[part 1 of 5: packages /MICROSAR/Dem_swc/DataTypes to /MICROSAR/Dem_swc/ComponentTypes]
AUTOSAR XML (schema 4-2-1)
package /MICROSAR/Dem_swc/DataTypes
  23 x impl type:
    Dem_EventIdType: range raw 1..65535, implementation-data-type=uint16
    Dem_RatioIdType: range raw 1..65535, implementation-data-type=uint16
    Dem_DTCStatusMaskType: range raw 0..255, implementation-data-type=uint8
    Dem_OperationCycleIdType: range raw 0..255, implementation-data-type=uint8
    Dem_DTCGroupType: range raw 0..16777215, implementation-data-type=uint32
    Dem_EventStatusType:
      compu {0=DEM_EVENT_STATUS_PASSED, 1=DEM_EVENT_STATUS_FAILED, 2=DEM_EVENT_STATUS_PREPASSED, 3=DEM_EVENT_STATUS_PREFAILED, 4=DEM_EVENT_STATUS_FDC_THRESHOLD_REACHED, 5=DEM_EVENT_STATUS_PASSED_CONDITIONS_NOT_FULFILLED, 6=DEM_EVENT_STATUS_FAILED_CONDITIONS_NOT_FULFILLED, 7=DEM_EVENT_STATUS_PREPASSED_CONDITIONS_NOT_FULFILLED, 8=DEM_EVENT_STATUS_PREFAILED_CONDITIONS_NOT_FULFILLED}
      range raw 0..255
      implementation-data-type=uint8
    Dem_InitMonitorReasonType: compu {1=DEM_INIT_MONITOR_CLEAR, 2=DEM_INIT_MONITOR_RESTART, 3=DEM_INIT_MONITOR_REENABLED, 4=DEM_INIT_MONITOR_STORAGE_REENABLED}, range raw 0..255, implementation-data-type=uint8
    Dem_DTCOriginType:
      compu {1=DEM_DTC_ORIGIN_PRIMARY_MEMORY, 2=DEM_DTC_ORIGIN_MIRROR_MEMORY, 3=DEM_DTC_ORIGIN_PERMANENT_MEMORY, 4=DEM_DTC_ORIGIN_OBD_RELEVANT_MEMORY, 5=DEM_DTC_ORIGIN_SECONDARY_MEMORY, 5=DEM_DTC_ORIGIN_USERDEFINED_MEMORY_10, 5=DEM_DTC_ORIGIN_USERDEFINED_MEMORY_11, 5=DEM_DTC_ORIGIN_USERDEFINED_MEMORY_12, 5=DEM_DTC_ORIGIN_USERDEFINED_MEMORY_13, 5=DEM_DTC_ORIGIN_USERDEFINED_MEMORY_14, 5=DEM_DTC_ORIGIN_USERDEFINED_MEMORY_15, 5=DEM_DTC_ORIGIN_USERDEFINED_MEMORY_16, 5=DEM_DTC_ORIGIN_USERDEFINED_MEMORY_17, 5=DEM_DTC_ORIGIN_USERDEFINED_MEMORY_18, 5=DEM_DTC_ORIGIN_USERDEFINED_MEMORY_19, 5=DEM_DTC_ORIGIN_USERDEFINED_MEMORY_1A, 5=DEM_DTC_ORIGIN_USERDEFINED_MEMORY_1B, 5=DEM_DTC_ORIGIN_USERDEFINED_MEMORY_1C, 5=DEM_DTC_ORIGIN_USERDEFINED_MEMORY_1D, 5=DEM_DTC_ORIGIN_USERDEFINED_MEMORY_1E, 5=DEM_DTC_ORIGIN_USERDEFINED_MEMORY_1F, 5=DEM_DTC_ORIGIN_USERDEFINED_MEMORY_20, 5=DEM_DTC_ORIGIN_USERDEFINED_MEMORY_21, 5=DEM_DTC_ORIGIN_USERDEFINED_MEMORY_22, 5=DEM_DTC_ORIGIN_USERDEFINED_MEMORY_23, 5=DEM_DTC_ORIGIN_USERDEFINED_MEMORY_24, 5=DEM_DTC_ORIGIN_USERDEFINED_MEMORY_25, 5=DEM_DTC_ORIGIN_USERDEFINED_MEMORY_26, 5=DEM_DTC_ORIGIN_USERDEFINED_MEMORY_27, 5=DEM_DTC_ORIGIN_USERDEFINED_MEMORY_28, 5=DEM_DTC_ORIGIN_USERDEFINED_MEMORY_29, 5=DEM_DTC_ORIGIN_USERDEFINED_MEMORY_2A, 5=DEM_DTC_ORIGIN_USERDEFINED_MEMORY_2B, 5=DEM_DTC_ORIGIN_USERDEFINED_MEMORY_2C, 5=DEM_DTC_ORIGIN_USERDEFINED_MEMORY_2D, 5=DEM_DTC_ORIGIN_USERDEFINED_MEMORY_2E, 5=DEM_DTC_ORIGIN_USERDEFINED_MEMORY_2F, 5=DEM_DTC_ORIGIN_USERDEFINED_MEMORY_30, 5=DEM_DTC_ORIGIN_USERDEFINED_MEMORY_31, 5=DEM_DTC_ORIGIN_USERDEFINED_MEMORY_32, 5=DEM_DTC_ORIGIN_USERDEFINED_MEMORY_33, 5=DEM_DTC_ORIGIN_USERDEFINED_MEMORY_34, 5=DEM_DTC_ORIGIN_USERDEFINED_MEMORY_35, 5=DEM_DTC_ORIGIN_USERDEFINED_MEMORY_36, 5=DEM_DTC_ORIGIN_USERDEFINED_MEMORY_37, 5=DEM_DTC_ORIGIN_USERDEFINED_MEMORY_38, 5=DEM_DTC_ORIGIN_USERDEFINED_MEMORY_39, 5=DEM_DTC_ORIGIN_USERDEFINED_MEMORY_3A, 5=DEM_DTC_ORIGIN_USERDEFINED_MEMORY_3B, 5=DEM_DTC_ORIGIN_USERDEFINED_MEMORY_3C, 5=DEM_DTC_ORIGIN_USERDEFINED_MEMORY_3D, 5=DEM_DTC_ORIGIN_USERDEFINED_MEMORY_3E, 5=DEM_DTC_ORIGIN_USERDEFINED_MEMORY_3F, 5=DEM_DTC_ORIGIN_USERDEFINED_MEMORY_40, 5=DEM_DTC_ORIGIN_USERDEFINED_MEMORY_41, 5=DEM_DTC_ORIGIN_USERDEFINED_MEMORY_42, 5=DEM_DTC_ORIGIN_USERDEFINED_MEMORY_43, 5=DEM_DTC_ORIGIN_USERDEFINED_MEMORY_44, 5=DEM_DTC_ORIGIN_USERDEFINED_MEMORY_45, 5=DEM_DTC_ORIGIN_USERDEFINED_MEMORY_46, 5=DEM_DTC_ORIGIN_USERDEFINED_MEMORY_47, 5=DEM_DTC_ORIGIN_USERDEFINED_MEMORY_48, 5=DEM_DTC_ORIGIN_USERDEFINED_MEMORY_49, 5=DEM_DTC_ORIGIN_USERDEFINED_MEMORY_4A, 5=DEM_DTC_ORIGIN_USERDEFINED_MEMORY_4B, 5=DEM_DTC_ORIGIN_USERDEFINED_MEMORY_4C, 5=DEM_DTC_ORIGIN_USERDEFINED_MEMORY_4D, 5=DEM_DTC_ORIGIN_USERDEFINED_MEMORY_4E, 5=DEM_DTC_ORIGIN_USERDEFINED_MEMORY_4F, 5=DEM_DTC_ORIGIN_USERDEFINED_MEMORY_50, 5=DEM_DTC_ORIGIN_USERDEFINED_MEMORY_51, 5=DEM_DTC_ORIGIN_USERDEFINED_MEMORY_52, 5=DEM_DTC_ORIGIN_USERDEFINED_MEMORY_53, 5=DEM_DTC_ORIGIN_USERDEFINED_MEMORY_54, 5=DEM_DTC_ORIGIN_USERDEFINED_MEMORY_55, 5=DEM_DTC_ORIGIN_USERDEFINED_MEMORY_56, 5=DEM_DTC_ORIGIN_USERDEFINED_MEMORY_57, 5=DEM_DTC_ORIGIN_USERDEFINED_MEMORY_58, 5=DEM_DTC_ORIGIN_USERDEFINED_MEMORY_59, 5=DEM_DTC_ORIGIN_USERDEFINED_MEMORY_5A, 5=DEM_DTC_ORIGIN_USERDEFINED_MEMORY_5B, 5=DEM_DTC_ORIGIN_USERDEFINED_MEMORY_5C, 5=DEM_DTC_ORIGIN_USERDEFINED_MEMORY_5D, 5=DEM_DTC_ORIGIN_USERDEFINED_MEMORY_5E, 5=DEM_DTC_ORIGIN_USERDEFINED_MEMORY_5F, 5=DEM_DTC_ORIGIN_USERDEFINED_MEMORY_60, 5=DEM_DTC_ORIGIN_USERDEFINED_MEMORY_61, 5=DEM_DTC_ORIGIN_USERDEFINED_MEMORY_62, 5=DEM_DTC_ORIGIN_USERDEFINED_MEMORY_63, 5=DEM_DTC_ORIGIN_USERDEFINED_MEMORY_64, 5=DEM_DTC_ORIGIN_USERDEFINED_MEMORY_65, 5=DEM_DTC_ORIGIN_USERDEFINED_MEMORY_66, 5=DEM_DTC_ORIGIN_USERDEFINED_MEMORY_67, 5=DEM_DTC_ORIGIN_USERDEFINED_MEMORY_68, 5=DEM_DTC_ORIGIN_USERDEFINED_MEMORY_69, 5=DEM_DTC_ORIGIN_USERDEFINED_MEMORY_6A, 5=DEM_DTC_ORIGIN_USERDEFINED_MEMORY_6B, 5=DEM_DTC_ORIGIN_USERDEFINED_MEMORY_6C, 5=DEM_DTC_ORIGIN_USERDEFINED_MEMORY_6D, 5=DEM_DTC_ORIGIN_USERDEFINED_MEMORY_6E, 5=DEM_DTC_ORIGIN_USERDEFINED_MEMORY_6F, 5=DEM_DTC_ORIGIN_USERDEFINED_MEMORY_70, 5=DEM_DTC_ORIGIN_USERDEFINED_MEMORY_71, 5=DEM_DTC_ORIGIN_USERDEFINED_MEMORY_72, 5=DEM_DTC_ORIGIN_USERDEFINED_MEMORY_73, 5=DEM_DTC_ORIGIN_USERDEFINED_MEMORY_74, 5=DEM_DTC_ORIGIN_USERDEFINED_MEMORY_75, 5=DEM_DTC_ORIGIN_USERDEFINED_MEMORY_76, 5=DEM_DTC_ORIGIN_USERDEFINED_MEMORY_77, 5=DEM_DTC_ORIGIN_USERDEFINED_MEMORY_78, 5=DEM_DTC_ORIGIN_USERDEFINED_MEMORY_79, 5=DEM_DTC_ORIGIN_USERDEFINED_MEMORY_7A, 5=DEM_DTC_ORIGIN_USERDEFINED_MEMORY_7B, 5=DEM_DTC_ORIGIN_USERDEFINED_MEMORY_7C, 5=DEM_DTC_ORIGIN_USERDEFINED_MEMORY_7D, 5=DEM_DTC_ORIGIN_USERDEFINED_MEMORY_7E, 5=DEM_DTC_ORIGIN_USERDEFINED_MEMORY_7F, 5=DEM_DTC_ORIGIN_USERDEFINED_MEMORY_80, 5=DEM_DTC_ORIGIN_USERDEFINED_MEMORY_81, 5=DEM_DTC_ORIGIN_USERDEFINED_MEMORY_82, 5=DEM_DTC_ORIGIN_USERDEFINED_MEMORY_83, 5=DEM_DTC_ORIGIN_USERDEFINED_MEMORY_84, 5=DEM_DTC_ORIGIN_USERDEFINED_MEMORY_85, 5=DEM_DTC_ORIGIN_USERDEFINED_MEMORY_86, 5=DEM_DTC_ORIGIN_USERDEFINED_MEMORY_87, 5=DEM_DTC_ORIGIN_USERDEFINED_MEMORY_88, 5=DEM_DTC_ORIGIN_USERDEFINED_MEMORY_89, 5=DEM_DTC_ORIGIN_USERDEFINED_MEMORY_8A, 5=DEM_DTC_ORIGIN_USERDEFINED_MEMORY_8B, 5=DEM_DTC_ORIGIN_USERDEFINED_MEMORY_8C, 5=DEM_DTC_ORIGIN_USERDEFINED_MEMORY_8D, 5=DEM_DTC_ORIGIN_USERDEFINED_MEMORY_8E, 5=DEM_DTC_ORIGIN_USERDEFINED_MEMORY_8F, 5=DEM_DTC_ORIGIN_USERDEFINED_MEMORY_90, 5=DEM_DTC_ORIGIN_USERDEFINED_MEMORY_91, 5=DEM_DTC_ORIGIN_USERDEFINED_MEMORY_92, 5=DEM_DTC_ORIGIN_USERDEFINED_MEMORY_93, 5=DEM_DTC_ORIGIN_USERDEFINED_MEMORY_94, 5=DEM_DTC_ORIGIN_USERDEFINED_MEMORY_95, 5=DEM_DTC_ORIGIN_USERDEFINED_MEMORY_96, 5=DEM_DTC_ORIGIN_USERDEFINED_MEMORY_97, 5=DEM_DTC_ORIGIN_USERDEFINED_MEMORY_98, 5=DEM_DTC_ORIGIN_USERDEFINED_MEMORY_99, 5=DEM_DTC_ORIGIN_USERDEFINED_MEMORY_9A, 5=DEM_DTC_ORIGIN_USERDEFINED_MEMORY_9B, 5=DEM_DTC_ORIGIN_USERDEFINED_MEMORY_9C, 5=DEM_DTC_ORIGIN_USERDEFINED_MEMORY_9D, 5=DEM_DTC_ORIGIN_USERDEFINED_MEMORY_9E, 5=DEM_DTC_ORIGIN_USERDEFINED_MEMORY_9F, 5=DEM_DTC_ORIGIN_USERDEFINED_MEMORY_A0, 5=DEM_DTC_ORIGIN_USERDEFINED_MEMORY_A1, 5=DEM_DTC_ORIGIN_USERDEFINED_MEMORY_A2, 5=DEM_DTC_ORIGIN_USERDEFINED_MEMORY_A3, 5=DEM_DTC_ORIGIN_USERDEFINED_MEMORY_A4, 5=DEM_DTC_ORIGIN_USERDEFINED_MEMORY_A5, 5=DEM_DTC_ORIGIN_USERDEFINED_MEMORY_A6, 5=DEM_DTC_ORIGIN_USERDEFINED_MEMORY_A7, 5=DEM_DTC_ORIGIN_USERDEFINED_MEMORY_A8, 5=DEM_DTC_ORIGIN_USERDEFINED_MEMORY_A9, 5=DEM_DTC_ORIGIN_USERDEFINED_MEMORY_AA, 5=DEM_DTC_ORIGIN_USERDEFINED_MEMORY_AB, 5=DEM_DTC_ORIGIN_USERDEFINED_MEMORY_AC, 5=DEM_DTC_ORIGIN_USERDEFINED_MEMORY_AD, 5=DEM_DTC_ORIGIN_USERDEFINED_MEMORY_AE, 5=DEM_DTC_ORIGIN_USERDEFINED_MEMORY_AF, 5=DEM_DTC_ORIGIN_USERDEFINED_MEMORY_B0, 5=DEM_DTC_ORIGIN_USERDEFINED_MEMORY_B1, 5=DEM_DTC_ORIGIN_USERDEFINED_MEMORY_B2, 5=DEM_DTC_ORIGIN_USERDEFINED_MEMORY_B3, 5=DEM_DTC_ORIGIN_USERDEFINED_MEMORY_B4, 5=DEM_DTC_ORIGIN_USERDEFINED_MEMORY_B5, 5=DEM_DTC_ORIGIN_USERDEFINED_MEMORY_B6, 5=DEM_DTC_ORIGIN_USERDEFINED_MEMORY_B7, 5=DEM_DTC_ORIGIN_USERDEFINED_MEMORY_B8, 5=DEM_DTC_ORIGIN_USERDEFINED_MEMORY_B9, 5=DEM_DTC_ORIGIN_USERDEFINED_MEMORY_BA, 5=DEM_DTC_ORIGIN_USERDEFINED_MEMORY_BB, 5=DEM_DTC_ORIGIN_USERDEFINED_MEMORY_BC, 5=DEM_DTC_ORIGIN_USERDEFINED_MEMORY_BD, 5=DEM_DTC_ORIGIN_USERDEFINED_MEMORY_BE, 5=DEM_DTC_ORIGIN_USERDEFINED_MEMORY_BF, 5=DEM_DTC_ORIGIN_USERDEFINED_MEMORY_C0, 5=DEM_DTC_ORIGIN_USERDEFINED_MEMORY_C1, 5=DEM_DTC_ORIGIN_USERDEFINED_MEMORY_C2, 5=DEM_DTC_ORIGIN_USERDEFINED_MEMORY_C3, 5=DEM_DTC_ORIGIN_USERDEFINED_MEMORY_C4, 5=DEM_DTC_ORIGIN_USERDEFINED_MEMORY_C5, 5=DEM_DTC_ORIGIN_USERDEFINED_MEMORY_C6, 5=DEM_DTC_ORIGIN_USERDEFINED_MEMORY_C7, 5=DEM_DTC_ORIGIN_USERDEFINED_MEMORY_C8, 5=DEM_DTC_ORIGIN_USERDEFINED_MEMORY_C9, 5=DEM_DTC_ORIGIN_USERDEFINED_MEMORY_CA, 5=DEM_DTC_ORIGIN_USERDEFINED_MEMORY_CB, 5=DEM_DTC_ORIGIN_USERDEFINED_MEMORY_CC, 5=DEM_DTC_ORIGIN_USERDEFINED_MEMORY_CD, 5=DEM_DTC_ORIGIN_USERDEFINED_MEMORY_CE, 5=DEM_DTC_ORIGIN_USERDEFINED_MEMORY_CF, 5=DEM_DTC_ORIGIN_USERDEFINED_MEMORY_D0, 5=DEM_DTC_ORIGIN_USERDEFINED_MEMORY_D1, 5=DEM_DTC_ORIGIN_USERDEFINED_MEMORY_D2, 5=DEM_DTC_ORIGIN_USERDEFINED_MEMORY_D3, 5=DEM_DTC_ORIGIN_USERDEFINED_MEMORY_D4, 5=DEM_DTC_ORIGIN_USERDEFINED_MEMORY_D5, 5=DEM_DTC_ORIGIN_USERDEFINED_MEMORY_D6, 5=DEM_DTC_ORIGIN_USERDEFINED_MEMORY_D7, 5=DEM_DTC_ORIGIN_USERDEFINED_MEMORY_D8, 5=DEM_DTC_ORIGIN_USERDEFINED_MEMORY_D9, 5=DEM_DTC_ORIGIN_USERDEFINED_MEMORY_DA, 5=DEM_DTC_ORIGIN_USERDEFINED_MEMORY_DB, 5=DEM_DTC_ORIGIN_USERDEFINED_MEMORY_DC, 5=DEM_DTC_ORIGIN_USERDEFINED_MEMORY_DD, 5=DEM_DTC_ORIGIN_USERDEFINED_MEMORY_DE, 5=DEM_DTC_ORIGIN_USERDEFINED_MEMORY_DF, 5=DEM_DTC_ORIGIN_USERDEFINED_MEMORY_E0, 5=DEM_DTC_ORIGIN_USERDEFINED_MEMORY_E1, 5=DEM_DTC_ORIGIN_USERDEFINED_MEMORY_E2, 5=DEM_DTC_ORIGIN_USERDEFINED_MEMORY_E3, 5=DEM_DTC_ORIGIN_USERDEFINED_MEMORY_E4, 5=DEM_DTC_ORIGIN_USERDEFINED_MEMORY_E5, 5=DEM_DTC_ORIGIN_USERDEFINED_MEMORY_E6, 5=DEM_DTC_ORIGIN_USERDEFINED_MEMORY_E7, 5=DEM_DTC_ORIGIN_USERDEFINED_MEMORY_E8, 5=DEM_DTC_ORIGIN_USERDEFINED_MEMORY_E9, 5=DEM_DTC_ORIGIN_USERDEFINED_MEMORY_EA, 5=DEM_DTC_ORIGIN_USERDEFINED_MEMORY_EB, 5=DEM_DTC_ORIGIN_USERDEFINED_MEMORY_EC, 5=DEM_DTC_ORIGIN_USERDEFINED_MEMORY_ED, 5=DEM_DTC_ORIGIN_USERDEFINED_MEMORY_EE, 5=DEM_DTC_ORIGIN_USERDEFINED_MEMORY_EF, 5=DEM_DTC_ORIGIN_USERDEFINED_MEMORY_F0, 5=DEM_DTC_ORIGIN_USERDEFINED_MEMORY_F1, 5=DEM_DTC_ORIGIN_USERDEFINED_MEMORY_F2, 5=DEM_DTC_ORIGIN_USERDEFINED_MEMORY_F3, 5=DEM_DTC_ORIGIN_USERDEFINED_MEMORY_F4, 5=DEM_DTC_ORIGIN_USERDEFINED_MEMORY_F5, 5=DEM_DTC_ORIGIN_USERDEFINED_MEMORY_F6, 5=DEM_DTC_ORIGIN_USERDEFINED_MEMORY_F7, 5=DEM_DTC_ORIGIN_USERDEFINED_MEMORY_F8, 5=DEM_DTC_ORIGIN_USERDEFINED_MEMORY_F9, 5=DEM_DTC_ORIGIN_USERDEFINED_MEMORY_FA, 5=DEM_DTC_ORIGIN_USERDEFINED_MEMORY_FB, 5=DEM_DTC_ORIGIN_USERDEFINED_MEMORY_FC, 5=DEM_DTC_ORIGIN_USERDEFINED_MEMORY_FD, 5=DEM_DTC_ORIGIN_USERDEFINED_MEMORY_FE, 5=DEM_DTC_ORIGIN_USERDEFINED_MEMORY_FF}
      range raw 0..65535
      implementation-data-type=uint16
    Dem_DTCFormatType: compu {0=DEM_DTC_FORMAT_OBD, 1=DEM_DTC_FORMAT_UDS, 2=DEM_DTC_FORMAT_J1939}, range raw 0..255, implementation-data-type=uint8
    Dem_OperationCycleStateType: compu {0=DEM_CYCLE_STATE_START, 1=DEM_CYCLE_STATE_END}, range raw 0..255, implementation-data-type=uint8
    Dem_IndicatorStatusType: compu {0=DEM_INDICATOR_OFF, 1=DEM_INDICATOR_CONTINUOUS, 2=DEM_INDICATOR_BLINKING, 3=DEM_INDICATOR_BLINK_CONT, 4=DEM_INDICATOR_SLOW_FLASH, 5=DEM_INDICATOR_FAST_FLASH, 6=DEM_INDICATOR_ON_DEMAND, 7=DEM_INDICATOR_SHORT}, range raw 0..255, implementation-data-type=uint8
    Dem_DTCKindType: compu {1=DEM_DTC_KIND_ALL_DTCS, 2=DEM_DTC_KIND_EMISSION_REL_DTCS}, range raw 0..255, implementation-data-type=uint8
    Dem_IumprDenomCondIdType: compu {1=DEM_IUMPR_GENERAL_DENOMINATOR, 2=DEM_IUMPR_DEN_COND_COLDSTART, 3=DEM_IUMPR_DEN_COND_EVAP, 4=DEM_IUMPR_DEN_COND_500MI}, range raw 0..255, implementation-data-type=uint8
    Dem_IumprDenomCondStatusType: compu {0=DEM_IUMPR_DEN_STATUS_NOT_REACHED, 1=DEM_IUMPR_DEN_STATUS_REACHED, 2=DEM_IUMPR_DEN_STATUS_INHIBITED}, range raw 0..255, implementation-data-type=uint8
    Dem_DebounceResetStatusType: compu {0=DEM_DEBOUNCE_STATUS_FREEZE, 1=DEM_DEBOUNCE_STATUS_RESET}, range raw 0..255, implementation-data-type=uint8
    Dem_IumprReadinessGroupType:
      compu {0=DEM_IUMPR_BOOSTPRS, 1=DEM_IUMPR_CAT1, 2=DEM_IUMPR_CAT2, 3=DEM_IUMPR_EGR, 4=DEM_IUMPR_EGSENSOR, 5=DEM_IUMPR_EVAP, 6=DEM_IUMPR_NMHCCAT, 7=DEM_IUMPR_NOXADSORB, 8=DEM_IUMPR_NOXCAT, 9=DEM_IUMPR_OXS1, 10=DEM_IUMPR_OXS2, 11=DEM_IUMPR_PMFILTER, 12=DEM_IUMPR_PRIVATE, 13=DEM_IUMPR_SAIR, 14=DEM_IUMPR_SECOXS1, 15=DEM_IUMPR_SECOXS2, 16=DEM_IUMPR_FLSYS, 255=DEM_IUMPR_ALLGROUPS}
      range raw 0..255
      implementation-data-type=uint8
    Dem_DTRControlType: compu {0=DEM_DTR_CTL_NORMAL, 1=DEM_DTR_CTL_NO_MAX, 2=DEM_DTR_CTL_NO_MIN, 3=DEM_DTR_CTL_RESET, 4=DEM_DTR_CTL_INVISIBLE}, range raw 0..255, implementation-data-type=uint8
    Dem_DebouncingStateType: compu {mask 1: 1=DEM_TEMPORARILY_DEFECTIVE, mask 2: 2=DEM_FINALLY_DEFECTIVE, mask 4: 4=DEM_TEMPORARILY_HEALED, mask 8: 8=DEM_TEST_COMPLETE, mask 16: 16=DEM_DTR_UPDATE}, range raw 0..255, implementation-data-type=uint8
    Dem_DTCSeverityType:
      compu {mask 255: 0=DEM_SEVERITY_NO_SEVERITY, mask 31: 2=DEM_SEVERITY_WWHOBD_CLASS_A, mask 31: 4=DEM_SEVERITY_WWHOBD_CLASS_B1, mask 31: 8=DEM_SEVERITY_WWHOBD_CLASS_B2, mask 31: 16=DEM_SEVERITY_WWHOBD_CLASS_C, mask 31: 1=DEM_SEVERITY_WWHOBD_CLASS_NO_CLASS, mask 224: 64=DEM_SEVERITY_CHECK_AT_NEXT_HALT, mask 224: 128=DEM_SEVERITY_CHECK_IMMEDIATELY, mask 224: 32=DEM_SEVERITY_MAINTENANCE_ONLY}
      range raw 0..255
      implementation-data-type=uint8
    Dem_UdsStatusByteType: compu {mask 1: 1=DEM_UDS_STATUS_TF, mask 2: 2=DEM_UDS_STATUS_TFTOC, mask 4: 4=DEM_UDS_STATUS_PDTC, mask 8: 8=DEM_UDS_STATUS_CDTC, mask 16: 16=DEM_UDS_STATUS_TNCSLC, mask 32: 32=DEM_UDS_STATUS_TFSLC, mask 64: 64=DEM_UDS_STATUS_TNCTOC, mask 128: 128=DEM_UDS_STATUS_WIR}, range raw 0..255, implementation-data-type=uint8
    Dem_MonitorStatusType: compu {mask 1: 1=DEM_MONITOR_STATUS_TF, mask 2: 2=DEM_MONITOR_STATUS_TNCTOC}, range raw 0..255, implementation-data-type=uint8
    Dem_MaxDataValueType: category=ARRAY, sw-calibration-access=READ-ONLY
      element Dem_MaxDataValueTypeElement: array-size=2, array-size-semantics=FIXED-SIZE, implementation-data-type=uint8
    DataArrayType_uint8_2: category=ARRAY, sw-calibration-access=READ-ONLY
      element DataArrayType_uint8_2Element: array-size=2, array-size-semantics=FIXED-SIZE, implementation-data-type=uint8
package /MICROSAR/Dem_swc/Interfaces
  8 x client server interface, all with is-service=true, service-kind=DIAGNOSTIC-EVENT-MANAGER:
    DemServices
      operation GetPostRunRequested: possible-error=DemServices/E_NOT_OK
        arg IsRequested: type=boolean, direction=OUT
      operation GetDTCStatusAvailabilityMask: possible-error=DemServices/E_NOT_OK
        arg ClientId: type=uint8, direction=IN
        arg DTCStatusMask: type=uint8, direction=OUT
      error E_NOT_OK: error-code=1
    ClearDTC
      operation ClearDTC: possible-error=[ClearDTC/E_NOT_OK, DEM_CLEAR_FAILED, DEM_PENDING, DEM_CLEAR_BUSY, DEM_CLEAR_MEMORY_ERROR, DEM_WRONG_DTC, DEM_WRONG_DTCORIGIN]
      operation SelectDTC: possible-error=[ClearDTC/E_OK, ClearDTC/E_NOT_OK]
        arg DTC: type=uint32, direction=IN
        arg DTCFormat: type=Dem_DTCFormatType, direction=IN
        arg DTCOrigin: type=Dem_DTCOriginType, direction=IN
      8 x error:
        E_OK: error-code=0
        E_NOT_OK: error-code=1
        DEM_CLEAR_FAILED: error-code=7
        DEM_PENDING: error-code=4
        DEM_CLEAR_BUSY: error-code=5
        DEM_CLEAR_MEMORY_ERROR: error-code=6
        DEM_WRONG_DTC: error-code=8
        DEM_WRONG_DTCORIGIN: error-code=9
    EvMemOverflowIndication
      operation GetEventMemoryOverflow: possible-error=EvMemOverflowIndication/E_NOT_OK
        arg OverflowIndication: type=boolean, direction=OUT
      operation GetNumberOfEventMemoryEntries: possible-error=EvMemOverflowIndication/E_NOT_OK
        arg NumberOfEventMemoryEntries: type=uint8, direction=OUT
      error E_NOT_OK: error-code=1
    GeneralDiagnosticInfo
      11 x operation:
        GetEventUdsStatus: possible-error=GeneralDiagnosticInfo/E_NOT_OK
          arg EventId: type=Dem_EventIdType, direction=IN
          arg UDSStatusByte: type=Dem_UdsStatusByteType, direction=OUT
        GetEventStatus: possible-error=GeneralDiagnosticInfo/E_NOT_OK
          arg EventId: type=Dem_EventIdType, direction=IN
          arg UDSStatusByte: type=Dem_UdsStatusByteType, direction=OUT
        GetEventFailed: possible-error=GeneralDiagnosticInfo/E_NOT_OK
          arg EventId: type=Dem_EventIdType, direction=IN
          arg EventFailed: type=boolean, direction=OUT
        GetEventTested: possible-error=GeneralDiagnosticInfo/E_NOT_OK
          arg EventId: type=Dem_EventIdType, direction=IN
          arg EventTested: type=boolean, direction=OUT
        GetDTCOfEvent: possible-error=[GeneralDiagnosticInfo/E_NOT_OK, GeneralDiagnosticInfo/DEM_E_NO_DTC_AVAILABLE]
          arg EventId: type=Dem_EventIdType, direction=IN
          arg DTCFormat: type=Dem_DTCFormatType, direction=IN
          arg DTCOfEvent: type=uint32, direction=OUT
        GetFaultDetectionCounter: possible-error=[GeneralDiagnosticInfo/E_NOT_OK, GeneralDiagnosticInfo/DEM_E_NO_FDC_AVAILABLE]
          arg EventId: type=Dem_EventIdType, direction=IN
          arg FaultDetectionCounter: type=sint8, direction=OUT
        GetEventFreezeFrameDataEx: possible-error=[GeneralDiagnosticInfo/E_NOT_OK, GeneralDiagnosticInfo/DEM_BUFFER_TOO_SMALL, GeneralDiagnosticInfo/DEM_NO_SUCH_ELEMENT]
          5 x arg:
            EventId: type=Dem_EventIdType, direction=IN
            RecordNumber: type=uint8, direction=IN
            DataId: type=uint16, direction=IN
            DestBuffer: type=Dem_MaxDataValueType, direction=OUT
            BufSize: type=uint16, direction=INOUT
        GetEventExtendedDataRecordEx: possible-error=[GeneralDiagnosticInfo/E_NOT_OK, GeneralDiagnosticInfo/DEM_BUFFER_TOO_SMALL, GeneralDiagnosticInfo/DEM_NO_SUCH_ELEMENT]
          4 x arg:
            EventId: type=Dem_EventIdType, direction=IN
            RecordNumber: type=uint8, direction=IN
            DestBuffer: type=Dem_MaxDataValueType, direction=OUT
            BufSize: type=uint16, direction=INOUT
        GetEventEnableCondition: possible-error=GeneralDiagnosticInfo/E_NOT_OK
          arg EventId: type=Dem_EventIdType, direction=IN
          arg ConditionFullfilled: type=boolean, direction=OUT
        GetDebouncingOfEvent: possible-error=GeneralDiagnosticInfo/E_NOT_OK
          arg EventId: type=Dem_EventIdType, direction=IN
          arg DebouncingState: type=Dem_DebouncingStateType, direction=OUT
        GetMonitorStatus: possible-error=GeneralDiagnosticInfo/E_NOT_OK
          arg EventId: type=Dem_EventIdType, direction=IN
          arg MonitorStatus: type=Dem_MonitorStatusType, direction=OUT
      5 x error:
        E_NOT_OK: error-code=1
        DEM_E_NO_DTC_AVAILABLE: error-code=10
        DEM_E_NO_FDC_AVAILABLE: error-code=14
        DEM_BUFFER_TOO_SMALL: error-code=21
        DEM_NO_SUCH_ELEMENT: error-code=48
    OperationCycle
      operation GetOperationCycleState: possible-error=[OperationCycle/E_OK, OperationCycle/E_NOT_OK]
        arg CycleState: type=Dem_OperationCycleStateType, direction=OUT
      operation SetOperationCycleState: possible-error=[OperationCycle/E_OK, OperationCycle/E_NOT_OK]
        arg CycleState: type=Dem_OperationCycleStateType, direction=IN
      error E_OK: error-code=0
      error E_NOT_OK: error-code=1
    DiagnosticInfo
      11 x operation:
        GetEventUdsStatus: possible-error=DiagnosticInfo/E_NOT_OK
          arg UDSStatusByte: type=Dem_UdsStatusByteType, direction=OUT
        GetEventStatus: possible-error=DiagnosticInfo/E_NOT_OK
          arg UDSStatusByte: type=Dem_UdsStatusByteType, direction=OUT
        GetEventFailed: possible-error=DiagnosticInfo/E_NOT_OK
          arg EventFailed: type=boolean, direction=OUT
        GetEventTested: possible-error=DiagnosticInfo/E_NOT_OK
          arg EventTested: type=boolean, direction=OUT
        GetDTCOfEvent: possible-error=[DiagnosticInfo/E_NOT_OK, DiagnosticInfo/DEM_E_NO_DTC_AVAILABLE]
          arg DTCFormat: type=Dem_DTCFormatType, direction=IN
          arg DTCOfEvent: type=uint32, direction=OUT
        GetFaultDetectionCounter: possible-error=[DiagnosticInfo/E_NOT_OK, DiagnosticInfo/DEM_E_NO_FDC_AVAILABLE]
          arg FaultDetectionCounter: type=sint8, direction=OUT
        GetEventFreezeFrameDataEx: possible-error=[DiagnosticInfo/E_NOT_OK, DiagnosticInfo/DEM_BUFFER_TOO_SMALL, DiagnosticInfo/DEM_NO_SUCH_ELEMENT]
          4 x arg:
            RecordNumber: type=uint8, direction=IN
            DataId: type=uint16, direction=IN
            DestBuffer: type=Dem_MaxDataValueType, direction=OUT
            BufSize: type=uint16, direction=INOUT
        GetEventExtendedDataRecordEx: possible-error=[DiagnosticInfo/E_NOT_OK, DiagnosticInfo/DEM_BUFFER_TOO_SMALL, DiagnosticInfo/DEM_NO_SUCH_ELEMENT]
          arg RecordNumber: type=uint8, direction=IN
          arg DestBuffer: type=Dem_MaxDataValueType, direction=OUT
          arg BufSize: type=uint16, direction=INOUT
        GetEventEnableCondition: possible-error=DiagnosticInfo/E_NOT_OK
          arg ConditionFullfilled: type=boolean, direction=OUT
        GetDebouncingOfEvent: possible-error=DiagnosticInfo/E_NOT_OK
          arg DebouncingState: type=Dem_DebouncingStateType, direction=OUT
        GetMonitorStatus: possible-error=DiagnosticInfo/E_NOT_OK
          arg MonitorStatus: type=Dem_MonitorStatusType, direction=OUT
      5 x error:
        E_NOT_OK: error-code=1
        DEM_E_NO_DTC_AVAILABLE: error-code=10
        DEM_E_NO_FDC_AVAILABLE: error-code=14
        DEM_BUFFER_TOO_SMALL: error-code=21
        DEM_NO_SUCH_ELEMENT: error-code=48
    DiagnosticMonitor
      11 x operation:
        SetEventStatus: possible-error=DiagnosticMonitor/E_NOT_OK
          arg EventStatus: type=Dem_EventStatusType, direction=IN
        ResetEventStatus: possible-error=DiagnosticMonitor/E_NOT_OK
        ResetEventDebounceStatus: possible-error=DiagnosticMonitor/E_NOT_OK
          arg DebounceResetStatus: type=Dem_DebounceResetStatusType, direction=IN
        GetEventUdsStatus: possible-error=DiagnosticMonitor/E_NOT_OK
          arg UDSStatusByte: type=Dem_UdsStatusByteType, direction=OUT
        GetEventStatus: possible-error=DiagnosticMonitor/E_NOT_OK
          arg UDSStatusByte: type=Dem_UdsStatusByteType, direction=OUT
        GetEventFailed: possible-error=DiagnosticMonitor/E_NOT_OK
          arg EventFailed: type=boolean, direction=OUT
        GetEventTested: possible-error=DiagnosticMonitor/E_NOT_OK
          arg EventTested: type=boolean, direction=OUT
        GetDTCOfEvent: possible-error=[DiagnosticMonitor/E_NOT_OK, DiagnosticMonitor/DEM_E_NO_DTC_AVAILABLE]
          arg DTCFormat: type=Dem_DTCFormatType, direction=IN
          arg DTCOfEvent: type=uint32, direction=OUT
        GetFaultDetectionCounter: possible-error=[DiagnosticMonitor/E_NOT_OK, DiagnosticMonitor/DEM_E_NO_FDC_AVAILABLE]
          arg FaultDetectionCounter: type=sint8, direction=OUT
        GetEventFreezeFrameDataEx: possible-error=[DiagnosticMonitor/E_NOT_OK, DiagnosticMonitor/DEM_BUFFER_TOO_SMALL, DiagnosticMonitor/DEM_NO_SUCH_ELEMENT]
          4 x arg:
            RecordNumber: type=uint8, direction=IN
            DataId: type=uint16, direction=IN
            DestBuffer: type=Dem_MaxDataValueType, direction=OUT
            BufSize: type=uint16, direction=INOUT
        GetEventExtendedDataRecordEx: possible-error=[DiagnosticMonitor/E_NOT_OK, DiagnosticMonitor/DEM_BUFFER_TOO_SMALL, DiagnosticMonitor/DEM_NO_SUCH_ELEMENT]
          arg RecordNumber: type=uint8, direction=IN
          arg DestBuffer: type=Dem_MaxDataValueType, direction=OUT
          arg BufSize: type=uint16, direction=INOUT
      5 x error:
        E_NOT_OK: error-code=1
        DEM_E_NO_DTC_AVAILABLE: error-code=10
        DEM_E_NO_FDC_AVAILABLE: error-code=14
        DEM_BUFFER_TOO_SMALL: error-code=21
        DEM_NO_SUCH_ELEMENT: error-code=48
    CSDataServices_DemDataElementClass_StartApplication
      operation ReadData: possible-error=CSDataServices_DemDataElementClass_StartApplication/E_NOT_OK
        arg Data: type=DataArrayType_uint8_2, direction=OUT
      error E_NOT_OK: error-code=1
package /MICROSAR/Dem_swc/ComponentTypes
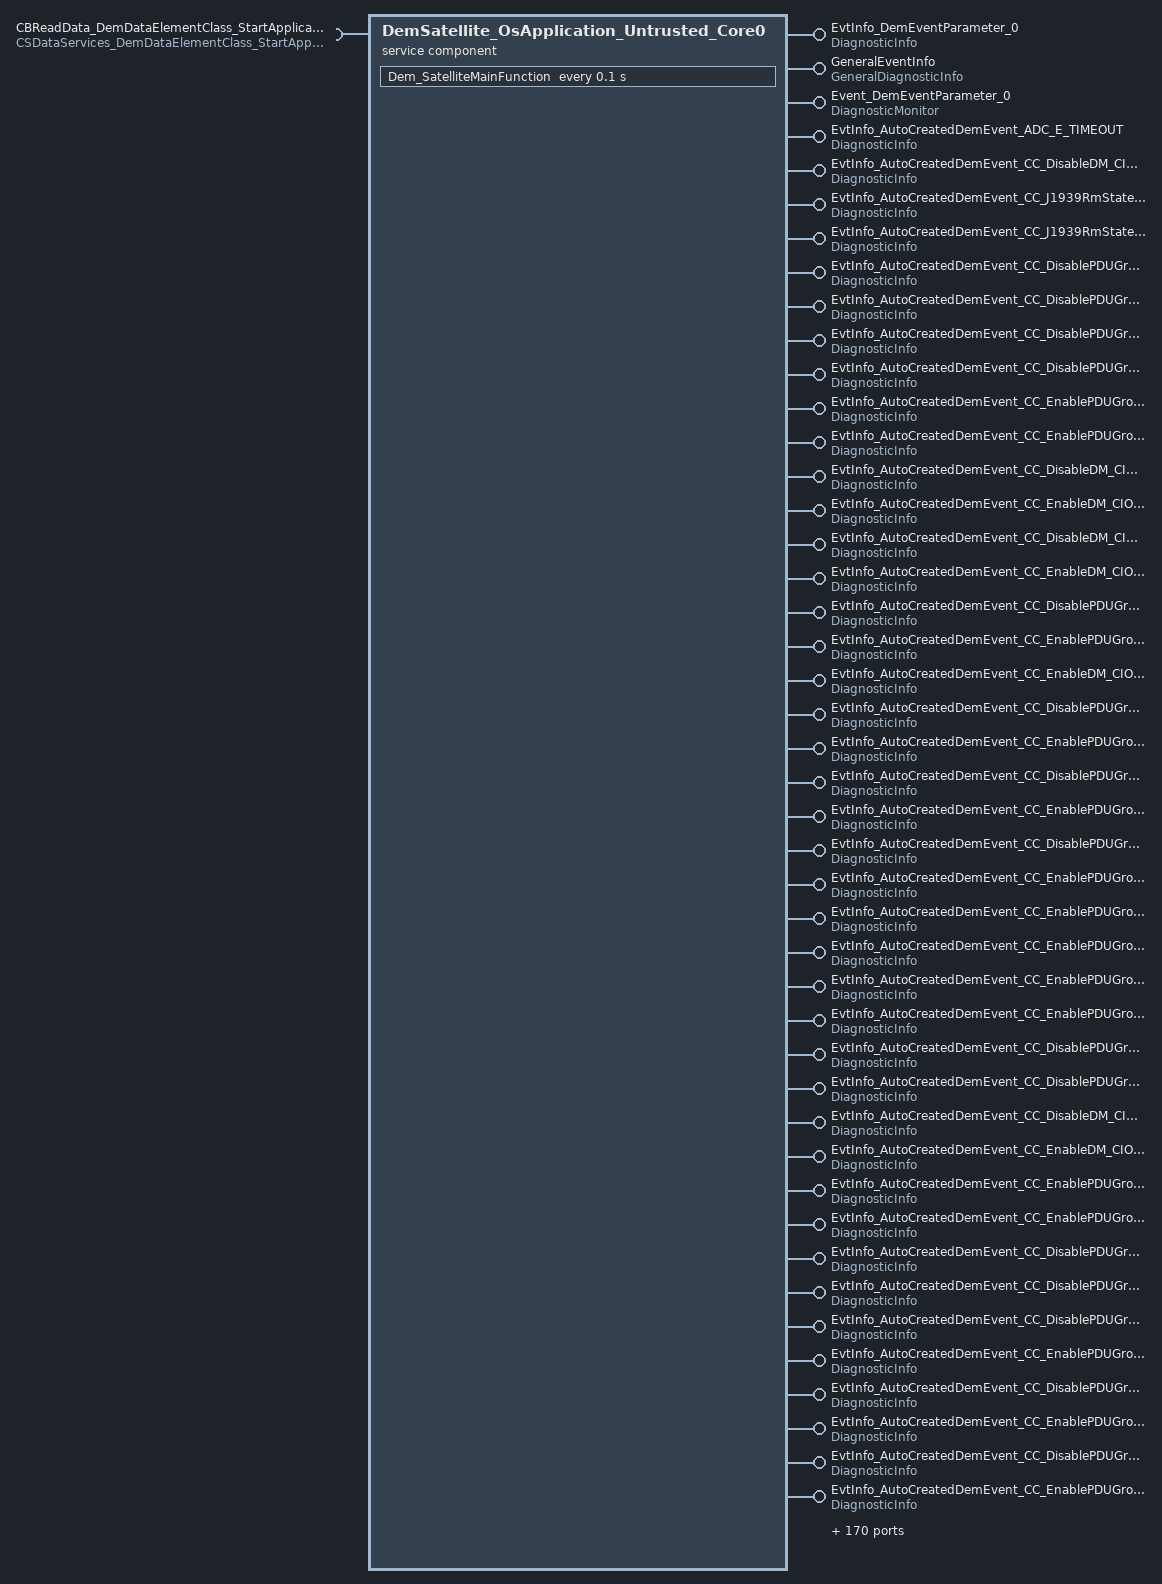
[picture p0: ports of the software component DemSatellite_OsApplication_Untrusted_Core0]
  service sw component type DemSatellite_OsApplication_Untrusted_Core0: category=SERVICE_COMPONENT
    214 x provide port:
      EvtInfo_DemEventParameter_0: provided-interface=DiagnosticInfo
      GeneralEventInfo: provided-interface=GeneralDiagnosticInfo
      Event_DemEventParameter_0: provided-interface=DiagnosticMonitor
      EvtInfo_AutoCreatedDemEvent_ADC_E_TIMEOUT: provided-interface=DiagnosticInfo
      EvtInfo_AutoCreatedDemEvent_CC_DisableDM_CIOM_oCabSubnet_Rx_063a5fbc_BswMReportFailToDemRef: provided-interface=DiagnosticInfo
      EvtInfo_AutoCreatedDemEvent_CC_J1939RmStateSwitch_CN_Backbone1J1939_0b1f4bae_CIOM_4d5cd289_J1939RM_STATE_OFFLINE_BswMRe_5a5b15b8: provided-interface=DiagnosticInfo
      EvtInfo_AutoCreatedDemEvent_CC_J1939RmStateSwitch_CN_Backbone1J1939_0b1f4bae_CIOM_4d5cd289_J1939RM_STATE_ONLINE_BswMRep_ec959aed: provided-interface=DiagnosticInfo
      EvtInfo_AutoCreatedDemEvent_CC_DisablePDUGroup_CIOM_oLIN04_Tx_04202f7b_BswMReportFailToDemRef: provided-interface=DiagnosticInfo
      EvtInfo_AutoCreatedDemEvent_CC_DisablePDUGroup_CIOM_oLIN04_Rx_527a88fd_BswMReportFailToDemRef: provided-interface=DiagnosticInfo
      EvtInfo_AutoCreatedDemEvent_CC_DisablePDUGroup_CIOM_oLIN01_Tx_33fedf49_BswMReportFailToDemRef: provided-interface=DiagnosticInfo
      EvtInfo_AutoCreatedDemEvent_CC_DisablePDUGroup_CIOM_oLIN01_Rx_65a478cf_BswMReportFailToDemRef: provided-interface=DiagnosticInfo
      EvtInfo_AutoCreatedDemEvent_CC_EnablePDUGroup_CIOM_oLIN04_Tx_04202f7b_BswMReportFailToDemRef: provided-interface=DiagnosticInfo
      EvtInfo_AutoCreatedDemEvent_CC_EnablePDUGroup_CIOM_oLIN04_Rx_527a88fd_BswMReportFailToDemRef: provided-interface=DiagnosticInfo
      EvtInfo_AutoCreatedDemEvent_CC_DisableDM_CIOM_oBackbone2_Rx_4e624434_BswMReportFailToDemRef: provided-interface=DiagnosticInfo
      EvtInfo_AutoCreatedDemEvent_CC_EnableDM_CIOM_oBackbone2_Rx_4e624434_BswMReportFailToDemRef: provided-interface=DiagnosticInfo
      EvtInfo_AutoCreatedDemEvent_CC_DisableDM_CIOM_oSecuritySubnet_Rx_3a3c1dbc_BswMReportFailToDemRef: provided-interface=DiagnosticInfo
      EvtInfo_AutoCreatedDemEvent_CC_EnableDM_CIOM_oSecuritySubnet_Rx_3a3c1dbc_BswMReportFailToDemRef: provided-interface=DiagnosticInfo
      EvtInfo_AutoCreatedDemEvent_CC_DisablePDUGroup_CIOM_oCabSubnet_Tx_5060f83a_BswMReportFailToDemRef: provided-interface=DiagnosticInfo
      EvtInfo_AutoCreatedDemEvent_CC_EnablePDUGroup_CIOM_oCabSubnet_Tx_5060f83a_BswMReportFailToDemRef: provided-interface=DiagnosticInfo
      EvtInfo_AutoCreatedDemEvent_CC_EnableDM_CIOM_oCabSubnet_Rx_063a5fbc_BswMReportFailToDemRef: provided-interface=DiagnosticInfo
      EvtInfo_AutoCreatedDemEvent_CC_DisablePDUGroup_CIOM_oBackbone2_Tx_1838e3b2_BswMReportFailToDemRef: provided-interface=DiagnosticInfo
      EvtInfo_AutoCreatedDemEvent_CC_EnablePDUGroup_CIOM_oBackbone2_Tx_1838e3b2_BswMReportFailToDemRef: provided-interface=DiagnosticInfo
      EvtInfo_AutoCreatedDemEvent_CC_DisablePDUGroup_CIOM_oBackbone2_Rx_4e624434_BswMReportFailToDemRef: provided-interface=DiagnosticInfo
      EvtInfo_AutoCreatedDemEvent_CC_EnablePDUGroup_CIOM_oBackbone2_Rx_4e624434_BswMReportFailToDemRef: provided-interface=DiagnosticInfo
      EvtInfo_AutoCreatedDemEvent_CC_DisablePDUGroup_CIOM_oBackbone1J1939_Rx_BC_405bc776_BswMReportFailToDemRef: provided-interface=DiagnosticInfo
      EvtInfo_AutoCreatedDemEvent_CC_EnablePDUGroup_CIOM_oBackbone1J1939_Rx_BC_405bc776_BswMReportFailToDemRef: provided-interface=DiagnosticInfo
      EvtInfo_AutoCreatedDemEvent_CC_EnablePDUGroup_CIOM_oLIN02_Tx_214b70a7_BswMReportFailToDemRef: provided-interface=DiagnosticInfo
      EvtInfo_AutoCreatedDemEvent_CC_EnablePDUGroup_CIOM_oLIN02_Rx_7711d721_BswMReportFailToDemRef: provided-interface=DiagnosticInfo
      EvtInfo_AutoCreatedDemEvent_CC_EnablePDUGroup_CIOM_oLIN01_Tx_33fedf49_BswMReportFailToDemRef: provided-interface=DiagnosticInfo
      EvtInfo_AutoCreatedDemEvent_CC_EnablePDUGroup_CIOM_oLIN01_Rx_65a478cf_BswMReportFailToDemRef: provided-interface=DiagnosticInfo
      EvtInfo_AutoCreatedDemEvent_CC_DisablePDUGroup_CIOM_oLIN03_Tx_99f717c2_BswMReportFailToDemRef: provided-interface=DiagnosticInfo
      EvtInfo_AutoCreatedDemEvent_CC_DisablePDUGroup_CIOM_oLIN03_Rx_cfadb044_BswMReportFailToDemRef: provided-interface=DiagnosticInfo
      EvtInfo_AutoCreatedDemEvent_CC_DisableDM_CIOM_oFMSNet_Rx_BC_dd2c1510_BswMReportFailToDemRef: provided-interface=DiagnosticInfo
      EvtInfo_AutoCreatedDemEvent_CC_EnableDM_CIOM_oFMSNet_Rx_BC_dd2c1510_BswMReportFailToDemRef: provided-interface=DiagnosticInfo
      EvtInfo_AutoCreatedDemEvent_CC_EnablePDUGroup_CIOM_oLIN03_Tx_99f717c2_BswMReportFailToDemRef: provided-interface=DiagnosticInfo
      EvtInfo_AutoCreatedDemEvent_CC_EnablePDUGroup_CIOM_oLIN03_Rx_cfadb044_BswMReportFailToDemRef: provided-interface=DiagnosticInfo
      EvtInfo_AutoCreatedDemEvent_CC_DisablePDUGroup_CIOM_oLIN02_Tx_214b70a7_BswMReportFailToDemRef: provided-interface=DiagnosticInfo
      EvtInfo_AutoCreatedDemEvent_CC_DisablePDUGroup_CIOM_oLIN02_Rx_7711d721_BswMReportFailToDemRef: provided-interface=DiagnosticInfo
      EvtInfo_AutoCreatedDemEvent_CC_DisablePDUGroup_CIOM_oCabSubnet_Rx_063a5fbc_BswMReportFailToDemRef: provided-interface=DiagnosticInfo
      EvtInfo_AutoCreatedDemEvent_CC_EnablePDUGroup_CIOM_oCabSubnet_Rx_063a5fbc_BswMReportFailToDemRef: provided-interface=DiagnosticInfo
      EvtInfo_AutoCreatedDemEvent_CC_DisablePDUGroup_CIOM_oFMSNet_Rx_BC_dd2c1510_BswMReportFailToDemRef: provided-interface=DiagnosticInfo
      EvtInfo_AutoCreatedDemEvent_CC_EnablePDUGroup_CIOM_oFMSNet_Rx_BC_dd2c1510_BswMReportFailToDemRef: provided-interface=DiagnosticInfo
      EvtInfo_AutoCreatedDemEvent_CC_DisablePDUGroup_CIOM_oSecuritySubnet_Rx_3a3c1dbc_BswMReportFailToDemRef: provided-interface=DiagnosticInfo
      EvtInfo_AutoCreatedDemEvent_CC_EnablePDUGroup_CIOM_oSecuritySubnet_Rx_3a3c1dbc_BswMReportFailToDemRef: provided-interface=DiagnosticInfo
      EvtInfo_AutoCreatedDemEvent_CC_DisablePDUGroup_CIOM_oFMSNet_Tx_0x31_BC_38fc8c7d_BswMReportFailToDemRef: provided-interface=DiagnosticInfo
      EvtInfo_AutoCreatedDemEvent_CC_EnablePDUGroup_CIOM_oFMSNet_Tx_0x31_BC_38fc8c7d_BswMReportFailToDemRef: provided-interface=DiagnosticInfo
      EvtInfo_AutoCreatedDemEvent_CC_DisablePDUGroup_CIOM_oSecuritySubnet_Tx_6c66ba3a_BswMReportFailToDemRef: provided-interface=DiagnosticInfo
      EvtInfo_AutoCreatedDemEvent_CC_EnablePDUGroup_CIOM_oSecuritySubnet_Tx_6c66ba3a_BswMReportFailToDemRef: provided-interface=DiagnosticInfo
      EvtInfo_AutoCreatedDemEvent_CC_DisablePDUGroup_CIOM_oLIN00_Tx_8b42b82c_BswMReportFailToDemRef: provided-interface=DiagnosticInfo
      EvtInfo_AutoCreatedDemEvent_CC_EnablePDUGroup_CIOM_oLIN00_Rx_dd181faa_BswMReportFailToDemRef: provided-interface=DiagnosticInfo
      EvtInfo_AutoCreatedDemEvent_ESH_Action_ComMCheckPendingRequests_BswMReportFailToDemRef: provided-interface=DiagnosticInfo
      EvtInfo_AutoCreatedDemEvent_CC_DisableDM_CIOM_oBackbone1J1939_Rx_BC_405bc776_BswMReportFailToDemRef: provided-interface=DiagnosticInfo
      EvtInfo_AutoCreatedDemEvent_CC_DisablePDUGroup_CIOM_oLIN00_Rx_dd181faa_BswMReportFailToDemRef: provided-interface=DiagnosticInfo
      EvtInfo_AutoCreatedDemEvent_CC_EnablePDUGroup_CIOM_oLIN00_Tx_8b42b82c_BswMReportFailToDemRef: provided-interface=DiagnosticInfo
      EvtInfo_AutoCreatedDemEvent_ESH_Action_EnterExclusiveArea_BswMReportFailToDemRef: provided-interface=DiagnosticInfo
      EvtInfo_AutoCreatedDemEvent_ESH_RunToPostRunNested_BswMReportFailToDemRef: provided-interface=DiagnosticInfo
      EvtInfo_AutoCreatedDemEvent_CC_EnableDM_CIOM_oBackbone1J1939_Rx_BC_405bc776_BswMReportFailToDemRef: provided-interface=DiagnosticInfo
      EvtInfo_AutoCreatedDemEvent_CC_DisablePDUGroup_CIOM_oBackbone1J1939_Tx_0x31_BC_3782f500_BswMReportFailToDemRef: provided-interface=DiagnosticInfo
      EvtInfo_AutoCreatedDemEvent_CC_J1939RmStateSwitch_CN_FMSNet_fce1aae5_CIOM_3a3d59b1_J1939RM_STATE_OFFLINE_BswMReportFailToDemRef: provided-interface=DiagnosticInfo
      EvtInfo_AutoCreatedDemEvent_CC_EnablePDUGroup_CIOM_oBackbone1J1939_Tx_0x31_BC_3782f500_BswMReportFailToDemRef: provided-interface=DiagnosticInfo
      EvtInfo_AutoCreatedDemEvent_CC_J1939RmStateSwitch_CN_FMSNet_fce1aae5_CIOM_3a3d59b1_J1939RM_STATE_ONLINE_BswMReportFailToDemRef: provided-interface=DiagnosticInfo
      EvtInfo_AutoCreatedDemEvent_ESH_Action_CancelNvMWriteAll_BswMReportFailToDemRef: provided-interface=DiagnosticInfo
      EvtInfo_AutoCreatedDemEvent_ESH_Action_CancelWriteAllTimer_Start_BswMReportFailToDemRef: provided-interface=DiagnosticInfo
      EvtInfo_AutoCreatedDemEvent_ESH_Action_CancelWriteAllTimer_Stop_BswMReportFailToDemRef: provided-interface=DiagnosticInfo
      EvtInfo_AutoCreatedDemEvent_ESH_Action_ComMAllow_CN_Backbone1J1939_0b1f4bae_BswMReportFailToDemRef: provided-interface=DiagnosticInfo
      EvtInfo_AutoCreatedDemEvent_ESH_Action_ComMAllow_CN_Backbone1J1939_0b1f4bae_BswMReportFailToDemRef_1: provided-interface=DiagnosticInfo
      EvtInfo_AutoCreatedDemEvent_ESH_Action_ComMAllow_CN_Backbone2_78967e2c_BswMReportFailToDemRef: provided-interface=DiagnosticInfo
      EvtInfo_AutoCreatedDemEvent_ESH_Action_ComMAllow_CN_Backbone2_78967e2c_BswMReportFailToDemRef_1: provided-interface=DiagnosticInfo
      EvtInfo_AutoCreatedDemEvent_ESH_Action_ComMAllow_CN_CabSubnet_9ea693f1_BswMReportFailToDemRef: provided-interface=DiagnosticInfo
      EvtInfo_AutoCreatedDemEvent_ESH_Action_ComMAllow_CN_CabSubnet_9ea693f1_BswMReportFailToDemRef_1: provided-interface=DiagnosticInfo
      EvtInfo_AutoCreatedDemEvent_ESH_Action_ComMAllow_CN_FMSNet_fce1aae5_BswMReportFailToDemRef: provided-interface=DiagnosticInfo
      EvtInfo_AutoCreatedDemEvent_ESH_Action_ComMAllow_CN_FMSNet_fce1aae5_BswMReportFailToDemRef_1: provided-interface=DiagnosticInfo
      EvtInfo_AutoCreatedDemEvent_ESH_Action_ComMAllow_CN_LIN00_2cd9a7df_BswMReportFailToDemRef: provided-interface=DiagnosticInfo
      EvtInfo_AutoCreatedDemEvent_ESH_Action_ComMAllow_CN_LIN00_2cd9a7df_BswMReportFailToDemRef_1: provided-interface=DiagnosticInfo
      EvtInfo_AutoCreatedDemEvent_ESH_Action_ComMAllow_CN_LIN01_5bde9749_BswMReportFailToDemRef: provided-interface=DiagnosticInfo
      EvtInfo_AutoCreatedDemEvent_ESH_Action_ComMAllow_CN_LIN01_5bde9749_BswMReportFailToDemRef_1: provided-interface=DiagnosticInfo
      EvtInfo_AutoCreatedDemEvent_ESH_Action_ComMAllow_CN_LIN02_c2d7c6f3_BswMReportFailToDemRef: provided-interface=DiagnosticInfo
      EvtInfo_AutoCreatedDemEvent_ESH_Action_ComMAllow_CN_LIN02_c2d7c6f3_BswMReportFailToDemRef_1: provided-interface=DiagnosticInfo
      EvtInfo_AutoCreatedDemEvent_ESH_Action_ComMAllow_CN_LIN03_b5d0f665_BswMReportFailToDemRef: provided-interface=DiagnosticInfo
      EvtInfo_AutoCreatedDemEvent_ESH_Action_ComMAllow_CN_LIN03_b5d0f665_BswMReportFailToDemRef_1: provided-interface=DiagnosticInfo
      EvtInfo_AutoCreatedDemEvent_ESH_Action_ComMAllow_CN_LIN04_2bb463c6_BswMReportFailToDemRef: provided-interface=DiagnosticInfo
      EvtInfo_AutoCreatedDemEvent_ESH_Action_ComMAllow_CN_LIN04_2bb463c6_BswMReportFailToDemRef_1: provided-interface=DiagnosticInfo
      EvtInfo_AutoCreatedDemEvent_ESH_Action_ComMAllow_CN_SecuritySubnet_e7a0ee54_BswMReportFailToDemRef: provided-interface=DiagnosticInfo
      EvtInfo_AutoCreatedDemEvent_ESH_Action_ComMAllow_CN_SecuritySubnet_e7a0ee54_BswMReportFailToDemRef_1: provided-interface=DiagnosticInfo
      EvtInfo_AutoCreatedDemEvent_ESH_Action_ComMCheckPendingRequests_BswMReportFailToDemRef_1: provided-interface=DiagnosticInfo
      EvtInfo_AutoCreatedDemEvent_ESH_Action_ComMCheckPendingRequests_BswMReportFailToDemRef_2: provided-interface=DiagnosticInfo
      EvtInfo_AutoCreatedDemEvent_ESH_Action_ComMDisallow_CN_Backbone1J1939_0b1f4bae_BswMReportFailToDemRef: provided-interface=DiagnosticInfo
      EvtInfo_AutoCreatedDemEvent_ESH_Action_ComMDisallow_CN_Backbone2_78967e2c_BswMReportFailToDemRef: provided-interface=DiagnosticInfo
      EvtInfo_AutoCreatedDemEvent_ESH_Action_ComMDisallow_CN_CabSubnet_9ea693f1_BswMReportFailToDemRef: provided-interface=DiagnosticInfo
      EvtInfo_AutoCreatedDemEvent_ESH_Action_ComMDisallow_CN_FMSNet_fce1aae5_BswMReportFailToDemRef: provided-interface=DiagnosticInfo
      EvtInfo_AutoCreatedDemEvent_ESH_Action_ComMDisallow_CN_LIN00_2cd9a7df_BswMReportFailToDemRef: provided-interface=DiagnosticInfo
      EvtInfo_AutoCreatedDemEvent_ESH_Action_ComMDisallow_CN_LIN01_5bde9749_BswMReportFailToDemRef: provided-interface=DiagnosticInfo
      EvtInfo_AutoCreatedDemEvent_ESH_Action_ComMDisallow_CN_LIN02_c2d7c6f3_BswMReportFailToDemRef: provided-interface=DiagnosticInfo
      EvtInfo_AutoCreatedDemEvent_ESH_Action_ComMDisallow_CN_LIN03_b5d0f665_BswMReportFailToDemRef: provided-interface=DiagnosticInfo
      EvtInfo_AutoCreatedDemEvent_ESH_Action_ComMDisallow_CN_LIN04_2bb463c6_BswMReportFailToDemRef: provided-interface=DiagnosticInfo
      EvtInfo_AutoCreatedDemEvent_ESH_Action_ComMDisallow_CN_SecuritySubnet_e7a0ee54_BswMReportFailToDemRef: provided-interface=DiagnosticInfo
      EvtInfo_AutoCreatedDemEvent_ESH_Action_DemInit_BswMReportFailToDemRef: provided-interface=DiagnosticInfo
      EvtInfo_AutoCreatedDemEvent_ESH_Action_DemInitialized_BswMReportFailToDemRef: provided-interface=DiagnosticInfo
      EvtInfo_AutoCreatedDemEvent_ESH_Action_DemNotInitialized_BswMReportFailToDemRef: provided-interface=DiagnosticInfo
      EvtInfo_AutoCreatedDemEvent_ESH_Action_DemShutdown_BswMReportFailToDemRef: provided-interface=DiagnosticInfo
      EvtInfo_AutoCreatedDemEvent_ESH_Action_ESH_PostRun_BswMReportFailToDemRef: provided-interface=DiagnosticInfo
      EvtInfo_AutoCreatedDemEvent_ESH_Action_ESH_PrepShutdown_BswMReportFailToDemRef: provided-interface=DiagnosticInfo
      EvtInfo_AutoCreatedDemEvent_ESH_Action_ESH_PrepShutdown_BswMReportFailToDemRef_1: provided-interface=DiagnosticInfo
      EvtInfo_AutoCreatedDemEvent_ESH_Action_ESH_Run_BswMReportFailToDemRef: provided-interface=DiagnosticInfo
      EvtInfo_AutoCreatedDemEvent_ESH_Action_ESH_Run_BswMReportFailToDemRef_1: provided-interface=DiagnosticInfo
      EvtInfo_AutoCreatedDemEvent_ESH_Action_ESH_WaitForNvm_BswMReportFailToDemRef: provided-interface=DiagnosticInfo
      EvtInfo_AutoCreatedDemEvent_ESH_Action_ESH_Wakeup_BswMReportFailToDemRef: provided-interface=DiagnosticInfo
      EvtInfo_AutoCreatedDemEvent_ESH_Action_ESH_Wakeup_BswMReportFailToDemRef_1: provided-interface=DiagnosticInfo
      EvtInfo_AutoCreatedDemEvent_ESH_Action_EcuMClearValidatedWakeupEvents_BswMReportFailToDemRef: provided-interface=DiagnosticInfo
      EvtInfo_AutoCreatedDemEvent_ESH_Action_EcuMGoToSelectedShutdownTarget_BswMReportFailToDemRef: provided-interface=DiagnosticInfo
      EvtInfo_AutoCreatedDemEvent_ESH_Action_EnterExclusiveArea_BswMReportFailToDemRef_1: provided-interface=DiagnosticInfo
      EvtInfo_AutoCreatedDemEvent_ESH_Action_ExitExclusiveArea_BswMReportFailToDemRef: provided-interface=DiagnosticInfo
      EvtInfo_AutoCreatedDemEvent_ESH_Action_NvMWriteAll_BswMReportFailToDemRef: provided-interface=DiagnosticInfo
      EvtInfo_AutoCreatedDemEvent_ESH_Action_OnEnterPostRun_BswMReportFailToDemRef: provided-interface=DiagnosticInfo
      EvtInfo_AutoCreatedDemEvent_ESH_Action_OnEnterPrepShutdown_BswMReportFailToDemRef: provided-interface=DiagnosticInfo
      EvtInfo_AutoCreatedDemEvent_ESH_Action_OnEnterPrepShutdown_BswMReportFailToDemRef_1: provided-interface=DiagnosticInfo
      EvtInfo_AutoCreatedDemEvent_ESH_Action_OnEnterRun_BswMReportFailToDemRef: provided-interface=DiagnosticInfo
      EvtInfo_AutoCreatedDemEvent_ESH_Action_OnEnterRun_BswMReportFailToDemRef_1: provided-interface=DiagnosticInfo
      EvtInfo_AutoCreatedDemEvent_ESH_Action_OnEnterShutdown_BswMReportFailToDemRef: provided-interface=DiagnosticInfo
      EvtInfo_AutoCreatedDemEvent_ESH_Action_OnEnterWaitForNvm_BswMReportFailToDemRef: provided-interface=DiagnosticInfo
      EvtInfo_AutoCreatedDemEvent_ESH_Action_OnEnterWakeup_BswMReportFailToDemRef: provided-interface=DiagnosticInfo
      EvtInfo_AutoCreatedDemEvent_ESH_Action_OnEnterWakeup_BswMReportFailToDemRef_1: provided-interface=DiagnosticInfo
      EvtInfo_AutoCreatedDemEvent_ESH_Action_SelfRunRequestTimer_Start_BswMReportFailToDemRef: provided-interface=DiagnosticInfo
      EvtInfo_AutoCreatedDemEvent_ESH_Action_SelfRunRequestTimer_Start_BswMReportFailToDemRef_1: provided-interface=DiagnosticInfo
      EvtInfo_AutoCreatedDemEvent_ESH_Action_SwitchPostRun_BswMReportFailToDemRef: provided-interface=DiagnosticInfo
      EvtInfo_AutoCreatedDemEvent_ESH_Action_SwitchRun_BswMReportFailToDemRef: provided-interface=DiagnosticInfo
      EvtInfo_AutoCreatedDemEvent_ESH_Action_SwitchRun_BswMReportFailToDemRef_1: provided-interface=DiagnosticInfo
      EvtInfo_AutoCreatedDemEvent_ESH_Action_SwitchShutdown_BswMReportFailToDemRef: provided-interface=DiagnosticInfo
      EvtInfo_AutoCreatedDemEvent_ESH_Action_SwitchShutdown_BswMReportFailToDemRef_1: provided-interface=DiagnosticInfo
      EvtInfo_AutoCreatedDemEvent_ESH_Action_SwitchWakeup_BswMReportFailToDemRef: provided-interface=DiagnosticInfo
      EvtInfo_AutoCreatedDemEvent_ESH_Action_SwitchWakeup_BswMReportFailToDemRef_1: provided-interface=DiagnosticInfo
      EvtInfo_AutoCreatedDemEvent_ESH_Action_WriteAllTimer_Start_BswMReportFailToDemRef: provided-interface=DiagnosticInfo
      EvtInfo_AutoCreatedDemEvent_ESH_Action_WriteAllTimer_Stop_BswMReportFailToDemRef: provided-interface=DiagnosticInfo
      EvtInfo_AutoCreatedDemEvent_ESH_Action_WriteAllTimer_Stop_BswMReportFailToDemRef_1: provided-interface=DiagnosticInfo
      EvtInfo_AutoCreatedDemEvent_ESH_DemInit_BswMReportFailToDemRef: provided-interface=DiagnosticInfo
      EvtInfo_AutoCreatedDemEvent_ESH_PostRunNested_BswMReportFailToDemRef: provided-interface=DiagnosticInfo
      EvtInfo_AutoCreatedDemEvent_ESH_PostRunToPrepNested_BswMReportFailToDemRef: provided-interface=DiagnosticInfo
      EvtInfo_AutoCreatedDemEvent_ESH_Action_ExitExclusiveArea_BswMReportFailToDemRef_1: provided-interface=DiagnosticInfo
      EvtInfo_AutoCreatedDemEvent_INIT_Action_BrsHw_EnableHwAccess_BswMReportFailToDemRef: provided-interface=DiagnosticInfo
      EvtInfo_AutoCreatedDemEvent_INIT_Action_CanIf_Init_BswMReportFailToDemRef: provided-interface=DiagnosticInfo
      EvtInfo_AutoCreatedDemEvent_INIT_Action_CanNm_Init_BswMReportFailToDemRef: provided-interface=DiagnosticInfo
      EvtInfo_AutoCreatedDemEvent_INIT_Action_CanSM_Init_BswMReportFailToDemRef: provided-interface=DiagnosticInfo
      EvtInfo_AutoCreatedDemEvent_INIT_Action_CanTp_Init_BswMReportFailToDemRef: provided-interface=DiagnosticInfo
      EvtInfo_AutoCreatedDemEvent_INIT_Action_Can_Init_BswMReportFailToDemRef: provided-interface=DiagnosticInfo
      EvtInfo_AutoCreatedDemEvent_INIT_Action_ComM_Init_BswMReportFailToDemRef: provided-interface=DiagnosticInfo
      EvtInfo_AutoCreatedDemEvent_INIT_Action_Com_Init_BswMReportFailToDemRef: provided-interface=DiagnosticInfo
      EvtInfo_AutoCreatedDemEvent_INIT_Action_Dcm_Init_BswMReportFailToDemRef: provided-interface=DiagnosticInfo
      EvtInfo_AutoCreatedDemEvent_INIT_Action_Dem_Init_BswMReportFailToDemRef: provided-interface=DiagnosticInfo
      EvtInfo_AutoCreatedDemEvent_INIT_Action_EnableInterrupts_BswMReportFailToDemRef: provided-interface=DiagnosticInfo
      EvtInfo_AutoCreatedDemEvent_INIT_Action_Fee_Init_BswMReportFailToDemRef: provided-interface=DiagnosticInfo
      EvtInfo_AutoCreatedDemEvent_INIT_Action_Issm_Init_BswMReportFailToDemRef: provided-interface=DiagnosticInfo
      EvtInfo_AutoCreatedDemEvent_INIT_Action_J1939Nm_Init_BswMReportFailToDemRef: provided-interface=DiagnosticInfo
      EvtInfo_AutoCreatedDemEvent_INIT_Action_J1939Rm_Init_BswMReportFailToDemRef: provided-interface=DiagnosticInfo
      EvtInfo_AutoCreatedDemEvent_INIT_Action_J1939Tp_Init_BswMReportFailToDemRef: provided-interface=DiagnosticInfo
      EvtInfo_AutoCreatedDemEvent_INIT_Action_LinIf_Init_BswMReportFailToDemRef: provided-interface=DiagnosticInfo
      EvtInfo_AutoCreatedDemEvent_INIT_Action_LinSM_Init_BswMReportFailToDemRef: provided-interface=DiagnosticInfo
      EvtInfo_AutoCreatedDemEvent_INIT_Action_LinTp_Init_BswMReportFailToDemRef: provided-interface=DiagnosticInfo
      EvtInfo_AutoCreatedDemEvent_INIT_Action_Lin_Init_BswMReportFailToDemRef: provided-interface=DiagnosticInfo
      EvtInfo_AutoCreatedDemEvent_INIT_Action_Nm_Init_BswMReportFailToDemRef: provided-interface=DiagnosticInfo
      EvtInfo_AutoCreatedDemEvent_INIT_Action_NvMReadAll_BswMReportFailToDemRef: provided-interface=DiagnosticInfo
      EvtInfo_AutoCreatedDemEvent_INIT_Action_NvM_Init_BswMReportFailToDemRef: provided-interface=DiagnosticInfo
      EvtInfo_AutoCreatedDemEvent_INIT_Action_PduR_Init_BswMReportFailToDemRef: provided-interface=DiagnosticInfo
      EvtInfo_AutoCreatedDemEvent_INIT_Action_RteStart_BswMReportFailToDemRef: provided-interface=DiagnosticInfo
      EvtInfo_AutoCreatedDemEvent_CHNL_17344684_CANSM_E_MODE_REQUEST_TIMEOUT: provided-interface=DiagnosticInfo
      EvtInfo_AutoCreatedDemEvent_CHNL_17344684_CANSM_E_BUS_OFF: provided-interface=DiagnosticInfo
      EvtInfo_AutoCreatedDemEvent_CHNL_53cce282_CANSM_E_MODE_REQUEST_TIMEOUT: provided-interface=DiagnosticInfo
      EvtInfo_AutoCreatedDemEvent_CHNL_53cce282_CANSM_E_BUS_OFF: provided-interface=DiagnosticInfo
      EvtInfo_AutoCreatedDemEvent_CHNL_a6b6a922_CANSM_E_MODE_REQUEST_TIMEOUT: provided-interface=DiagnosticInfo
      EvtInfo_AutoCreatedDemEvent_CHNL_a6b6a922_CANSM_E_BUS_OFF: provided-interface=DiagnosticInfo
      EvtInfo_AutoCreatedDemEvent_CHNL_df893ad5_CANSM_E_MODE_REQUEST_TIMEOUT: provided-interface=DiagnosticInfo
      EvtInfo_AutoCreatedDemEvent_CHNL_df893ad5_CANSM_E_BUS_OFF: provided-interface=DiagnosticInfo
      EvtInfo_AutoCreatedDemEvent_CHNL_e058b4ae_CANSM_E_MODE_REQUEST_TIMEOUT: provided-interface=DiagnosticInfo
      EvtInfo_AutoCreatedDemEvent_CHNL_e058b4ae_CANSM_E_BUS_OFF: provided-interface=DiagnosticInfo
      EvtInfo_AutoCreatedDemEvent_ECUM_E_RAM_CHECK_FAILED: provided-interface=DiagnosticInfo
      EvtInfo_AutoCreatedDemEvent_ECUM_E_IMPROPER_CALLER: provided-interface=DiagnosticInfo
      EvtInfo_AutoCreatedDemEvent_ECUM_E_CONFIGURATION_DATA_INCONSISTENT: provided-interface=DiagnosticInfo
      EvtInfo_AutoCreatedDemEvent_ECUM_E_ALL_RUN_REQUESTS_KILLED: provided-interface=DiagnosticInfo
      EvtInfo_AutoCreatedDemEvent_FLS_E_WRITE_FAILED: provided-interface=DiagnosticInfo
      EvtInfo_AutoCreatedDemEvent_FLS_E_UNEXPECTED_FLASH_ID: provided-interface=DiagnosticInfo
      EvtInfo_AutoCreatedDemEvent_FLS_E_READ_FAILED: provided-interface=DiagnosticInfo
      EvtInfo_AutoCreatedDemEvent_FLS_E_ERASE_FAILED: provided-interface=DiagnosticInfo
      EvtInfo_AutoCreatedDemEvent_FLS_E_COMPARE_FAILED: provided-interface=DiagnosticInfo
      EvtInfo_AutoCreatedDemEvent_GPT_E_TIMEOUT: provided-interface=DiagnosticInfo
      EvtInfo_AutoCreatedDemEvent_J1939NM_E_ADDRESS_LOST: provided-interface=DiagnosticInfo
      EvtInfo_AutoCreatedDemEvent_J1939TpConfiguration_J1939TP_E_COMMUNICATION: provided-interface=DiagnosticInfo
      EvtInfo_AutoCreatedDemEvent_LIN_E_TIMEOUT: provided-interface=DiagnosticInfo
      EvtInfo_AutoCreatedDemEvent_MCL_E_DMA_UNRECOGNIZED: provided-interface=DiagnosticInfo
      EvtInfo_AutoCreatedDemEvent_MCL_E_DMA_PRIORITY: provided-interface=DiagnosticInfo
      EvtInfo_AutoCreatedDemEvent_MCL_E_DMA_INCONSISTENCY: provided-interface=DiagnosticInfo
      EvtInfo_AutoCreatedDemEvent_MCL_E_DMA_ECC: provided-interface=DiagnosticInfo
      EvtInfo_AutoCreatedDemEvent_MCL_E_DMA_DESCRIPTOR: provided-interface=DiagnosticInfo
      EvtInfo_AutoCreatedDemEvent_MCL_E_DMA_BUS: provided-interface=DiagnosticInfo
      EvtInfo_AutoCreatedDemEvent_MCU_E_TIMEOUT_FAILURE: provided-interface=DiagnosticInfo
      EvtInfo_AutoCreatedDemEvent_MCU_E_SSCM_CER_FAILURE: provided-interface=DiagnosticInfo
      EvtInfo_AutoCreatedDemEvent_MCU_E_INVALIDMODE_CONFIG: provided-interface=DiagnosticInfo
      EvtInfo_AutoCreatedDemEvent_MCU_E_CLOCK_FAILURE: provided-interface=DiagnosticInfo
      EvtInfo_AutoCreatedDemEvent_NVM_E_WRONG_BLOCK_ID: provided-interface=DiagnosticInfo
      EvtInfo_AutoCreatedDemEvent_NVM_E_WRITE_PROTECTED: provided-interface=DiagnosticInfo
      EvtInfo_AutoCreatedDemEvent_NVM_E_VERIFY_FAILED: provided-interface=DiagnosticInfo
      EvtInfo_AutoCreatedDemEvent_NVM_E_REQ_FAILED: provided-interface=DiagnosticInfo
      EvtInfo_AutoCreatedDemEvent_NVM_E_QUEUE_OVERFLOW: provided-interface=DiagnosticInfo
      EvtInfo_AutoCreatedDemEvent_NVM_E_LOSS_OF_REDUNDANCY: provided-interface=DiagnosticInfo
      EvtInfo_AutoCreatedDemEvent_NVM_E_INTEGRITY_FAILED: provided-interface=DiagnosticInfo
      EvtInfo_AutoCreatedDemEvent_SPI_E_HARDWARE_ERROR: provided-interface=DiagnosticInfo
      EvtInfo_AutoCreatedDemEvent_SpiDriver_SPI_E_HARDWARE_ERROR: provided-interface=DiagnosticInfo
      EvtInfo_AutoCreatedDemEvent_WDG_E_UNLOCKED: provided-interface=DiagnosticInfo
      EvtInfo_AutoCreatedDemEvent_WDG_E_MODE_FAILED: provided-interface=DiagnosticInfo
      EvtInfo_AutoCreatedDemEvent_WDG_E_INVALID_PARAMETER: provided-interface=DiagnosticInfo
      EvtInfo_AutoCreatedDemEvent_WDG_E_INVALID_CALL: provided-interface=DiagnosticInfo
      EvtInfo_AutoCreatedDemEvent_WDG_E_FORBIDDEN_INVOCATION: provided-interface=DiagnosticInfo
      EvtInfo_AutoCreatedDemEvent_WDG_E_DISABLE_REJECTED: provided-interface=DiagnosticInfo
      EvtInfo_AutoCreatedDemEvent_WDG_E_CORRUPT_CONFIG: provided-interface=DiagnosticInfo
      EvtInfo_DEM_EVENT_StartApplication: provided-interface=DiagnosticInfo
      Event_DEM_EVENT_StartApplication: provided-interface=DiagnosticMonitor
    require port CBReadData_DemDataElementClass_StartApplication: required-interface=CSDataServices_DemDataElementClass_StartApplication
    behavior DemSatellite_OsApplication_Untrusted_Core0InternalBehavior: handle-termination-and-restart=NO-SUPPORT, included-data-type-set=data-type=[Dem_EventIdType, Dem_RatioIdType, Dem_EventStatusType, Dem_UdsStatusByteType, Dem_DTCFormatType, Dem_InitMonitorReasonType, Dem_OperationCycleStateType, Dem_DTCStatusMaskType, Dem_IndicatorStatusType, Dem_MaxDataValueType, Dem_DTCKindType, Dem_DTCGroupType, Dem_IumprDenomCondIdType, Dem_IumprDenomCondStatusType, Dem_DebounceResetStatusType, Dem_DebouncingStateType, Dem_IumprReadinessGroupType, Dem_DTRControlType, Dem_DTCSeverityType, Dem_MonitorStatusType]
      timing event Timer_Dem_SatelliteMainFunction: start-on-event=Dem_SatelliteMainFunction, period=0.1
      2354 x operation invoked event:
        OpEventGetEventUdsStatus_GetEventUdsStatus_EvtInfo_DemEventParameter_0: start-on-event=DemSatellite_OsApplication_Untrusted_Core0InternalBehavior/GetEventUdsStatus, operation=EvtInfo_DemEventParameter_0.GetEventUdsStatus
        OpEventGetEventUdsStatus_GetEventUdsStatus_GeneralEventInfo: start-on-event=DemSatellite_OsApplication_Untrusted_Core0InternalBehavior/GetEventUdsStatus, operation=GeneralEventInfo.GetEventUdsStatus
        OpEventGetEventStatus_GetEventStatus_EvtInfo_DemEventParameter_0: start-on-event=DemSatellite_OsApplication_Untrusted_Core0InternalBehavior/GetEventStatus, operation=EvtInfo_DemEventParameter_0.GetEventStatus
        OpEventGetEventStatus_GetEventStatus_GeneralEventInfo: start-on-event=DemSatellite_OsApplication_Untrusted_Core0InternalBehavior/GetEventStatus, operation=GeneralEventInfo.GetEventStatus
        OpEventGetEventFailed_GetEventFailed_EvtInfo_DemEventParameter_0: start-on-event=DemSatellite_OsApplication_Untrusted_Core0InternalBehavior/GetEventFailed, operation=EvtInfo_DemEventParameter_0.GetEventFailed
        OpEventGetEventFailed_GetEventFailed_GeneralEventInfo: start-on-event=DemSatellite_OsApplication_Untrusted_Core0InternalBehavior/GetEventFailed, operation=GeneralEventInfo.GetEventFailed
        OpEventGetEventTested_GetEventTested_EvtInfo_DemEventParameter_0: start-on-event=DemSatellite_OsApplication_Untrusted_Core0InternalBehavior/GetEventTested, operation=EvtInfo_DemEventParameter_0.GetEventTested
        OpEventGetEventTested_GetEventTested_GeneralEventInfo: start-on-event=DemSatellite_OsApplication_Untrusted_Core0InternalBehavior/GetEventTested, operation=GeneralEventInfo.GetEventTested
        OpEventGetDTCOfEvent_GetDTCOfEvent_EvtInfo_DemEventParameter_0: start-on-event=DemSatellite_OsApplication_Untrusted_Core0InternalBehavior/GetDTCOfEvent, operation=EvtInfo_DemEventParameter_0.GetDTCOfEvent
        OpEventGetDTCOfEvent_GetDTCOfEvent_GeneralEventInfo: start-on-event=DemSatellite_OsApplication_Untrusted_Core0InternalBehavior/GetDTCOfEvent, operation=GeneralEventInfo.GetDTCOfEvent
        OpEventGetFaultDetectionCounter_GetFaultDetectionCounter_EvtInfo_DemEventParameter_0: start-on-event=DemSatellite_OsApplication_Untrusted_Core0InternalBehavior/GetFaultDetectionCounter, operation=EvtInfo_DemEventParameter_0.GetFaultDetectionCounter
        OpEventGetFaultDetectionCounter_GetFaultDetectionCounter_GeneralEventInfo: start-on-event=DemSatellite_OsApplication_Untrusted_Core0InternalBehavior/GetFaultDetectionCounter, operation=GeneralEventInfo.GetFaultDetectionCounter
        OpEventGetEventFreezeFrameDataEx_GetEventFreezeFrameDataEx_EvtInfo_DemEventParameter_0: start-on-event=DemSatellite_OsApplication_Untrusted_Core0InternalBehavior/GetEventFreezeFrameDataEx, operation=EvtInfo_DemEventParameter_0.GetEventFreezeFrameDataEx
        OpEventGetEventFreezeFrameDataEx_GetEventFreezeFrameDataEx_GeneralEventInfo: start-on-event=DemSatellite_OsApplication_Untrusted_Core0InternalBehavior/GetEventFreezeFrameDataEx, operation=GeneralEventInfo.GetEventFreezeFrameDataEx
        OpEventGetEventExtendedDataRecordEx_GetEventExtendedDataRecordEx_EvtInfo_DemEventParameter_0: start-on-event=DemSatellite_OsApplication_Untrusted_Core0InternalBehavior/GetEventExtendedDataRecordEx, operation=EvtInfo_DemEventParameter_0.GetEventExtendedDataRecordEx
        OpEventGetEventExtendedDataRecordEx_GetEventExtendedDataRecordEx_GeneralEventInfo: start-on-event=DemSatellite_OsApplication_Untrusted_Core0InternalBehavior/GetEventExtendedDataRecordEx, operation=GeneralEventInfo.GetEventExtendedDataRecordEx
        OpEventGetEventEnableCondition_GetEventEnableCondition_EvtInfo_DemEventParameter_0: start-on-event=DemSatellite_OsApplication_Untrusted_Core0InternalBehavior/GetEventEnableCondition, operation=EvtInfo_DemEventParameter_0.GetEventEnableCondition
        OpEventGetEventEnableCondition_GetEventEnableCondition_GeneralEventInfo: start-on-event=DemSatellite_OsApplication_Untrusted_Core0InternalBehavior/GetEventEnableCondition, operation=GeneralEventInfo.GetEventEnableCondition
        OpEventGetDebouncingOfEvent_GetDebouncingOfEvent_EvtInfo_DemEventParameter_0: start-on-event=DemSatellite_OsApplication_Untrusted_Core0InternalBehavior/GetDebouncingOfEvent, operation=EvtInfo_DemEventParameter_0.GetDebouncingOfEvent
        OpEventGetDebouncingOfEvent_GetDebouncingOfEvent_GeneralEventInfo: start-on-event=DemSatellite_OsApplication_Untrusted_Core0InternalBehavior/GetDebouncingOfEvent, operation=GeneralEventInfo.GetDebouncingOfEvent
        OpEventGetMonitorStatus_GetMonitorStatus_EvtInfo_DemEventParameter_0: start-on-event=DemSatellite_OsApplication_Untrusted_Core0InternalBehavior/GetMonitorStatus, operation=EvtInfo_DemEventParameter_0.GetMonitorStatus
        OpEventGetMonitorStatus_GetMonitorStatus_GeneralEventInfo: start-on-event=DemSatellite_OsApplication_Untrusted_Core0InternalBehavior/GetMonitorStatus, operation=GeneralEventInfo.GetMonitorStatus
        OpEventGetEventUdsStatus_GetEventUdsStatus_Event_DemEventParameter_0: start-on-event=DemSatellite_OsApplication_Untrusted_Core0InternalBehavior/GetEventUdsStatus, operation=Event_DemEventParameter_0.GetEventUdsStatus
        OpEventGetEventStatus_GetEventStatus_Event_DemEventParameter_0: start-on-event=DemSatellite_OsApplication_Untrusted_Core0InternalBehavior/GetEventStatus, operation=Event_DemEventParameter_0.GetEventStatus
        OpEventGetEventFailed_GetEventFailed_Event_DemEventParameter_0: start-on-event=DemSatellite_OsApplication_Untrusted_Core0InternalBehavior/GetEventFailed, operation=Event_DemEventParameter_0.GetEventFailed
        OpEventGetEventTested_GetEventTested_Event_DemEventParameter_0: start-on-event=DemSatellite_OsApplication_Untrusted_Core0InternalBehavior/GetEventTested, operation=Event_DemEventParameter_0.GetEventTested
        OpEventGetDTCOfEvent_GetDTCOfEvent_Event_DemEventParameter_0: start-on-event=DemSatellite_OsApplication_Untrusted_Core0InternalBehavior/GetDTCOfEvent, operation=Event_DemEventParameter_0.GetDTCOfEvent
        OpEventGetFaultDetectionCounter_GetFaultDetectionCounter_Event_DemEventParameter_0: start-on-event=DemSatellite_OsApplication_Untrusted_Core0InternalBehavior/GetFaultDetectionCounter, operation=Event_DemEventParameter_0.GetFaultDetectionCounter
        OpEventGetEventFreezeFrameDataEx_GetEventFreezeFrameDataEx_Event_DemEventParameter_0: start-on-event=DemSatellite_OsApplication_Untrusted_Core0InternalBehavior/GetEventFreezeFrameDataEx, operation=Event_DemEventParameter_0.GetEventFreezeFrameDataEx
        OpEventGetEventExtendedDataRecordEx_GetEventExtendedDataRecordEx_Event_DemEventParameter_0: start-on-event=DemSatellite_OsApplication_Untrusted_Core0InternalBehavior/GetEventExtendedDataRecordEx, operation=Event_DemEventParameter_0.GetEventExtendedDataRecordEx
        OpEventSetEventStatus_SetEventStatus_Event_DemEventParameter_0: start-on-event=SetEventStatus, operation=Event_DemEventParameter_0.SetEventStatus
        OpEventResetEventStatus_ResetEventStatus_Event_DemEventParameter_0: start-on-event=ResetEventStatus, operation=Event_DemEventParameter_0.ResetEventStatus
        OpEventResetEventDebounceStatus_ResetEventDebounceStatus_Event_DemEventParameter_0: start-on-event=ResetEventDebounceStatus, operation=Event_DemEventParameter_0.ResetEventDebounceStatus
        OpEventGetEventUdsStatus_GetEventUdsStatus_EvtInfo_AutoCreatedDemEvent_ADC_E_TIMEOUT: start-on-event=DemSatellite_OsApplication_Untrusted_Core0InternalBehavior/GetEventUdsStatus, operation=EvtInfo_AutoCreatedDemEvent_ADC_E_TIMEOUT.GetEventUdsStatus
        OpEventGetEventUdsStatus_GetEventUdsStatus_EvtInfo_AutoCreatedDemEvent_CC_DisableDM_CIOM_oCabSubnet_Rx_063a5fbc_BswMRep_679735e4: start-on-event=DemSatellite_OsApplication_Untrusted_Core0InternalBehavior/GetEventUdsStatus, operation=EvtInfo_AutoCreatedDemEvent_CC_DisableDM_CIOM_oCabSubnet_Rx_063a5fbc_BswMReportFailToDemRef.GetEventUdsStatus
        OpEventGetEventUdsStatus_GetEventUdsStatus_EvtInfo_AutoCreatedDemEvent_CC_J1939RmStateSwitch_CN_Backbone1J1939_0b1f4bae_d590d2aa: start-on-event=DemSatellite_OsApplication_Untrusted_Core0InternalBehavior/GetEventUdsStatus, operation=EvtInfo_AutoCreatedDemEvent_CC_J1939RmStateSwitch_CN_Backbone1J1939_0b1f4bae_CIOM_4d5cd289_J1939RM_STATE_OFFLINE_BswMRe_5a5b15b8.GetEventUdsStatus
        OpEventGetEventUdsStatus_GetEventUdsStatus_EvtInfo_AutoCreatedDemEvent_CC_J1939RmStateSwitch_CN_Backbone1J1939_0b1f4bae_a8cfe239: start-on-event=DemSatellite_OsApplication_Untrusted_Core0InternalBehavior/GetEventUdsStatus, operation=EvtInfo_AutoCreatedDemEvent_CC_J1939RmStateSwitch_CN_Backbone1J1939_0b1f4bae_CIOM_4d5cd289_J1939RM_STATE_ONLINE_BswMRep_ec959aed.GetEventUdsStatus
        OpEventGetEventUdsStatus_GetEventUdsStatus_EvtInfo_AutoCreatedDemEvent_CC_DisablePDUGroup_CIOM_oLIN04_Tx_04202f7b_BswMR_6fb347ae: start-on-event=DemSatellite_OsApplication_Untrusted_Core0InternalBehavior/GetEventUdsStatus, operation=EvtInfo_AutoCreatedDemEvent_CC_DisablePDUGroup_CIOM_oLIN04_Tx_04202f7b_BswMReportFailToDemRef.GetEventUdsStatus
        OpEventGetEventUdsStatus_GetEventUdsStatus_EvtInfo_AutoCreatedDemEvent_CC_DisablePDUGroup_CIOM_oLIN04_Rx_527a88fd_BswMR_a6112250: start-on-event=DemSatellite_OsApplication_Untrusted_Core0InternalBehavior/GetEventUdsStatus, operation=EvtInfo_AutoCreatedDemEvent_CC_DisablePDUGroup_CIOM_oLIN04_Rx_527a88fd_BswMReportFailToDemRef.GetEventUdsStatus
        OpEventGetEventUdsStatus_GetEventUdsStatus_EvtInfo_AutoCreatedDemEvent_CC_DisablePDUGroup_CIOM_oLIN01_Tx_33fedf49_BswMR_140beed7: start-on-event=DemSatellite_OsApplication_Untrusted_Core0InternalBehavior/GetEventUdsStatus, operation=EvtInfo_AutoCreatedDemEvent_CC_DisablePDUGroup_CIOM_oLIN01_Tx_33fedf49_BswMReportFailToDemRef.GetEventUdsStatus
        OpEventGetEventUdsStatus_GetEventUdsStatus_EvtInfo_AutoCreatedDemEvent_CC_DisablePDUGroup_CIOM_oLIN01_Rx_65a478cf_BswMR_2a3b445d: start-on-event=DemSatellite_OsApplication_Untrusted_Core0InternalBehavior/GetEventUdsStatus, operation=EvtInfo_AutoCreatedDemEvent_CC_DisablePDUGroup_CIOM_oLIN01_Rx_65a478cf_BswMReportFailToDemRef.GetEventUdsStatus
        OpEventGetEventUdsStatus_GetEventUdsStatus_EvtInfo_AutoCreatedDemEvent_CC_EnablePDUGroup_CIOM_oLIN04_Tx_04202f7b_BswMRe_b65e9ac2: start-on-event=DemSatellite_OsApplication_Untrusted_Core0InternalBehavior/GetEventUdsStatus, operation=EvtInfo_AutoCreatedDemEvent_CC_EnablePDUGroup_CIOM_oLIN04_Tx_04202f7b_BswMReportFailToDemRef.GetEventUdsStatus
        OpEventGetEventUdsStatus_GetEventUdsStatus_EvtInfo_AutoCreatedDemEvent_CC_EnablePDUGroup_CIOM_oLIN04_Rx_527a88fd_BswMRe_7ffcff3c: start-on-event=DemSatellite_OsApplication_Untrusted_Core0InternalBehavior/GetEventUdsStatus, operation=EvtInfo_AutoCreatedDemEvent_CC_EnablePDUGroup_CIOM_oLIN04_Rx_527a88fd_BswMReportFailToDemRef.GetEventUdsStatus
        OpEventGetEventUdsStatus_GetEventUdsStatus_EvtInfo_AutoCreatedDemEvent_CC_DisableDM_CIOM_oBackbone2_Rx_4e624434_BswMRep_00c33f6a: start-on-event=DemSatellite_OsApplication_Untrusted_Core0InternalBehavior/GetEventUdsStatus, operation=EvtInfo_AutoCreatedDemEvent_CC_DisableDM_CIOM_oBackbone2_Rx_4e624434_BswMReportFailToDemRef.GetEventUdsStatus
        OpEventGetEventUdsStatus_GetEventUdsStatus_EvtInfo_AutoCreatedDemEvent_CC_EnableDM_CIOM_oBackbone2_Rx_4e624434_BswMRepo_e9531e4a: start-on-event=DemSatellite_OsApplication_Untrusted_Core0InternalBehavior/GetEventUdsStatus, operation=EvtInfo_AutoCreatedDemEvent_CC_EnableDM_CIOM_oBackbone2_Rx_4e624434_BswMReportFailToDemRef.GetEventUdsStatus
        OpEventGetEventUdsStatus_GetEventUdsStatus_EvtInfo_AutoCreatedDemEvent_CC_DisableDM_CIOM_oSecuritySubnet_Rx_3a3c1dbc_Bs_50904447: start-on-event=DemSatellite_OsApplication_Untrusted_Core0InternalBehavior/GetEventUdsStatus, operation=EvtInfo_AutoCreatedDemEvent_CC_DisableDM_CIOM_oSecuritySubnet_Rx_3a3c1dbc_BswMReportFailToDemRef.GetEventUdsStatus
        OpEventGetEventUdsStatus_GetEventUdsStatus_EvtInfo_AutoCreatedDemEvent_CC_EnableDM_CIOM_oSecuritySubnet_Rx_3a3c1dbc_Bsw_fb70534d: start-on-event=DemSatellite_OsApplication_Untrusted_Core0InternalBehavior/GetEventUdsStatus, operation=EvtInfo_AutoCreatedDemEvent_CC_EnableDM_CIOM_oSecuritySubnet_Rx_3a3c1dbc_BswMReportFailToDemRef.GetEventUdsStatus
        OpEventGetEventUdsStatus_GetEventUdsStatus_EvtInfo_AutoCreatedDemEvent_CC_DisablePDUGroup_CIOM_oCabSubnet_Tx_5060f83a_B_cd5973ea: start-on-event=DemSatellite_OsApplication_Untrusted_Core0InternalBehavior/GetEventUdsStatus, operation=EvtInfo_AutoCreatedDemEvent_CC_DisablePDUGroup_CIOM_oCabSubnet_Tx_5060f83a_BswMReportFailToDemRef.GetEventUdsStatus
        OpEventGetEventUdsStatus_GetEventUdsStatus_EvtInfo_AutoCreatedDemEvent_CC_EnablePDUGroup_CIOM_oCabSubnet_Tx_5060f83a_Bs_2d277ae3: start-on-event=DemSatellite_OsApplication_Untrusted_Core0InternalBehavior/GetEventUdsStatus, operation=EvtInfo_AutoCreatedDemEvent_CC_EnablePDUGroup_CIOM_oCabSubnet_Tx_5060f83a_BswMReportFailToDemRef.GetEventUdsStatus
        OpEventGetEventUdsStatus_GetEventUdsStatus_EvtInfo_AutoCreatedDemEvent_CC_EnableDM_CIOM_oCabSubnet_Rx_063a5fbc_BswMRepo_8e0714c4: start-on-event=DemSatellite_OsApplication_Untrusted_Core0InternalBehavior/GetEventUdsStatus, operation=EvtInfo_AutoCreatedDemEvent_CC_EnableDM_CIOM_oCabSubnet_Rx_063a5fbc_BswMReportFailToDemRef.GetEventUdsStatus
        OpEventGetEventUdsStatus_GetEventUdsStatus_EvtInfo_AutoCreatedDemEvent_CC_DisablePDUGroup_CIOM_oBackbone2_Tx_1838e3b2_B_af04eec4: start-on-event=DemSatellite_OsApplication_Untrusted_Core0InternalBehavior/GetEventUdsStatus, operation=EvtInfo_AutoCreatedDemEvent_CC_DisablePDUGroup_CIOM_oBackbone2_Tx_1838e3b2_BswMReportFailToDemRef.GetEventUdsStatus
        OpEventGetEventUdsStatus_GetEventUdsStatus_EvtInfo_AutoCreatedDemEvent_CC_EnablePDUGroup_CIOM_oBackbone2_Tx_1838e3b2_Bs_4f7ae7cd: start-on-event=DemSatellite_OsApplication_Untrusted_Core0InternalBehavior/GetEventUdsStatus, operation=EvtInfo_AutoCreatedDemEvent_CC_EnablePDUGroup_CIOM_oBackbone2_Tx_1838e3b2_BswMReportFailToDemRef.GetEventUdsStatus
        OpEventGetEventUdsStatus_GetEventUdsStatus_EvtInfo_AutoCreatedDemEvent_CC_DisablePDUGroup_CIOM_oBackbone2_Rx_4e624434_B_5a704f4e: start-on-event=DemSatellite_OsApplication_Untrusted_Core0InternalBehavior/GetEventUdsStatus, operation=EvtInfo_AutoCreatedDemEvent_CC_DisablePDUGroup_CIOM_oBackbone2_Rx_4e624434_BswMReportFailToDemRef.GetEventUdsStatus
        OpEventGetEventUdsStatus_GetEventUdsStatus_EvtInfo_AutoCreatedDemEvent_CC_EnablePDUGroup_CIOM_oBackbone2_Rx_4e624434_Bs_ba0e4647: start-on-event=DemSatellite_OsApplication_Untrusted_Core0InternalBehavior/GetEventUdsStatus, operation=EvtInfo_AutoCreatedDemEvent_CC_EnablePDUGroup_CIOM_oBackbone2_Rx_4e624434_BswMReportFailToDemRef.GetEventUdsStatus
        OpEventGetEventUdsStatus_GetEventUdsStatus_EvtInfo_AutoCreatedDemEvent_CC_DisablePDUGroup_CIOM_oBackbone1J1939_Rx_BC_40_4578e36d: start-on-event=DemSatellite_OsApplication_Untrusted_Core0InternalBehavior/GetEventUdsStatus, operation=EvtInfo_AutoCreatedDemEvent_CC_DisablePDUGroup_CIOM_oBackbone1J1939_Rx_BC_405bc776_BswMReportFailToDemRef.GetEventUdsStatus
        OpEventGetEventUdsStatus_GetEventUdsStatus_EvtInfo_AutoCreatedDemEvent_CC_EnablePDUGroup_CIOM_oBackbone1J1939_Rx_BC_405_d65316fb: start-on-event=DemSatellite_OsApplication_Untrusted_Core0InternalBehavior/GetEventUdsStatus, operation=EvtInfo_AutoCreatedDemEvent_CC_EnablePDUGroup_CIOM_oBackbone1J1939_Rx_BC_405bc776_BswMReportFailToDemRef.GetEventUdsStatus
        OpEventGetEventUdsStatus_GetEventUdsStatus_EvtInfo_AutoCreatedDemEvent_CC_EnablePDUGroup_CIOM_oLIN02_Tx_214b70a7_BswMRe_2c7650a8: start-on-event=DemSatellite_OsApplication_Untrusted_Core0InternalBehavior/GetEventUdsStatus, operation=EvtInfo_AutoCreatedDemEvent_CC_EnablePDUGroup_CIOM_oLIN02_Tx_214b70a7_BswMReportFailToDemRef.GetEventUdsStatus
        OpEventGetEventUdsStatus_GetEventUdsStatus_EvtInfo_AutoCreatedDemEvent_CC_EnablePDUGroup_CIOM_oLIN02_Rx_7711d721_BswMRe_fabc93ca: start-on-event=DemSatellite_OsApplication_Untrusted_Core0InternalBehavior/GetEventUdsStatus, operation=EvtInfo_AutoCreatedDemEvent_CC_EnablePDUGroup_CIOM_oLIN02_Rx_7711d721_BswMReportFailToDemRef.GetEventUdsStatus
        OpEventGetEventUdsStatus_GetEventUdsStatus_EvtInfo_AutoCreatedDemEvent_CC_EnablePDUGroup_CIOM_oLIN01_Tx_33fedf49_BswMRe_cde633bb: start-on-event=DemSatellite_OsApplication_Untrusted_Core0InternalBehavior/GetEventUdsStatus, operation=EvtInfo_AutoCreatedDemEvent_CC_EnablePDUGroup_CIOM_oLIN01_Tx_33fedf49_BswMReportFailToDemRef.GetEventUdsStatus
        OpEventGetEventUdsStatus_GetEventUdsStatus_EvtInfo_AutoCreatedDemEvent_CC_EnablePDUGroup_CIOM_oLIN01_Rx_65a478cf_BswMRe_f3d69931: start-on-event=DemSatellite_OsApplication_Untrusted_Core0InternalBehavior/GetEventUdsStatus, operation=EvtInfo_AutoCreatedDemEvent_CC_EnablePDUGroup_CIOM_oLIN01_Rx_65a478cf_BswMReportFailToDemRef.GetEventUdsStatus
        OpEventGetEventUdsStatus_GetEventUdsStatus_EvtInfo_AutoCreatedDemEvent_CC_DisablePDUGroup_CIOM_oLIN03_Tx_99f717c2_BswMR_67615d0c: start-on-event=DemSatellite_OsApplication_Untrusted_Core0InternalBehavior/GetEventUdsStatus, operation=EvtInfo_AutoCreatedDemEvent_CC_DisablePDUGroup_CIOM_oLIN03_Tx_99f717c2_BswMReportFailToDemRef.GetEventUdsStatus
        OpEventGetEventUdsStatus_GetEventUdsStatus_EvtInfo_AutoCreatedDemEvent_CC_DisablePDUGroup_CIOM_oLIN03_Rx_cfadb044_BswMR_5ecc38f2: start-on-event=DemSatellite_OsApplication_Untrusted_Core0InternalBehavior/GetEventUdsStatus, operation=EvtInfo_AutoCreatedDemEvent_CC_DisablePDUGroup_CIOM_oLIN03_Rx_cfadb044_BswMReportFailToDemRef.GetEventUdsStatus
        OpEventGetEventUdsStatus_GetEventUdsStatus_EvtInfo_AutoCreatedDemEvent_CC_DisableDM_CIOM_oFMSNet_Rx_BC_dd2c1510_BswMRep_2f60ad39: start-on-event=DemSatellite_OsApplication_Untrusted_Core0InternalBehavior/GetEventUdsStatus, operation=EvtInfo_AutoCreatedDemEvent_CC_DisableDM_CIOM_oFMSNet_Rx_BC_dd2c1510_BswMReportFailToDemRef.GetEventUdsStatus
        OpEventGetEventUdsStatus_GetEventUdsStatus_EvtInfo_AutoCreatedDemEvent_CC_EnableDM_CIOM_oFMSNet_Rx_BC_dd2c1510_BswMRepo_c6f08c19: start-on-event=DemSatellite_OsApplication_Untrusted_Core0InternalBehavior/GetEventUdsStatus, operation=EvtInfo_AutoCreatedDemEvent_CC_EnableDM_CIOM_oFMSNet_Rx_BC_dd2c1510_BswMReportFailToDemRef.GetEventUdsStatus
        OpEventGetEventUdsStatus_GetEventUdsStatus_EvtInfo_AutoCreatedDemEvent_CC_EnablePDUGroup_CIOM_oLIN03_Tx_99f717c2_BswMRe_be8c8060: start-on-event=DemSatellite_OsApplication_Untrusted_Core0InternalBehavior/GetEventUdsStatus, operation=EvtInfo_AutoCreatedDemEvent_CC_EnablePDUGroup_CIOM_oLIN03_Tx_99f717c2_BswMReportFailToDemRef.GetEventUdsStatus
        OpEventGetEventUdsStatus_GetEventUdsStatus_EvtInfo_AutoCreatedDemEvent_CC_EnablePDUGroup_CIOM_oLIN03_Rx_cfadb044_BswMRe_8721e59e: start-on-event=DemSatellite_OsApplication_Untrusted_Core0InternalBehavior/GetEventUdsStatus, operation=EvtInfo_AutoCreatedDemEvent_CC_EnablePDUGroup_CIOM_oLIN03_Rx_cfadb044_BswMReportFailToDemRef.GetEventUdsStatus
        OpEventGetEventUdsStatus_GetEventUdsStatus_EvtInfo_AutoCreatedDemEvent_CC_DisablePDUGroup_CIOM_oLIN02_Tx_214b70a7_BswMR_f59b8dc4: start-on-event=DemSatellite_OsApplication_Untrusted_Core0InternalBehavior/GetEventUdsStatus, operation=EvtInfo_AutoCreatedDemEvent_CC_DisablePDUGroup_CIOM_oLIN02_Tx_214b70a7_BswMReportFailToDemRef.GetEventUdsStatus
        OpEventGetEventUdsStatus_GetEventUdsStatus_EvtInfo_AutoCreatedDemEvent_CC_DisablePDUGroup_CIOM_oLIN02_Rx_7711d721_BswMR_23514ea6: start-on-event=DemSatellite_OsApplication_Untrusted_Core0InternalBehavior/GetEventUdsStatus, operation=EvtInfo_AutoCreatedDemEvent_CC_DisablePDUGroup_CIOM_oLIN02_Rx_7711d721_BswMReportFailToDemRef.GetEventUdsStatus
        OpEventGetEventUdsStatus_GetEventUdsStatus_EvtInfo_AutoCreatedDemEvent_CC_DisablePDUGroup_CIOM_oCabSubnet_Rx_063a5fbc_B_3d2445c0: start-on-event=DemSatellite_OsApplication_Untrusted_Core0InternalBehavior/GetEventUdsStatus, operation=EvtInfo_AutoCreatedDemEvent_CC_DisablePDUGroup_CIOM_oCabSubnet_Rx_063a5fbc_BswMReportFailToDemRef.GetEventUdsStatus
        OpEventGetEventUdsStatus_GetEventUdsStatus_EvtInfo_AutoCreatedDemEvent_CC_EnablePDUGroup_CIOM_oCabSubnet_Rx_063a5fbc_Bs_dd5a4cc9: start-on-event=DemSatellite_OsApplication_Untrusted_Core0InternalBehavior/GetEventUdsStatus, operation=EvtInfo_AutoCreatedDemEvent_CC_EnablePDUGroup_CIOM_oCabSubnet_Rx_063a5fbc_BswMReportFailToDemRef.GetEventUdsStatus
        OpEventGetEventUdsStatus_GetEventUdsStatus_EvtInfo_AutoCreatedDemEvent_CC_DisablePDUGroup_CIOM_oFMSNet_Rx_BC_dd2c1510_B_75d3dd1d: start-on-event=DemSatellite_OsApplication_Untrusted_Core0InternalBehavior/GetEventUdsStatus, operation=EvtInfo_AutoCreatedDemEvent_CC_DisablePDUGroup_CIOM_oFMSNet_Rx_BC_dd2c1510_BswMReportFailToDemRef.GetEventUdsStatus
        OpEventGetEventUdsStatus_GetEventUdsStatus_EvtInfo_AutoCreatedDemEvent_CC_EnablePDUGroup_CIOM_oFMSNet_Rx_BC_dd2c1510_Bs_95add414: start-on-event=DemSatellite_OsApplication_Untrusted_Core0InternalBehavior/GetEventUdsStatus, operation=EvtInfo_AutoCreatedDemEvent_CC_EnablePDUGroup_CIOM_oFMSNet_Rx_BC_dd2c1510_BswMReportFailToDemRef.GetEventUdsStatus
        OpEventGetEventUdsStatus_GetEventUdsStatus_EvtInfo_AutoCreatedDemEvent_CC_DisablePDUGroup_CIOM_oSecuritySubnet_Rx_3a3c1_88a29888: start-on-event=DemSatellite_OsApplication_Untrusted_Core0InternalBehavior/GetEventUdsStatus, operation=EvtInfo_AutoCreatedDemEvent_CC_DisablePDUGroup_CIOM_oSecuritySubnet_Rx_3a3c1dbc_BswMReportFailToDemRef.GetEventUdsStatus
        OpEventGetEventUdsStatus_GetEventUdsStatus_EvtInfo_AutoCreatedDemEvent_CC_EnablePDUGroup_CIOM_oSecuritySubnet_Rx_3a3c1d_f8ab03c5: start-on-event=DemSatellite_OsApplication_Untrusted_Core0InternalBehavior/GetEventUdsStatus, operation=EvtInfo_AutoCreatedDemEvent_CC_EnablePDUGroup_CIOM_oSecuritySubnet_Rx_3a3c1dbc_BswMReportFailToDemRef.GetEventUdsStatus
        OpEventGetEventUdsStatus_GetEventUdsStatus_EvtInfo_AutoCreatedDemEvent_CC_DisablePDUGroup_CIOM_oFMSNet_Tx_0x31_BC_38fc8_a7c03585: start-on-event=DemSatellite_OsApplication_Untrusted_Core0InternalBehavior/GetEventUdsStatus, operation=EvtInfo_AutoCreatedDemEvent_CC_DisablePDUGroup_CIOM_oFMSNet_Tx_0x31_BC_38fc8c7d_BswMReportFailToDemRef.GetEventUdsStatus
        OpEventGetEventUdsStatus_GetEventUdsStatus_EvtInfo_AutoCreatedDemEvent_CC_EnablePDUGroup_CIOM_oFMSNet_Tx_0x31_BC_38fc8c_d7c9aec8: start-on-event=DemSatellite_OsApplication_Untrusted_Core0InternalBehavior/GetEventUdsStatus, operation=EvtInfo_AutoCreatedDemEvent_CC_EnablePDUGroup_CIOM_oFMSNet_Tx_0x31_BC_38fc8c7d_BswMReportFailToDemRef.GetEventUdsStatus
        OpEventGetEventUdsStatus_GetEventUdsStatus_EvtInfo_AutoCreatedDemEvent_CC_DisablePDUGroup_CIOM_oSecuritySubnet_Tx_6c66b_467d2ae9: start-on-event=DemSatellite_OsApplication_Untrusted_Core0InternalBehavior/GetEventUdsStatus, operation=EvtInfo_AutoCreatedDemEvent_CC_DisablePDUGroup_CIOM_oSecuritySubnet_Tx_6c66ba3a_BswMReportFailToDemRef.GetEventUdsStatus
        OpEventGetEventUdsStatus_GetEventUdsStatus_EvtInfo_AutoCreatedDemEvent_CC_EnablePDUGroup_CIOM_oSecuritySubnet_Tx_6c66ba_3674b1a4: start-on-event=DemSatellite_OsApplication_Untrusted_Core0InternalBehavior/GetEventUdsStatus, operation=EvtInfo_AutoCreatedDemEvent_CC_EnablePDUGroup_CIOM_oSecuritySubnet_Tx_6c66ba3a_BswMReportFailToDemRef.GetEventUdsStatus
        OpEventGetEventUdsStatus_GetEventUdsStatus_EvtInfo_AutoCreatedDemEvent_CC_DisablePDUGroup_CIOM_oLIN00_Tx_8b42b82c_BswMR_740280ad: start-on-event=DemSatellite_OsApplication_Untrusted_Core0InternalBehavior/GetEventUdsStatus, operation=EvtInfo_AutoCreatedDemEvent_CC_DisablePDUGroup_CIOM_oLIN00_Tx_8b42b82c_BswMReportFailToDemRef.GetEventUdsStatus
        OpEventGetEventUdsStatus_GetEventUdsStatus_EvtInfo_AutoCreatedDemEvent_CC_EnablePDUGroup_CIOM_oLIN00_Rx_dd181faa_BswMRe_2c1b2f62: start-on-event=DemSatellite_OsApplication_Untrusted_Core0InternalBehavior/GetEventUdsStatus, operation=EvtInfo_AutoCreatedDemEvent_CC_EnablePDUGroup_CIOM_oLIN00_Rx_dd181faa_BswMReportFailToDemRef.GetEventUdsStatus
        OpEventGetEventUdsStatus_GetEventUdsStatus_EvtInfo_AutoCreatedDemEvent_ESH_Action_ComMCheckPendingRequests_BswMReportFa_9888ae1f: start-on-event=DemSatellite_OsApplication_Untrusted_Core0InternalBehavior/GetEventUdsStatus, operation=EvtInfo_AutoCreatedDemEvent_ESH_Action_ComMCheckPendingRequests_BswMReportFailToDemRef.GetEventUdsStatus
        OpEventGetEventUdsStatus_GetEventUdsStatus_EvtInfo_AutoCreatedDemEvent_CC_DisableDM_CIOM_oBackbone1J1939_Rx_BC_405bc776_3ad1e95b: start-on-event=DemSatellite_OsApplication_Untrusted_Core0InternalBehavior/GetEventUdsStatus, operation=EvtInfo_AutoCreatedDemEvent_CC_DisableDM_CIOM_oBackbone1J1939_Rx_BC_405bc776_BswMReportFailToDemRef.GetEventUdsStatus
        OpEventGetEventUdsStatus_GetEventUdsStatus_EvtInfo_AutoCreatedDemEvent_CC_DisablePDUGroup_CIOM_oLIN00_Rx_dd181faa_BswMR_f5f6f20e: start-on-event=DemSatellite_OsApplication_Untrusted_Core0InternalBehavior/GetEventUdsStatus, operation=EvtInfo_AutoCreatedDemEvent_CC_DisablePDUGroup_CIOM_oLIN00_Rx_dd181faa_BswMReportFailToDemRef.GetEventUdsStatus
        OpEventGetEventUdsStatus_GetEventUdsStatus_EvtInfo_AutoCreatedDemEvent_CC_EnablePDUGroup_CIOM_oLIN00_Tx_8b42b82c_BswMRe_adef5dc1: start-on-event=DemSatellite_OsApplication_Untrusted_Core0InternalBehavior/GetEventUdsStatus, operation=EvtInfo_AutoCreatedDemEvent_CC_EnablePDUGroup_CIOM_oLIN00_Tx_8b42b82c_BswMReportFailToDemRef.GetEventUdsStatus
        OpEventGetEventUdsStatus_GetEventUdsStatus_EvtInfo_AutoCreatedDemEvent_ESH_Action_EnterExclusiveArea_BswMReportFailToDemRef: start-on-event=DemSatellite_OsApplication_Untrusted_Core0InternalBehavior/GetEventUdsStatus, operation=EvtInfo_AutoCreatedDemEvent_ESH_Action_EnterExclusiveArea_BswMReportFailToDemRef.GetEventUdsStatus
        OpEventGetEventUdsStatus_GetEventUdsStatus_EvtInfo_AutoCreatedDemEvent_ESH_RunToPostRunNested_BswMReportFailToDemRef: start-on-event=DemSatellite_OsApplication_Untrusted_Core0InternalBehavior/GetEventUdsStatus, operation=EvtInfo_AutoCreatedDemEvent_ESH_RunToPostRunNested_BswMReportFailToDemRef.GetEventUdsStatus
        OpEventGetEventUdsStatus_GetEventUdsStatus_EvtInfo_AutoCreatedDemEvent_CC_EnableDM_CIOM_oBackbone1J1939_Rx_BC_405bc776_92cf0ac8: start-on-event=DemSatellite_OsApplication_Untrusted_Core0InternalBehavior/GetEventUdsStatus, operation=EvtInfo_AutoCreatedDemEvent_CC_EnableDM_CIOM_oBackbone1J1939_Rx_BC_405bc776_BswMReportFailToDemRef.GetEventUdsStatus
        OpEventGetEventUdsStatus_GetEventUdsStatus_EvtInfo_AutoCreatedDemEvent_CC_DisablePDUGroup_CIOM_oBackbone1J1939_Tx_0x31_31057a67: start-on-event=DemSatellite_OsApplication_Untrusted_Core0InternalBehavior/GetEventUdsStatus, operation=EvtInfo_AutoCreatedDemEvent_CC_DisablePDUGroup_CIOM_oBackbone1J1939_Tx_0x31_BC_3782f500_BswMReportFailToDemRef.GetEventUdsStatus
        OpEventGetEventUdsStatus_GetEventUdsStatus_EvtInfo_AutoCreatedDemEvent_CC_J1939RmStateSwitch_CN_FMSNet_fce1aae5_CIOM_3a_542bd9da: start-on-event=DemSatellite_OsApplication_Untrusted_Core0InternalBehavior/GetEventUdsStatus, operation=EvtInfo_AutoCreatedDemEvent_CC_J1939RmStateSwitch_CN_FMSNet_fce1aae5_CIOM_3a3d59b1_J1939RM_STATE_OFFLINE_BswMReportFailToDemRef.GetEventUdsStatus
        OpEventGetEventUdsStatus_GetEventUdsStatus_EvtInfo_AutoCreatedDemEvent_CC_EnablePDUGroup_CIOM_oBackbone1J1939_Tx_0x31_B_b08f3e9a: start-on-event=DemSatellite_OsApplication_Untrusted_Core0InternalBehavior/GetEventUdsStatus, operation=EvtInfo_AutoCreatedDemEvent_CC_EnablePDUGroup_CIOM_oBackbone1J1939_Tx_0x31_BC_3782f500_BswMReportFailToDemRef.GetEventUdsStatus
        OpEventGetEventUdsStatus_GetEventUdsStatus_EvtInfo_AutoCreatedDemEvent_CC_J1939RmStateSwitch_CN_FMSNet_fce1aae5_CIOM_3a_2fc8532f: start-on-event=DemSatellite_OsApplication_Untrusted_Core0InternalBehavior/GetEventUdsStatus, operation=EvtInfo_AutoCreatedDemEvent_CC_J1939RmStateSwitch_CN_FMSNet_fce1aae5_CIOM_3a3d59b1_J1939RM_STATE_ONLINE_BswMReportFailToDemRef.GetEventUdsStatus
        OpEventGetEventUdsStatus_GetEventUdsStatus_EvtInfo_AutoCreatedDemEvent_ESH_Action_CancelNvMWriteAll_BswMReportFailToDemRef: start-on-event=DemSatellite_OsApplication_Untrusted_Core0InternalBehavior/GetEventUdsStatus, operation=EvtInfo_AutoCreatedDemEvent_ESH_Action_CancelNvMWriteAll_BswMReportFailToDemRef.GetEventUdsStatus
        OpEventGetEventUdsStatus_GetEventUdsStatus_EvtInfo_AutoCreatedDemEvent_ESH_Action_CancelWriteAllTimer_Start_BswMReportF_192df56a: start-on-event=DemSatellite_OsApplication_Untrusted_Core0InternalBehavior/GetEventUdsStatus, operation=EvtInfo_AutoCreatedDemEvent_ESH_Action_CancelWriteAllTimer_Start_BswMReportFailToDemRef.GetEventUdsStatus
        OpEventGetEventUdsStatus_GetEventUdsStatus_EvtInfo_AutoCreatedDemEvent_ESH_Action_CancelWriteAllTimer_Stop_BswMReportFa_0675b9c6: start-on-event=DemSatellite_OsApplication_Untrusted_Core0InternalBehavior/GetEventUdsStatus, operation=EvtInfo_AutoCreatedDemEvent_ESH_Action_CancelWriteAllTimer_Stop_BswMReportFailToDemRef.GetEventUdsStatus
        OpEventGetEventUdsStatus_GetEventUdsStatus_EvtInfo_AutoCreatedDemEvent_ESH_Action_ComMAllow_CN_Backbone1J1939_0b1f4bae_0ced31df: start-on-event=DemSatellite_OsApplication_Untrusted_Core0InternalBehavior/GetEventUdsStatus, operation=EvtInfo_AutoCreatedDemEvent_ESH_Action_ComMAllow_CN_Backbone1J1939_0b1f4bae_BswMReportFailToDemRef.GetEventUdsStatus
        OpEventGetEventUdsStatus_GetEventUdsStatus_EvtInfo_AutoCreatedDemEvent_ESH_Action_ComMAllow_CN_Backbone1J1939_0b1f4bae_7a5a8659: start-on-event=DemSatellite_OsApplication_Untrusted_Core0InternalBehavior/GetEventUdsStatus, operation=EvtInfo_AutoCreatedDemEvent_ESH_Action_ComMAllow_CN_Backbone1J1939_0b1f4bae_BswMReportFailToDemRef_1.GetEventUdsStatus
        OpEventGetEventUdsStatus_GetEventUdsStatus_EvtInfo_AutoCreatedDemEvent_ESH_Action_ComMAllow_CN_Backbone2_78967e2c_BswMR_bf3a8d3a: start-on-event=DemSatellite_OsApplication_Untrusted_Core0InternalBehavior/GetEventUdsStatus, operation=EvtInfo_AutoCreatedDemEvent_ESH_Action_ComMAllow_CN_Backbone2_78967e2c_BswMReportFailToDemRef.GetEventUdsStatus
        OpEventGetEventUdsStatus_GetEventUdsStatus_EvtInfo_AutoCreatedDemEvent_ESH_Action_ComMAllow_CN_Backbone2_78967e2c_BswMR_9b84cd80: start-on-event=DemSatellite_OsApplication_Untrusted_Core0InternalBehavior/GetEventUdsStatus, operation=EvtInfo_AutoCreatedDemEvent_ESH_Action_ComMAllow_CN_Backbone2_78967e2c_BswMReportFailToDemRef_1.GetEventUdsStatus
        OpEventGetEventUdsStatus_GetEventUdsStatus_EvtInfo_AutoCreatedDemEvent_ESH_Action_ComMAllow_CN_CabSubnet_9ea693f1_BswMR_62f8bb4c: start-on-event=DemSatellite_OsApplication_Untrusted_Core0InternalBehavior/GetEventUdsStatus, operation=EvtInfo_AutoCreatedDemEvent_ESH_Action_ComMAllow_CN_CabSubnet_9ea693f1_BswMReportFailToDemRef.GetEventUdsStatus
        OpEventGetEventUdsStatus_GetEventUdsStatus_EvtInfo_AutoCreatedDemEvent_ESH_Action_ComMAllow_CN_CabSubnet_9ea693f1_BswMR_2d5b5bab: start-on-event=DemSatellite_OsApplication_Untrusted_Core0InternalBehavior/GetEventUdsStatus, operation=EvtInfo_AutoCreatedDemEvent_ESH_Action_ComMAllow_CN_CabSubnet_9ea693f1_BswMReportFailToDemRef_1.GetEventUdsStatus
        OpEventGetEventUdsStatus_GetEventUdsStatus_EvtInfo_AutoCreatedDemEvent_ESH_Action_ComMAllow_CN_FMSNet_fce1aae5_BswMRepo_9bf6c4cc: start-on-event=DemSatellite_OsApplication_Untrusted_Core0InternalBehavior/GetEventUdsStatus, operation=EvtInfo_AutoCreatedDemEvent_ESH_Action_ComMAllow_CN_FMSNet_fce1aae5_BswMReportFailToDemRef.GetEventUdsStatus
        OpEventGetEventUdsStatus_GetEventUdsStatus_EvtInfo_AutoCreatedDemEvent_ESH_Action_ComMAllow_CN_FMSNet_fce1aae5_BswMRepo_d6625643: start-on-event=DemSatellite_OsApplication_Untrusted_Core0InternalBehavior/GetEventUdsStatus, operation=EvtInfo_AutoCreatedDemEvent_ESH_Action_ComMAllow_CN_FMSNet_fce1aae5_BswMReportFailToDemRef_1.GetEventUdsStatus
        OpEventGetEventUdsStatus_GetEventUdsStatus_EvtInfo_AutoCreatedDemEvent_ESH_Action_ComMAllow_CN_LIN00_2cd9a7df_BswMRepor_a371235a: start-on-event=DemSatellite_OsApplication_Untrusted_Core0InternalBehavior/GetEventUdsStatus, operation=EvtInfo_AutoCreatedDemEvent_ESH_Action_ComMAllow_CN_LIN00_2cd9a7df_BswMReportFailToDemRef.GetEventUdsStatus
        OpEventGetEventUdsStatus_GetEventUdsStatus_EvtInfo_AutoCreatedDemEvent_ESH_Action_ComMAllow_CN_LIN00_2cd9a7df_BswMRepor_cf173483: start-on-event=DemSatellite_OsApplication_Untrusted_Core0InternalBehavior/GetEventUdsStatus, operation=EvtInfo_AutoCreatedDemEvent_ESH_Action_ComMAllow_CN_LIN00_2cd9a7df_BswMReportFailToDemRef_1.GetEventUdsStatus
        OpEventGetEventUdsStatus_GetEventUdsStatus_EvtInfo_AutoCreatedDemEvent_ESH_Action_ComMAllow_CN_LIN01_5bde9749_BswMRepor_9bc1a486: start-on-event=DemSatellite_OsApplication_Untrusted_Core0InternalBehavior/GetEventUdsStatus, operation=EvtInfo_AutoCreatedDemEvent_ESH_Action_ComMAllow_CN_LIN01_5bde9749_BswMReportFailToDemRef.GetEventUdsStatus
        OpEventGetEventUdsStatus_GetEventUdsStatus_EvtInfo_AutoCreatedDemEvent_ESH_Action_ComMAllow_CN_LIN01_5bde9749_BswMRepor_914690a3: start-on-event=DemSatellite_OsApplication_Untrusted_Core0InternalBehavior/GetEventUdsStatus, operation=EvtInfo_AutoCreatedDemEvent_ESH_Action_ComMAllow_CN_LIN01_5bde9749_BswMReportFailToDemRef_1.GetEventUdsStatus
        OpEventGetEventUdsStatus_GetEventUdsStatus_EvtInfo_AutoCreatedDemEvent_ESH_Action_ComMAllow_CN_LIN02_c2d7c6f3_BswMRepor_66bc58e2: start-on-event=DemSatellite_OsApplication_Untrusted_Core0InternalBehavior/GetEventUdsStatus, operation=EvtInfo_AutoCreatedDemEvent_ESH_Action_ComMAllow_CN_LIN02_c2d7c6f3_BswMReportFailToDemRef.GetEventUdsStatus
        OpEventGetEventUdsStatus_GetEventUdsStatus_EvtInfo_AutoCreatedDemEvent_ESH_Action_ComMAllow_CN_LIN02_c2d7c6f3_BswMRepor_24dc7d4a: start-on-event=DemSatellite_OsApplication_Untrusted_Core0InternalBehavior/GetEventUdsStatus, operation=EvtInfo_AutoCreatedDemEvent_ESH_Action_ComMAllow_CN_LIN02_c2d7c6f3_BswMReportFailToDemRef_1.GetEventUdsStatus
        OpEventGetEventUdsStatus_GetEventUdsStatus_EvtInfo_AutoCreatedDemEvent_ESH_Action_ComMAllow_CN_LIN03_b5d0f665_BswMRepor_b348e468: start-on-event=DemSatellite_OsApplication_Untrusted_Core0InternalBehavior/GetEventUdsStatus, operation=EvtInfo_AutoCreatedDemEvent_ESH_Action_ComMAllow_CN_LIN03_b5d0f665_BswMReportFailToDemRef.GetEventUdsStatus
        OpEventGetEventUdsStatus_GetEventUdsStatus_EvtInfo_AutoCreatedDemEvent_ESH_Action_ComMAllow_CN_LIN03_b5d0f665_BswMRepor_276727d8: start-on-event=DemSatellite_OsApplication_Untrusted_Core0InternalBehavior/GetEventUdsStatus, operation=EvtInfo_AutoCreatedDemEvent_ESH_Action_ComMAllow_CN_LIN03_b5d0f665_BswMReportFailToDemRef_1.GetEventUdsStatus
        OpEventGetEventUdsStatus_GetEventUdsStatus_EvtInfo_AutoCreatedDemEvent_ESH_Action_ComMAllow_CN_LIN04_2bb463c6_BswMRepor_4c061bbe: start-on-event=DemSatellite_OsApplication_Untrusted_Core0InternalBehavior/GetEventUdsStatus, operation=EvtInfo_AutoCreatedDemEvent_ESH_Action_ComMAllow_CN_LIN04_2bb463c6_BswMReportFailToDemRef.GetEventUdsStatus
        OpEventGetEventUdsStatus_GetEventUdsStatus_EvtInfo_AutoCreatedDemEvent_ESH_Action_ComMAllow_CN_LIN04_2bb463c6_BswMRepor_dd075582: start-on-event=DemSatellite_OsApplication_Untrusted_Core0InternalBehavior/GetEventUdsStatus, operation=EvtInfo_AutoCreatedDemEvent_ESH_Action_ComMAllow_CN_LIN04_2bb463c6_BswMReportFailToDemRef_1.GetEventUdsStatus
        OpEventGetEventUdsStatus_GetEventUdsStatus_EvtInfo_AutoCreatedDemEvent_ESH_Action_ComMAllow_CN_SecuritySubnet_e7a0ee54_a267b019: start-on-event=DemSatellite_OsApplication_Untrusted_Core0InternalBehavior/GetEventUdsStatus, operation=EvtInfo_AutoCreatedDemEvent_ESH_Action_ComMAllow_CN_SecuritySubnet_e7a0ee54_BswMReportFailToDemRef.GetEventUdsStatus
        OpEventGetEventUdsStatus_GetEventUdsStatus_EvtInfo_AutoCreatedDemEvent_ESH_Action_ComMAllow_CN_SecuritySubnet_e7a0ee54_7d45ebad: start-on-event=DemSatellite_OsApplication_Untrusted_Core0InternalBehavior/GetEventUdsStatus, operation=EvtInfo_AutoCreatedDemEvent_ESH_Action_ComMAllow_CN_SecuritySubnet_e7a0ee54_BswMReportFailToDemRef_1.GetEventUdsStatus
        OpEventGetEventUdsStatus_GetEventUdsStatus_EvtInfo_AutoCreatedDemEvent_ESH_Action_ComMCheckPendingRequests_BswMReportFa_d1104ba7: start-on-event=DemSatellite_OsApplication_Untrusted_Core0InternalBehavior/GetEventUdsStatus, operation=EvtInfo_AutoCreatedDemEvent_ESH_Action_ComMCheckPendingRequests_BswMReportFailToDemRef_1.GetEventUdsStatus
        OpEventGetEventUdsStatus_GetEventUdsStatus_EvtInfo_AutoCreatedDemEvent_ESH_Action_ComMCheckPendingRequests_BswMReportFa_48191a1d: start-on-event=DemSatellite_OsApplication_Untrusted_Core0InternalBehavior/GetEventUdsStatus, operation=EvtInfo_AutoCreatedDemEvent_ESH_Action_ComMCheckPendingRequests_BswMReportFailToDemRef_2.GetEventUdsStatus
        OpEventGetEventUdsStatus_GetEventUdsStatus_EvtInfo_AutoCreatedDemEvent_ESH_Action_ComMDisallow_CN_Backbone1J1939_0b1f4b_e40cdcc2: start-on-event=DemSatellite_OsApplication_Untrusted_Core0InternalBehavior/GetEventUdsStatus, operation=EvtInfo_AutoCreatedDemEvent_ESH_Action_ComMDisallow_CN_Backbone1J1939_0b1f4bae_BswMReportFailToDemRef.GetEventUdsStatus
        OpEventGetEventUdsStatus_GetEventUdsStatus_EvtInfo_AutoCreatedDemEvent_ESH_Action_ComMDisallow_CN_Backbone2_78967e2c_Bs_b1edb817: start-on-event=DemSatellite_OsApplication_Untrusted_Core0InternalBehavior/GetEventUdsStatus, operation=EvtInfo_AutoCreatedDemEvent_ESH_Action_ComMDisallow_CN_Backbone2_78967e2c_BswMReportFailToDemRef.GetEventUdsStatus
        OpEventGetEventUdsStatus_GetEventUdsStatus_EvtInfo_AutoCreatedDemEvent_ESH_Action_ComMDisallow_CN_CabSubnet_9ea693f1_Bs_6c2f8e61: start-on-event=DemSatellite_OsApplication_Untrusted_Core0InternalBehavior/GetEventUdsStatus, operation=EvtInfo_AutoCreatedDemEvent_ESH_Action_ComMDisallow_CN_CabSubnet_9ea693f1_BswMReportFailToDemRef.GetEventUdsStatus
        OpEventGetEventUdsStatus_GetEventUdsStatus_EvtInfo_AutoCreatedDemEvent_ESH_Action_ComMDisallow_CN_FMSNet_fce1aae5_BswMR_44192e03: start-on-event=DemSatellite_OsApplication_Untrusted_Core0InternalBehavior/GetEventUdsStatus, operation=EvtInfo_AutoCreatedDemEvent_ESH_Action_ComMDisallow_CN_FMSNet_fce1aae5_BswMReportFailToDemRef.GetEventUdsStatus
        OpEventGetEventUdsStatus_GetEventUdsStatus_EvtInfo_AutoCreatedDemEvent_ESH_Action_ComMDisallow_CN_LIN00_2cd9a7df_BswMRe_2c742ff6: start-on-event=DemSatellite_OsApplication_Untrusted_Core0InternalBehavior/GetEventUdsStatus, operation=EvtInfo_AutoCreatedDemEvent_ESH_Action_ComMDisallow_CN_LIN00_2cd9a7df_BswMReportFailToDemRef.GetEventUdsStatus
        OpEventGetEventUdsStatus_GetEventUdsStatus_EvtInfo_AutoCreatedDemEvent_ESH_Action_ComMDisallow_CN_LIN01_5bde9749_BswMRe_14c4a82a: start-on-event=DemSatellite_OsApplication_Untrusted_Core0InternalBehavior/GetEventUdsStatus, operation=EvtInfo_AutoCreatedDemEvent_ESH_Action_ComMDisallow_CN_LIN01_5bde9749_BswMReportFailToDemRef.GetEventUdsStatus
        OpEventGetEventUdsStatus_GetEventUdsStatus_EvtInfo_AutoCreatedDemEvent_ESH_Action_ComMDisallow_CN_LIN02_c2d7c6f3_BswMRe_e9b9544e: start-on-event=DemSatellite_OsApplication_Untrusted_Core0InternalBehavior/GetEventUdsStatus, operation=EvtInfo_AutoCreatedDemEvent_ESH_Action_ComMDisallow_CN_LIN02_c2d7c6f3_BswMReportFailToDemRef.GetEventUdsStatus
        OpEventGetEventUdsStatus_GetEventUdsStatus_EvtInfo_AutoCreatedDemEvent_ESH_Action_ComMDisallow_CN_LIN03_b5d0f665_BswMRe_3c4de8c4: start-on-event=DemSatellite_OsApplication_Untrusted_Core0InternalBehavior/GetEventUdsStatus, operation=EvtInfo_AutoCreatedDemEvent_ESH_Action_ComMDisallow_CN_LIN03_b5d0f665_BswMReportFailToDemRef.GetEventUdsStatus
        OpEventGetEventUdsStatus_GetEventUdsStatus_EvtInfo_AutoCreatedDemEvent_ESH_Action_ComMDisallow_CN_LIN04_2bb463c6_BswMRe_c3031712: start-on-event=DemSatellite_OsApplication_Untrusted_Core0InternalBehavior/GetEventUdsStatus, operation=EvtInfo_AutoCreatedDemEvent_ESH_Action_ComMDisallow_CN_LIN04_2bb463c6_BswMReportFailToDemRef.GetEventUdsStatus
        OpEventGetEventUdsStatus_GetEventUdsStatus_EvtInfo_AutoCreatedDemEvent_ESH_Action_ComMDisallow_CN_SecuritySubnet_e7a0ee_4a865d04: start-on-event=DemSatellite_OsApplication_Untrusted_Core0InternalBehavior/GetEventUdsStatus, operation=EvtInfo_AutoCreatedDemEvent_ESH_Action_ComMDisallow_CN_SecuritySubnet_e7a0ee54_BswMReportFailToDemRef.GetEventUdsStatus
        OpEventGetEventUdsStatus_GetEventUdsStatus_EvtInfo_AutoCreatedDemEvent_ESH_Action_DemInit_BswMReportFailToDemRef: start-on-event=DemSatellite_OsApplication_Untrusted_Core0InternalBehavior/GetEventUdsStatus, operation=EvtInfo_AutoCreatedDemEvent_ESH_Action_DemInit_BswMReportFailToDemRef.GetEventUdsStatus
        OpEventGetEventUdsStatus_GetEventUdsStatus_EvtInfo_AutoCreatedDemEvent_ESH_Action_DemInitialized_BswMReportFailToDemRef: start-on-event=DemSatellite_OsApplication_Untrusted_Core0InternalBehavior/GetEventUdsStatus, operation=EvtInfo_AutoCreatedDemEvent_ESH_Action_DemInitialized_BswMReportFailToDemRef.GetEventUdsStatus
        OpEventGetEventUdsStatus_GetEventUdsStatus_EvtInfo_AutoCreatedDemEvent_ESH_Action_DemNotInitialized_BswMReportFailToDemRef: start-on-event=DemSatellite_OsApplication_Untrusted_Core0InternalBehavior/GetEventUdsStatus, operation=EvtInfo_AutoCreatedDemEvent_ESH_Action_DemNotInitialized_BswMReportFailToDemRef.GetEventUdsStatus
        OpEventGetEventUdsStatus_GetEventUdsStatus_EvtInfo_AutoCreatedDemEvent_ESH_Action_DemShutdown_BswMReportFailToDemRef: start-on-event=DemSatellite_OsApplication_Untrusted_Core0InternalBehavior/GetEventUdsStatus, operation=EvtInfo_AutoCreatedDemEvent_ESH_Action_DemShutdown_BswMReportFailToDemRef.GetEventUdsStatus
        OpEventGetEventUdsStatus_GetEventUdsStatus_EvtInfo_AutoCreatedDemEvent_ESH_Action_ESH_PostRun_BswMReportFailToDemRef: start-on-event=DemSatellite_OsApplication_Untrusted_Core0InternalBehavior/GetEventUdsStatus, operation=EvtInfo_AutoCreatedDemEvent_ESH_Action_ESH_PostRun_BswMReportFailToDemRef.GetEventUdsStatus
        OpEventGetEventUdsStatus_GetEventUdsStatus_EvtInfo_AutoCreatedDemEvent_ESH_Action_ESH_PrepShutdown_BswMReportFailToDemRef: start-on-event=DemSatellite_OsApplication_Untrusted_Core0InternalBehavior/GetEventUdsStatus, operation=EvtInfo_AutoCreatedDemEvent_ESH_Action_ESH_PrepShutdown_BswMReportFailToDemRef.GetEventUdsStatus
        OpEventGetEventUdsStatus_GetEventUdsStatus_EvtInfo_AutoCreatedDemEvent_ESH_Action_ESH_PrepShutdown_BswMReportFailToDemRef_1: start-on-event=DemSatellite_OsApplication_Untrusted_Core0InternalBehavior/GetEventUdsStatus, operation=EvtInfo_AutoCreatedDemEvent_ESH_Action_ESH_PrepShutdown_BswMReportFailToDemRef_1.GetEventUdsStatus
        OpEventGetEventUdsStatus_GetEventUdsStatus_EvtInfo_AutoCreatedDemEvent_ESH_Action_ESH_Run_BswMReportFailToDemRef: start-on-event=DemSatellite_OsApplication_Untrusted_Core0InternalBehavior/GetEventUdsStatus, operation=EvtInfo_AutoCreatedDemEvent_ESH_Action_ESH_Run_BswMReportFailToDemRef.GetEventUdsStatus
        OpEventGetEventUdsStatus_GetEventUdsStatus_EvtInfo_AutoCreatedDemEvent_ESH_Action_ESH_Run_BswMReportFailToDemRef_1: start-on-event=DemSatellite_OsApplication_Untrusted_Core0InternalBehavior/GetEventUdsStatus, operation=EvtInfo_AutoCreatedDemEvent_ESH_Action_ESH_Run_BswMReportFailToDemRef_1.GetEventUdsStatus
        OpEventGetEventUdsStatus_GetEventUdsStatus_EvtInfo_AutoCreatedDemEvent_ESH_Action_ESH_WaitForNvm_BswMReportFailToDemRef: start-on-event=DemSatellite_OsApplication_Untrusted_Core0InternalBehavior/GetEventUdsStatus, operation=EvtInfo_AutoCreatedDemEvent_ESH_Action_ESH_WaitForNvm_BswMReportFailToDemRef.GetEventUdsStatus
        OpEventGetEventUdsStatus_GetEventUdsStatus_EvtInfo_AutoCreatedDemEvent_ESH_Action_ESH_Wakeup_BswMReportFailToDemRef: start-on-event=DemSatellite_OsApplication_Untrusted_Core0InternalBehavior/GetEventUdsStatus, operation=EvtInfo_AutoCreatedDemEvent_ESH_Action_ESH_Wakeup_BswMReportFailToDemRef.GetEventUdsStatus
        OpEventGetEventUdsStatus_GetEventUdsStatus_EvtInfo_AutoCreatedDemEvent_ESH_Action_ESH_Wakeup_BswMReportFailToDemRef_1: start-on-event=DemSatellite_OsApplication_Untrusted_Core0InternalBehavior/GetEventUdsStatus, operation=EvtInfo_AutoCreatedDemEvent_ESH_Action_ESH_Wakeup_BswMReportFailToDemRef_1.GetEventUdsStatus
        OpEventGetEventUdsStatus_GetEventUdsStatus_EvtInfo_AutoCreatedDemEvent_ESH_Action_EcuMClearValidatedWakeupEvents_BswMRe_25535a63: start-on-event=DemSatellite_OsApplication_Untrusted_Core0InternalBehavior/GetEventUdsStatus, operation=EvtInfo_AutoCreatedDemEvent_ESH_Action_EcuMClearValidatedWakeupEvents_BswMReportFailToDemRef.GetEventUdsStatus
        OpEventGetEventUdsStatus_GetEventUdsStatus_EvtInfo_AutoCreatedDemEvent_ESH_Action_EcuMGoToSelectedShutdownTarget_BswMRe_8419eab5: start-on-event=DemSatellite_OsApplication_Untrusted_Core0InternalBehavior/GetEventUdsStatus, operation=EvtInfo_AutoCreatedDemEvent_ESH_Action_EcuMGoToSelectedShutdownTarget_BswMReportFailToDemRef.GetEventUdsStatus
        OpEventGetEventUdsStatus_GetEventUdsStatus_EvtInfo_AutoCreatedDemEvent_ESH_Action_EnterExclusiveArea_BswMReportFailToDemRef_1: start-on-event=DemSatellite_OsApplication_Untrusted_Core0InternalBehavior/GetEventUdsStatus, operation=EvtInfo_AutoCreatedDemEvent_ESH_Action_EnterExclusiveArea_BswMReportFailToDemRef_1.GetEventUdsStatus
        OpEventGetEventUdsStatus_GetEventUdsStatus_EvtInfo_AutoCreatedDemEvent_ESH_Action_ExitExclusiveArea_BswMReportFailToDemRef: start-on-event=DemSatellite_OsApplication_Untrusted_Core0InternalBehavior/GetEventUdsStatus, operation=EvtInfo_AutoCreatedDemEvent_ESH_Action_ExitExclusiveArea_BswMReportFailToDemRef.GetEventUdsStatus
        OpEventGetEventUdsStatus_GetEventUdsStatus_EvtInfo_AutoCreatedDemEvent_ESH_Action_NvMWriteAll_BswMReportFailToDemRef: start-on-event=DemSatellite_OsApplication_Untrusted_Core0InternalBehavior/GetEventUdsStatus, operation=EvtInfo_AutoCreatedDemEvent_ESH_Action_NvMWriteAll_BswMReportFailToDemRef.GetEventUdsStatus
        OpEventGetEventUdsStatus_GetEventUdsStatus_EvtInfo_AutoCreatedDemEvent_ESH_Action_OnEnterPostRun_BswMReportFailToDemRef: start-on-event=DemSatellite_OsApplication_Untrusted_Core0InternalBehavior/GetEventUdsStatus, operation=EvtInfo_AutoCreatedDemEvent_ESH_Action_OnEnterPostRun_BswMReportFailToDemRef.GetEventUdsStatus
        OpEventGetEventUdsStatus_GetEventUdsStatus_EvtInfo_AutoCreatedDemEvent_ESH_Action_OnEnterPrepShutdown_BswMReportFailToDemRef: start-on-event=DemSatellite_OsApplication_Untrusted_Core0InternalBehavior/GetEventUdsStatus, operation=EvtInfo_AutoCreatedDemEvent_ESH_Action_OnEnterPrepShutdown_BswMReportFailToDemRef.GetEventUdsStatus
        OpEventGetEventUdsStatus_GetEventUdsStatus_EvtInfo_AutoCreatedDemEvent_ESH_Action_OnEnterPrepShutdown_BswMReportFailToDemRef_1: start-on-event=DemSatellite_OsApplication_Untrusted_Core0InternalBehavior/GetEventUdsStatus, operation=EvtInfo_AutoCreatedDemEvent_ESH_Action_OnEnterPrepShutdown_BswMReportFailToDemRef_1.GetEventUdsStatus
        OpEventGetEventUdsStatus_GetEventUdsStatus_EvtInfo_AutoCreatedDemEvent_ESH_Action_OnEnterRun_BswMReportFailToDemRef: start-on-event=DemSatellite_OsApplication_Untrusted_Core0InternalBehavior/GetEventUdsStatus, operation=EvtInfo_AutoCreatedDemEvent_ESH_Action_OnEnterRun_BswMReportFailToDemRef.GetEventUdsStatus
        OpEventGetEventUdsStatus_GetEventUdsStatus_EvtInfo_AutoCreatedDemEvent_ESH_Action_OnEnterRun_BswMReportFailToDemRef_1: start-on-event=DemSatellite_OsApplication_Untrusted_Core0InternalBehavior/GetEventUdsStatus, operation=EvtInfo_AutoCreatedDemEvent_ESH_Action_OnEnterRun_BswMReportFailToDemRef_1.GetEventUdsStatus
        OpEventGetEventUdsStatus_GetEventUdsStatus_EvtInfo_AutoCreatedDemEvent_ESH_Action_OnEnterShutdown_BswMReportFailToDemRef: start-on-event=DemSatellite_OsApplication_Untrusted_Core0InternalBehavior/GetEventUdsStatus, operation=EvtInfo_AutoCreatedDemEvent_ESH_Action_OnEnterShutdown_BswMReportFailToDemRef.GetEventUdsStatus
        OpEventGetEventUdsStatus_GetEventUdsStatus_EvtInfo_AutoCreatedDemEvent_ESH_Action_OnEnterWaitForNvm_BswMReportFailToDemRef: start-on-event=DemSatellite_OsApplication_Untrusted_Core0InternalBehavior/GetEventUdsStatus, operation=EvtInfo_AutoCreatedDemEvent_ESH_Action_OnEnterWaitForNvm_BswMReportFailToDemRef.GetEventUdsStatus
        OpEventGetEventUdsStatus_GetEventUdsStatus_EvtInfo_AutoCreatedDemEvent_ESH_Action_OnEnterWakeup_BswMReportFailToDemRef: start-on-event=DemSatellite_OsApplication_Untrusted_Core0InternalBehavior/GetEventUdsStatus, operation=EvtInfo_AutoCreatedDemEvent_ESH_Action_OnEnterWakeup_BswMReportFailToDemRef.GetEventUdsStatus
        OpEventGetEventUdsStatus_GetEventUdsStatus_EvtInfo_AutoCreatedDemEvent_ESH_Action_OnEnterWakeup_BswMReportFailToDemRef_1: start-on-event=DemSatellite_OsApplication_Untrusted_Core0InternalBehavior/GetEventUdsStatus, operation=EvtInfo_AutoCreatedDemEvent_ESH_Action_OnEnterWakeup_BswMReportFailToDemRef_1.GetEventUdsStatus
        OpEventGetEventUdsStatus_GetEventUdsStatus_EvtInfo_AutoCreatedDemEvent_ESH_Action_SelfRunRequestTimer_Start_BswMReportF_2b5733b2: start-on-event=DemSatellite_OsApplication_Untrusted_Core0InternalBehavior/GetEventUdsStatus, operation=EvtInfo_AutoCreatedDemEvent_ESH_Action_SelfRunRequestTimer_Start_BswMReportFailToDemRef.GetEventUdsStatus
        OpEventGetEventUdsStatus_GetEventUdsStatus_EvtInfo_AutoCreatedDemEvent_ESH_Action_SelfRunRequestTimer_Start_BswMReportF_4407d525: start-on-event=DemSatellite_OsApplication_Untrusted_Core0InternalBehavior/GetEventUdsStatus, operation=EvtInfo_AutoCreatedDemEvent_ESH_Action_SelfRunRequestTimer_Start_BswMReportFailToDemRef_1.GetEventUdsStatus
        OpEventGetEventUdsStatus_GetEventUdsStatus_EvtInfo_AutoCreatedDemEvent_ESH_Action_SwitchPostRun_BswMReportFailToDemRef: start-on-event=DemSatellite_OsApplication_Untrusted_Core0InternalBehavior/GetEventUdsStatus, operation=EvtInfo_AutoCreatedDemEvent_ESH_Action_SwitchPostRun_BswMReportFailToDemRef.GetEventUdsStatus
        OpEventGetEventUdsStatus_GetEventUdsStatus_EvtInfo_AutoCreatedDemEvent_ESH_Action_SwitchRun_BswMReportFailToDemRef: start-on-event=DemSatellite_OsApplication_Untrusted_Core0InternalBehavior/GetEventUdsStatus, operation=EvtInfo_AutoCreatedDemEvent_ESH_Action_SwitchRun_BswMReportFailToDemRef.GetEventUdsStatus
        OpEventGetEventUdsStatus_GetEventUdsStatus_EvtInfo_AutoCreatedDemEvent_ESH_Action_SwitchRun_BswMReportFailToDemRef_1: start-on-event=DemSatellite_OsApplication_Untrusted_Core0InternalBehavior/GetEventUdsStatus, operation=EvtInfo_AutoCreatedDemEvent_ESH_Action_SwitchRun_BswMReportFailToDemRef_1.GetEventUdsStatus
        OpEventGetEventUdsStatus_GetEventUdsStatus_EvtInfo_AutoCreatedDemEvent_ESH_Action_SwitchShutdown_BswMReportFailToDemRef: start-on-event=DemSatellite_OsApplication_Untrusted_Core0InternalBehavior/GetEventUdsStatus, operation=EvtInfo_AutoCreatedDemEvent_ESH_Action_SwitchShutdown_BswMReportFailToDemRef.GetEventUdsStatus
        OpEventGetEventUdsStatus_GetEventUdsStatus_EvtInfo_AutoCreatedDemEvent_ESH_Action_SwitchShutdown_BswMReportFailToDemRef_1: start-on-event=DemSatellite_OsApplication_Untrusted_Core0InternalBehavior/GetEventUdsStatus, operation=EvtInfo_AutoCreatedDemEvent_ESH_Action_SwitchShutdown_BswMReportFailToDemRef_1.GetEventUdsStatus
        OpEventGetEventUdsStatus_GetEventUdsStatus_EvtInfo_AutoCreatedDemEvent_ESH_Action_SwitchWakeup_BswMReportFailToDemRef: start-on-event=DemSatellite_OsApplication_Untrusted_Core0InternalBehavior/GetEventUdsStatus, operation=EvtInfo_AutoCreatedDemEvent_ESH_Action_SwitchWakeup_BswMReportFailToDemRef.GetEventUdsStatus
        OpEventGetEventUdsStatus_GetEventUdsStatus_EvtInfo_AutoCreatedDemEvent_ESH_Action_SwitchWakeup_BswMReportFailToDemRef_1: start-on-event=DemSatellite_OsApplication_Untrusted_Core0InternalBehavior/GetEventUdsStatus, operation=EvtInfo_AutoCreatedDemEvent_ESH_Action_SwitchWakeup_BswMReportFailToDemRef_1.GetEventUdsStatus
        OpEventGetEventUdsStatus_GetEventUdsStatus_EvtInfo_AutoCreatedDemEvent_ESH_Action_WriteAllTimer_Start_BswMReportFailToDemRef: start-on-event=DemSatellite_OsApplication_Untrusted_Core0InternalBehavior/GetEventUdsStatus, operation=EvtInfo_AutoCreatedDemEvent_ESH_Action_WriteAllTimer_Start_BswMReportFailToDemRef.GetEventUdsStatus
        OpEventGetEventUdsStatus_GetEventUdsStatus_EvtInfo_AutoCreatedDemEvent_ESH_Action_WriteAllTimer_Stop_BswMReportFailToDemRef: start-on-event=DemSatellite_OsApplication_Untrusted_Core0InternalBehavior/GetEventUdsStatus, operation=EvtInfo_AutoCreatedDemEvent_ESH_Action_WriteAllTimer_Stop_BswMReportFailToDemRef.GetEventUdsStatus
        OpEventGetEventUdsStatus_GetEventUdsStatus_EvtInfo_AutoCreatedDemEvent_ESH_Action_WriteAllTimer_Stop_BswMReportFailToDemRef_1: start-on-event=DemSatellite_OsApplication_Untrusted_Core0InternalBehavior/GetEventUdsStatus, operation=EvtInfo_AutoCreatedDemEvent_ESH_Action_WriteAllTimer_Stop_BswMReportFailToDemRef_1.GetEventUdsStatus
        OpEventGetEventUdsStatus_GetEventUdsStatus_EvtInfo_AutoCreatedDemEvent_ESH_DemInit_BswMReportFailToDemRef: start-on-event=DemSatellite_OsApplication_Untrusted_Core0InternalBehavior/GetEventUdsStatus, operation=EvtInfo_AutoCreatedDemEvent_ESH_DemInit_BswMReportFailToDemRef.GetEventUdsStatus
        OpEventGetEventUdsStatus_GetEventUdsStatus_EvtInfo_AutoCreatedDemEvent_ESH_PostRunNested_BswMReportFailToDemRef: start-on-event=DemSatellite_OsApplication_Untrusted_Core0InternalBehavior/GetEventUdsStatus, operation=EvtInfo_AutoCreatedDemEvent_ESH_PostRunNested_BswMReportFailToDemRef.GetEventUdsStatus
        OpEventGetEventUdsStatus_GetEventUdsStatus_EvtInfo_AutoCreatedDemEvent_ESH_PostRunToPrepNested_BswMReportFailToDemRef: start-on-event=DemSatellite_OsApplication_Untrusted_Core0InternalBehavior/GetEventUdsStatus, operation=EvtInfo_AutoCreatedDemEvent_ESH_PostRunToPrepNested_BswMReportFailToDemRef.GetEventUdsStatus
        OpEventGetEventUdsStatus_GetEventUdsStatus_EvtInfo_AutoCreatedDemEvent_ESH_Action_ExitExclusiveArea_BswMReportFailToDemRef_1: start-on-event=DemSatellite_OsApplication_Untrusted_Core0InternalBehavior/GetEventUdsStatus, operation=EvtInfo_AutoCreatedDemEvent_ESH_Action_ExitExclusiveArea_BswMReportFailToDemRef_1.GetEventUdsStatus
        OpEventGetEventUdsStatus_GetEventUdsStatus_EvtInfo_AutoCreatedDemEvent_INIT_Action_BrsHw_EnableHwAccess_BswMReportFailToDemRef: start-on-event=DemSatellite_OsApplication_Untrusted_Core0InternalBehavior/GetEventUdsStatus, operation=EvtInfo_AutoCreatedDemEvent_INIT_Action_BrsHw_EnableHwAccess_BswMReportFailToDemRef.GetEventUdsStatus
        OpEventGetEventUdsStatus_GetEventUdsStatus_EvtInfo_AutoCreatedDemEvent_INIT_Action_CanIf_Init_BswMReportFailToDemRef: start-on-event=DemSatellite_OsApplication_Untrusted_Core0InternalBehavior/GetEventUdsStatus, operation=EvtInfo_AutoCreatedDemEvent_INIT_Action_CanIf_Init_BswMReportFailToDemRef.GetEventUdsStatus
        OpEventGetEventUdsStatus_GetEventUdsStatus_EvtInfo_AutoCreatedDemEvent_INIT_Action_CanNm_Init_BswMReportFailToDemRef: start-on-event=DemSatellite_OsApplication_Untrusted_Core0InternalBehavior/GetEventUdsStatus, operation=EvtInfo_AutoCreatedDemEvent_INIT_Action_CanNm_Init_BswMReportFailToDemRef.GetEventUdsStatus
        OpEventGetEventUdsStatus_GetEventUdsStatus_EvtInfo_AutoCreatedDemEvent_INIT_Action_CanSM_Init_BswMReportFailToDemRef: start-on-event=DemSatellite_OsApplication_Untrusted_Core0InternalBehavior/GetEventUdsStatus, operation=EvtInfo_AutoCreatedDemEvent_INIT_Action_CanSM_Init_BswMReportFailToDemRef.GetEventUdsStatus
        OpEventGetEventUdsStatus_GetEventUdsStatus_EvtInfo_AutoCreatedDemEvent_INIT_Action_CanTp_Init_BswMReportFailToDemRef: start-on-event=DemSatellite_OsApplication_Untrusted_Core0InternalBehavior/GetEventUdsStatus, operation=EvtInfo_AutoCreatedDemEvent_INIT_Action_CanTp_Init_BswMReportFailToDemRef.GetEventUdsStatus
        OpEventGetEventUdsStatus_GetEventUdsStatus_EvtInfo_AutoCreatedDemEvent_INIT_Action_Can_Init_BswMReportFailToDemRef: start-on-event=DemSatellite_OsApplication_Untrusted_Core0InternalBehavior/GetEventUdsStatus, operation=EvtInfo_AutoCreatedDemEvent_INIT_Action_Can_Init_BswMReportFailToDemRef.GetEventUdsStatus
        OpEventGetEventUdsStatus_GetEventUdsStatus_EvtInfo_AutoCreatedDemEvent_INIT_Action_ComM_Init_BswMReportFailToDemRef: start-on-event=DemSatellite_OsApplication_Untrusted_Core0InternalBehavior/GetEventUdsStatus, operation=EvtInfo_AutoCreatedDemEvent_INIT_Action_ComM_Init_BswMReportFailToDemRef.GetEventUdsStatus
        OpEventGetEventUdsStatus_GetEventUdsStatus_EvtInfo_AutoCreatedDemEvent_INIT_Action_Com_Init_BswMReportFailToDemRef: start-on-event=DemSatellite_OsApplication_Untrusted_Core0InternalBehavior/GetEventUdsStatus, operation=EvtInfo_AutoCreatedDemEvent_INIT_Action_Com_Init_BswMReportFailToDemRef.GetEventUdsStatus
        OpEventGetEventUdsStatus_GetEventUdsStatus_EvtInfo_AutoCreatedDemEvent_INIT_Action_Dcm_Init_BswMReportFailToDemRef: start-on-event=DemSatellite_OsApplication_Untrusted_Core0InternalBehavior/GetEventUdsStatus, operation=EvtInfo_AutoCreatedDemEvent_INIT_Action_Dcm_Init_BswMReportFailToDemRef.GetEventUdsStatus
        OpEventGetEventUdsStatus_GetEventUdsStatus_EvtInfo_AutoCreatedDemEvent_INIT_Action_Dem_Init_BswMReportFailToDemRef: start-on-event=DemSatellite_OsApplication_Untrusted_Core0InternalBehavior/GetEventUdsStatus, operation=EvtInfo_AutoCreatedDemEvent_INIT_Action_Dem_Init_BswMReportFailToDemRef.GetEventUdsStatus
        OpEventGetEventUdsStatus_GetEventUdsStatus_EvtInfo_AutoCreatedDemEvent_INIT_Action_EnableInterrupts_BswMReportFailToDemRef: start-on-event=DemSatellite_OsApplication_Untrusted_Core0InternalBehavior/GetEventUdsStatus, operation=EvtInfo_AutoCreatedDemEvent_INIT_Action_EnableInterrupts_BswMReportFailToDemRef.GetEventUdsStatus
        OpEventGetEventUdsStatus_GetEventUdsStatus_EvtInfo_AutoCreatedDemEvent_INIT_Action_Fee_Init_BswMReportFailToDemRef: start-on-event=DemSatellite_OsApplication_Untrusted_Core0InternalBehavior/GetEventUdsStatus, operation=EvtInfo_AutoCreatedDemEvent_INIT_Action_Fee_Init_BswMReportFailToDemRef.GetEventUdsStatus
        OpEventGetEventUdsStatus_GetEventUdsStatus_EvtInfo_AutoCreatedDemEvent_INIT_Action_Issm_Init_BswMReportFailToDemRef: start-on-event=DemSatellite_OsApplication_Untrusted_Core0InternalBehavior/GetEventUdsStatus, operation=EvtInfo_AutoCreatedDemEvent_INIT_Action_Issm_Init_BswMReportFailToDemRef.GetEventUdsStatus
        OpEventGetEventUdsStatus_GetEventUdsStatus_EvtInfo_AutoCreatedDemEvent_INIT_Action_J1939Nm_Init_BswMReportFailToDemRef: start-on-event=DemSatellite_OsApplication_Untrusted_Core0InternalBehavior/GetEventUdsStatus, operation=EvtInfo_AutoCreatedDemEvent_INIT_Action_J1939Nm_Init_BswMReportFailToDemRef.GetEventUdsStatus
        OpEventGetEventUdsStatus_GetEventUdsStatus_EvtInfo_AutoCreatedDemEvent_INIT_Action_J1939Rm_Init_BswMReportFailToDemRef: start-on-event=DemSatellite_OsApplication_Untrusted_Core0InternalBehavior/GetEventUdsStatus, operation=EvtInfo_AutoCreatedDemEvent_INIT_Action_J1939Rm_Init_BswMReportFailToDemRef.GetEventUdsStatus
        OpEventGetEventUdsStatus_GetEventUdsStatus_EvtInfo_AutoCreatedDemEvent_INIT_Action_J1939Tp_Init_BswMReportFailToDemRef: start-on-event=DemSatellite_OsApplication_Untrusted_Core0InternalBehavior/GetEventUdsStatus, operation=EvtInfo_AutoCreatedDemEvent_INIT_Action_J1939Tp_Init_BswMReportFailToDemRef.GetEventUdsStatus
        OpEventGetEventUdsStatus_GetEventUdsStatus_EvtInfo_AutoCreatedDemEvent_INIT_Action_LinIf_Init_BswMReportFailToDemRef: start-on-event=DemSatellite_OsApplication_Untrusted_Core0InternalBehavior/GetEventUdsStatus, operation=EvtInfo_AutoCreatedDemEvent_INIT_Action_LinIf_Init_BswMReportFailToDemRef.GetEventUdsStatus
        OpEventGetEventUdsStatus_GetEventUdsStatus_EvtInfo_AutoCreatedDemEvent_INIT_Action_LinSM_Init_BswMReportFailToDemRef: start-on-event=DemSatellite_OsApplication_Untrusted_Core0InternalBehavior/GetEventUdsStatus, operation=EvtInfo_AutoCreatedDemEvent_INIT_Action_LinSM_Init_BswMReportFailToDemRef.GetEventUdsStatus
        OpEventGetEventUdsStatus_GetEventUdsStatus_EvtInfo_AutoCreatedDemEvent_INIT_Action_LinTp_Init_BswMReportFailToDemRef: start-on-event=DemSatellite_OsApplication_Untrusted_Core0InternalBehavior/GetEventUdsStatus, operation=EvtInfo_AutoCreatedDemEvent_INIT_Action_LinTp_Init_BswMReportFailToDemRef.GetEventUdsStatus
        OpEventGetEventUdsStatus_GetEventUdsStatus_EvtInfo_AutoCreatedDemEvent_INIT_Action_Lin_Init_BswMReportFailToDemRef: start-on-event=DemSatellite_OsApplication_Untrusted_Core0InternalBehavior/GetEventUdsStatus, operation=EvtInfo_AutoCreatedDemEvent_INIT_Action_Lin_Init_BswMReportFailToDemRef.GetEventUdsStatus
        OpEventGetEventUdsStatus_GetEventUdsStatus_EvtInfo_AutoCreatedDemEvent_INIT_Action_Nm_Init_BswMReportFailToDemRef: start-on-event=DemSatellite_OsApplication_Untrusted_Core0InternalBehavior/GetEventUdsStatus, operation=EvtInfo_AutoCreatedDemEvent_INIT_Action_Nm_Init_BswMReportFailToDemRef.GetEventUdsStatus
        OpEventGetEventUdsStatus_GetEventUdsStatus_EvtInfo_AutoCreatedDemEvent_INIT_Action_NvMReadAll_BswMReportFailToDemRef: start-on-event=DemSatellite_OsApplication_Untrusted_Core0InternalBehavior/GetEventUdsStatus, operation=EvtInfo_AutoCreatedDemEvent_INIT_Action_NvMReadAll_BswMReportFailToDemRef.GetEventUdsStatus
        OpEventGetEventUdsStatus_GetEventUdsStatus_EvtInfo_AutoCreatedDemEvent_INIT_Action_NvM_Init_BswMReportFailToDemRef: start-on-event=DemSatellite_OsApplication_Untrusted_Core0InternalBehavior/GetEventUdsStatus, operation=EvtInfo_AutoCreatedDemEvent_INIT_Action_NvM_Init_BswMReportFailToDemRef.GetEventUdsStatus
        OpEventGetEventUdsStatus_GetEventUdsStatus_EvtInfo_AutoCreatedDemEvent_INIT_Action_PduR_Init_BswMReportFailToDemRef: start-on-event=DemSatellite_OsApplication_Untrusted_Core0InternalBehavior/GetEventUdsStatus, operation=EvtInfo_AutoCreatedDemEvent_INIT_Action_PduR_Init_BswMReportFailToDemRef.GetEventUdsStatus
        OpEventGetEventUdsStatus_GetEventUdsStatus_EvtInfo_AutoCreatedDemEvent_INIT_Action_RteStart_BswMReportFailToDemRef: start-on-event=DemSatellite_OsApplication_Untrusted_Core0InternalBehavior/GetEventUdsStatus, operation=EvtInfo_AutoCreatedDemEvent_INIT_Action_RteStart_BswMReportFailToDemRef.GetEventUdsStatus
        OpEventGetEventUdsStatus_GetEventUdsStatus_EvtInfo_AutoCreatedDemEvent_CHNL_17344684_CANSM_E_MODE_REQUEST_TIMEOUT: start-on-event=DemSatellite_OsApplication_Untrusted_Core0InternalBehavior/GetEventUdsStatus, operation=EvtInfo_AutoCreatedDemEvent_CHNL_17344684_CANSM_E_MODE_REQUEST_TIMEOUT.GetEventUdsStatus
        OpEventGetEventUdsStatus_GetEventUdsStatus_EvtInfo_AutoCreatedDemEvent_CHNL_17344684_CANSM_E_BUS_OFF: start-on-event=DemSatellite_OsApplication_Untrusted_Core0InternalBehavior/GetEventUdsStatus, operation=EvtInfo_AutoCreatedDemEvent_CHNL_17344684_CANSM_E_BUS_OFF.GetEventUdsStatus
        OpEventGetEventUdsStatus_GetEventUdsStatus_EvtInfo_AutoCreatedDemEvent_CHNL_53cce282_CANSM_E_MODE_REQUEST_TIMEOUT: start-on-event=DemSatellite_OsApplication_Untrusted_Core0InternalBehavior/GetEventUdsStatus, operation=EvtInfo_AutoCreatedDemEvent_CHNL_53cce282_CANSM_E_MODE_REQUEST_TIMEOUT.GetEventUdsStatus
        OpEventGetEventUdsStatus_GetEventUdsStatus_EvtInfo_AutoCreatedDemEvent_CHNL_53cce282_CANSM_E_BUS_OFF: start-on-event=DemSatellite_OsApplication_Untrusted_Core0InternalBehavior/GetEventUdsStatus, operation=EvtInfo_AutoCreatedDemEvent_CHNL_53cce282_CANSM_E_BUS_OFF.GetEventUdsStatus
        OpEventGetEventUdsStatus_GetEventUdsStatus_EvtInfo_AutoCreatedDemEvent_CHNL_a6b6a922_CANSM_E_MODE_REQUEST_TIMEOUT: start-on-event=DemSatellite_OsApplication_Untrusted_Core0InternalBehavior/GetEventUdsStatus, operation=EvtInfo_AutoCreatedDemEvent_CHNL_a6b6a922_CANSM_E_MODE_REQUEST_TIMEOUT.GetEventUdsStatus
        OpEventGetEventUdsStatus_GetEventUdsStatus_EvtInfo_AutoCreatedDemEvent_CHNL_a6b6a922_CANSM_E_BUS_OFF: start-on-event=DemSatellite_OsApplication_Untrusted_Core0InternalBehavior/GetEventUdsStatus, operation=EvtInfo_AutoCreatedDemEvent_CHNL_a6b6a922_CANSM_E_BUS_OFF.GetEventUdsStatus
        OpEventGetEventUdsStatus_GetEventUdsStatus_EvtInfo_AutoCreatedDemEvent_CHNL_df893ad5_CANSM_E_MODE_REQUEST_TIMEOUT: start-on-event=DemSatellite_OsApplication_Untrusted_Core0InternalBehavior/GetEventUdsStatus, operation=EvtInfo_AutoCreatedDemEvent_CHNL_df893ad5_CANSM_E_MODE_REQUEST_TIMEOUT.GetEventUdsStatus
        OpEventGetEventUdsStatus_GetEventUdsStatus_EvtInfo_AutoCreatedDemEvent_CHNL_df893ad5_CANSM_E_BUS_OFF: start-on-event=DemSatellite_OsApplication_Untrusted_Core0InternalBehavior/GetEventUdsStatus, operation=EvtInfo_AutoCreatedDemEvent_CHNL_df893ad5_CANSM_E_BUS_OFF.GetEventUdsStatus
        OpEventGetEventUdsStatus_GetEventUdsStatus_EvtInfo_AutoCreatedDemEvent_CHNL_e058b4ae_CANSM_E_MODE_REQUEST_TIMEOUT: start-on-event=DemSatellite_OsApplication_Untrusted_Core0InternalBehavior/GetEventUdsStatus, operation=EvtInfo_AutoCreatedDemEvent_CHNL_e058b4ae_CANSM_E_MODE_REQUEST_TIMEOUT.GetEventUdsStatus
        OpEventGetEventUdsStatus_GetEventUdsStatus_EvtInfo_AutoCreatedDemEvent_CHNL_e058b4ae_CANSM_E_BUS_OFF: start-on-event=DemSatellite_OsApplication_Untrusted_Core0InternalBehavior/GetEventUdsStatus, operation=EvtInfo_AutoCreatedDemEvent_CHNL_e058b4ae_CANSM_E_BUS_OFF.GetEventUdsStatus
        OpEventGetEventUdsStatus_GetEventUdsStatus_EvtInfo_AutoCreatedDemEvent_ECUM_E_RAM_CHECK_FAILED: start-on-event=DemSatellite_OsApplication_Untrusted_Core0InternalBehavior/GetEventUdsStatus, operation=EvtInfo_AutoCreatedDemEvent_ECUM_E_RAM_CHECK_FAILED.GetEventUdsStatus
        OpEventGetEventUdsStatus_GetEventUdsStatus_EvtInfo_AutoCreatedDemEvent_ECUM_E_IMPROPER_CALLER: start-on-event=DemSatellite_OsApplication_Untrusted_Core0InternalBehavior/GetEventUdsStatus, operation=EvtInfo_AutoCreatedDemEvent_ECUM_E_IMPROPER_CALLER.GetEventUdsStatus
        OpEventGetEventUdsStatus_GetEventUdsStatus_EvtInfo_AutoCreatedDemEvent_ECUM_E_CONFIGURATION_DATA_INCONSISTENT: start-on-event=DemSatellite_OsApplication_Untrusted_Core0InternalBehavior/GetEventUdsStatus, operation=EvtInfo_AutoCreatedDemEvent_ECUM_E_CONFIGURATION_DATA_INCONSISTENT.GetEventUdsStatus
        OpEventGetEventUdsStatus_GetEventUdsStatus_EvtInfo_AutoCreatedDemEvent_ECUM_E_ALL_RUN_REQUESTS_KILLED: start-on-event=DemSatellite_OsApplication_Untrusted_Core0InternalBehavior/GetEventUdsStatus, operation=EvtInfo_AutoCreatedDemEvent_ECUM_E_ALL_RUN_REQUESTS_KILLED.GetEventUdsStatus
        OpEventGetEventUdsStatus_GetEventUdsStatus_EvtInfo_AutoCreatedDemEvent_FLS_E_WRITE_FAILED: start-on-event=DemSatellite_OsApplication_Untrusted_Core0InternalBehavior/GetEventUdsStatus, operation=EvtInfo_AutoCreatedDemEvent_FLS_E_WRITE_FAILED.GetEventUdsStatus
        OpEventGetEventUdsStatus_GetEventUdsStatus_EvtInfo_AutoCreatedDemEvent_FLS_E_UNEXPECTED_FLASH_ID: start-on-event=DemSatellite_OsApplication_Untrusted_Core0InternalBehavior/GetEventUdsStatus, operation=EvtInfo_AutoCreatedDemEvent_FLS_E_UNEXPECTED_FLASH_ID.GetEventUdsStatus
        OpEventGetEventUdsStatus_GetEventUdsStatus_EvtInfo_AutoCreatedDemEvent_FLS_E_READ_FAILED: start-on-event=DemSatellite_OsApplication_Untrusted_Core0InternalBehavior/GetEventUdsStatus, operation=EvtInfo_AutoCreatedDemEvent_FLS_E_READ_FAILED.GetEventUdsStatus
        OpEventGetEventUdsStatus_GetEventUdsStatus_EvtInfo_AutoCreatedDemEvent_FLS_E_ERASE_FAILED: start-on-event=DemSatellite_OsApplication_Untrusted_Core0InternalBehavior/GetEventUdsStatus, operation=EvtInfo_AutoCreatedDemEvent_FLS_E_ERASE_FAILED.GetEventUdsStatus
        OpEventGetEventUdsStatus_GetEventUdsStatus_EvtInfo_AutoCreatedDemEvent_FLS_E_COMPARE_FAILED: start-on-event=DemSatellite_OsApplication_Untrusted_Core0InternalBehavior/GetEventUdsStatus, operation=EvtInfo_AutoCreatedDemEvent_FLS_E_COMPARE_FAILED.GetEventUdsStatus
        OpEventGetEventUdsStatus_GetEventUdsStatus_EvtInfo_AutoCreatedDemEvent_GPT_E_TIMEOUT: start-on-event=DemSatellite_OsApplication_Untrusted_Core0InternalBehavior/GetEventUdsStatus, operation=EvtInfo_AutoCreatedDemEvent_GPT_E_TIMEOUT.GetEventUdsStatus
        OpEventGetEventUdsStatus_GetEventUdsStatus_EvtInfo_AutoCreatedDemEvent_J1939NM_E_ADDRESS_LOST: start-on-event=DemSatellite_OsApplication_Untrusted_Core0InternalBehavior/GetEventUdsStatus, operation=EvtInfo_AutoCreatedDemEvent_J1939NM_E_ADDRESS_LOST.GetEventUdsStatus
        OpEventGetEventUdsStatus_GetEventUdsStatus_EvtInfo_AutoCreatedDemEvent_J1939TpConfiguration_J1939TP_E_COMMUNICATION: start-on-event=DemSatellite_OsApplication_Untrusted_Core0InternalBehavior/GetEventUdsStatus, operation=EvtInfo_AutoCreatedDemEvent_J1939TpConfiguration_J1939TP_E_COMMUNICATION.GetEventUdsStatus
        OpEventGetEventUdsStatus_GetEventUdsStatus_EvtInfo_AutoCreatedDemEvent_LIN_E_TIMEOUT: start-on-event=DemSatellite_OsApplication_Untrusted_Core0InternalBehavior/GetEventUdsStatus, operation=EvtInfo_AutoCreatedDemEvent_LIN_E_TIMEOUT.GetEventUdsStatus
        OpEventGetEventUdsStatus_GetEventUdsStatus_EvtInfo_AutoCreatedDemEvent_MCL_E_DMA_UNRECOGNIZED: start-on-event=DemSatellite_OsApplication_Untrusted_Core0InternalBehavior/GetEventUdsStatus, operation=EvtInfo_AutoCreatedDemEvent_MCL_E_DMA_UNRECOGNIZED.GetEventUdsStatus
        OpEventGetEventUdsStatus_GetEventUdsStatus_EvtInfo_AutoCreatedDemEvent_MCL_E_DMA_PRIORITY: start-on-event=DemSatellite_OsApplication_Untrusted_Core0InternalBehavior/GetEventUdsStatus, operation=EvtInfo_AutoCreatedDemEvent_MCL_E_DMA_PRIORITY.GetEventUdsStatus
        OpEventGetEventUdsStatus_GetEventUdsStatus_EvtInfo_AutoCreatedDemEvent_MCL_E_DMA_INCONSISTENCY: start-on-event=DemSatellite_OsApplication_Untrusted_Core0InternalBehavior/GetEventUdsStatus, operation=EvtInfo_AutoCreatedDemEvent_MCL_E_DMA_INCONSISTENCY.GetEventUdsStatus
        OpEventGetEventUdsStatus_GetEventUdsStatus_EvtInfo_AutoCreatedDemEvent_MCL_E_DMA_ECC: start-on-event=DemSatellite_OsApplication_Untrusted_Core0InternalBehavior/GetEventUdsStatus, operation=EvtInfo_AutoCreatedDemEvent_MCL_E_DMA_ECC.GetEventUdsStatus
        OpEventGetEventUdsStatus_GetEventUdsStatus_EvtInfo_AutoCreatedDemEvent_MCL_E_DMA_DESCRIPTOR: start-on-event=DemSatellite_OsApplication_Untrusted_Core0InternalBehavior/GetEventUdsStatus, operation=EvtInfo_AutoCreatedDemEvent_MCL_E_DMA_DESCRIPTOR.GetEventUdsStatus
        OpEventGetEventUdsStatus_GetEventUdsStatus_EvtInfo_AutoCreatedDemEvent_MCL_E_DMA_BUS: start-on-event=DemSatellite_OsApplication_Untrusted_Core0InternalBehavior/GetEventUdsStatus, operation=EvtInfo_AutoCreatedDemEvent_MCL_E_DMA_BUS.GetEventUdsStatus
        OpEventGetEventUdsStatus_GetEventUdsStatus_EvtInfo_AutoCreatedDemEvent_MCU_E_TIMEOUT_FAILURE: start-on-event=DemSatellite_OsApplication_Untrusted_Core0InternalBehavior/GetEventUdsStatus, operation=EvtInfo_AutoCreatedDemEvent_MCU_E_TIMEOUT_FAILURE.GetEventUdsStatus
        OpEventGetEventUdsStatus_GetEventUdsStatus_EvtInfo_AutoCreatedDemEvent_MCU_E_SSCM_CER_FAILURE: start-on-event=DemSatellite_OsApplication_Untrusted_Core0InternalBehavior/GetEventUdsStatus, operation=EvtInfo_AutoCreatedDemEvent_MCU_E_SSCM_CER_FAILURE.GetEventUdsStatus
        OpEventGetEventUdsStatus_GetEventUdsStatus_EvtInfo_AutoCreatedDemEvent_MCU_E_INVALIDMODE_CONFIG: start-on-event=DemSatellite_OsApplication_Untrusted_Core0InternalBehavior/GetEventUdsStatus, operation=EvtInfo_AutoCreatedDemEvent_MCU_E_INVALIDMODE_CONFIG.GetEventUdsStatus
        OpEventGetEventUdsStatus_GetEventUdsStatus_EvtInfo_AutoCreatedDemEvent_MCU_E_CLOCK_FAILURE: start-on-event=DemSatellite_OsApplication_Untrusted_Core0InternalBehavior/GetEventUdsStatus, operation=EvtInfo_AutoCreatedDemEvent_MCU_E_CLOCK_FAILURE.GetEventUdsStatus
        OpEventGetEventUdsStatus_GetEventUdsStatus_EvtInfo_AutoCreatedDemEvent_NVM_E_WRONG_BLOCK_ID: start-on-event=DemSatellite_OsApplication_Untrusted_Core0InternalBehavior/GetEventUdsStatus, operation=EvtInfo_AutoCreatedDemEvent_NVM_E_WRONG_BLOCK_ID.GetEventUdsStatus
        OpEventGetEventUdsStatus_GetEventUdsStatus_EvtInfo_AutoCreatedDemEvent_NVM_E_WRITE_PROTECTED: start-on-event=DemSatellite_OsApplication_Untrusted_Core0InternalBehavior/GetEventUdsStatus, operation=EvtInfo_AutoCreatedDemEvent_NVM_E_WRITE_PROTECTED.GetEventUdsStatus
        OpEventGetEventUdsStatus_GetEventUdsStatus_EvtInfo_AutoCreatedDemEvent_NVM_E_VERIFY_FAILED: start-on-event=DemSatellite_OsApplication_Untrusted_Core0InternalBehavior/GetEventUdsStatus, operation=EvtInfo_AutoCreatedDemEvent_NVM_E_VERIFY_FAILED.GetEventUdsStatus
        OpEventGetEventUdsStatus_GetEventUdsStatus_EvtInfo_AutoCreatedDemEvent_NVM_E_REQ_FAILED: start-on-event=DemSatellite_OsApplication_Untrusted_Core0InternalBehavior/GetEventUdsStatus, operation=EvtInfo_AutoCreatedDemEvent_NVM_E_REQ_FAILED.GetEventUdsStatus
        OpEventGetEventUdsStatus_GetEventUdsStatus_EvtInfo_AutoCreatedDemEvent_NVM_E_QUEUE_OVERFLOW: start-on-event=DemSatellite_OsApplication_Untrusted_Core0InternalBehavior/GetEventUdsStatus, operation=EvtInfo_AutoCreatedDemEvent_NVM_E_QUEUE_OVERFLOW.GetEventUdsStatus
        OpEventGetEventUdsStatus_GetEventUdsStatus_EvtInfo_AutoCreatedDemEvent_NVM_E_LOSS_OF_REDUNDANCY: start-on-event=DemSatellite_OsApplication_Untrusted_Core0InternalBehavior/GetEventUdsStatus, operation=EvtInfo_AutoCreatedDemEvent_NVM_E_LOSS_OF_REDUNDANCY.GetEventUdsStatus
        OpEventGetEventUdsStatus_GetEventUdsStatus_EvtInfo_AutoCreatedDemEvent_NVM_E_INTEGRITY_FAILED: start-on-event=DemSatellite_OsApplication_Untrusted_Core0InternalBehavior/GetEventUdsStatus, operation=EvtInfo_AutoCreatedDemEvent_NVM_E_INTEGRITY_FAILED.GetEventUdsStatus
        OpEventGetEventUdsStatus_GetEventUdsStatus_EvtInfo_AutoCreatedDemEvent_SPI_E_HARDWARE_ERROR: start-on-event=DemSatellite_OsApplication_Untrusted_Core0InternalBehavior/GetEventUdsStatus, operation=EvtInfo_AutoCreatedDemEvent_SPI_E_HARDWARE_ERROR.GetEventUdsStatus
        OpEventGetEventUdsStatus_GetEventUdsStatus_EvtInfo_AutoCreatedDemEvent_SpiDriver_SPI_E_HARDWARE_ERROR: start-on-event=DemSatellite_OsApplication_Untrusted_Core0InternalBehavior/GetEventUdsStatus, operation=EvtInfo_AutoCreatedDemEvent_SpiDriver_SPI_E_HARDWARE_ERROR.GetEventUdsStatus
        OpEventGetEventUdsStatus_GetEventUdsStatus_EvtInfo_AutoCreatedDemEvent_WDG_E_UNLOCKED: start-on-event=DemSatellite_OsApplication_Untrusted_Core0InternalBehavior/GetEventUdsStatus, operation=EvtInfo_AutoCreatedDemEvent_WDG_E_UNLOCKED.GetEventUdsStatus
        OpEventGetEventUdsStatus_GetEventUdsStatus_EvtInfo_AutoCreatedDemEvent_WDG_E_MODE_FAILED: start-on-event=DemSatellite_OsApplication_Untrusted_Core0InternalBehavior/GetEventUdsStatus, operation=EvtInfo_AutoCreatedDemEvent_WDG_E_MODE_FAILED.GetEventUdsStatus
        OpEventGetEventUdsStatus_GetEventUdsStatus_EvtInfo_AutoCreatedDemEvent_WDG_E_INVALID_PARAMETER: start-on-event=DemSatellite_OsApplication_Untrusted_Core0InternalBehavior/GetEventUdsStatus, operation=EvtInfo_AutoCreatedDemEvent_WDG_E_INVALID_PARAMETER.GetEventUdsStatus
        OpEventGetEventUdsStatus_GetEventUdsStatus_EvtInfo_AutoCreatedDemEvent_WDG_E_INVALID_CALL: start-on-event=DemSatellite_OsApplication_Untrusted_Core0InternalBehavior/GetEventUdsStatus, operation=EvtInfo_AutoCreatedDemEvent_WDG_E_INVALID_CALL.GetEventUdsStatus
        OpEventGetEventUdsStatus_GetEventUdsStatus_EvtInfo_AutoCreatedDemEvent_WDG_E_FORBIDDEN_INVOCATION: start-on-event=DemSatellite_OsApplication_Untrusted_Core0InternalBehavior/GetEventUdsStatus, operation=EvtInfo_AutoCreatedDemEvent_WDG_E_FORBIDDEN_INVOCATION.GetEventUdsStatus
        OpEventGetEventUdsStatus_GetEventUdsStatus_EvtInfo_AutoCreatedDemEvent_WDG_E_DISABLE_REJECTED: start-on-event=DemSatellite_OsApplication_Untrusted_Core0InternalBehavior/GetEventUdsStatus, operation=EvtInfo_AutoCreatedDemEvent_WDG_E_DISABLE_REJECTED.GetEventUdsStatus
        OpEventGetEventUdsStatus_GetEventUdsStatus_EvtInfo_AutoCreatedDemEvent_WDG_E_CORRUPT_CONFIG: start-on-event=DemSatellite_OsApplication_Untrusted_Core0InternalBehavior/GetEventUdsStatus, operation=EvtInfo_AutoCreatedDemEvent_WDG_E_CORRUPT_CONFIG.GetEventUdsStatus
        OpEventGetEventStatus_GetEventStatus_EvtInfo_AutoCreatedDemEvent_ADC_E_TIMEOUT: start-on-event=DemSatellite_OsApplication_Untrusted_Core0InternalBehavior/GetEventStatus, operation=EvtInfo_AutoCreatedDemEvent_ADC_E_TIMEOUT.GetEventStatus
        OpEventGetEventStatus_GetEventStatus_EvtInfo_AutoCreatedDemEvent_CC_DisableDM_CIOM_oCabSubnet_Rx_063a5fbc_BswMReportFailToDemRef: start-on-event=DemSatellite_OsApplication_Untrusted_Core0InternalBehavior/GetEventStatus, operation=EvtInfo_AutoCreatedDemEvent_CC_DisableDM_CIOM_oCabSubnet_Rx_063a5fbc_BswMReportFailToDemRef.GetEventStatus
        OpEventGetEventStatus_GetEventStatus_EvtInfo_AutoCreatedDemEvent_CC_J1939RmStateSwitch_CN_Backbone1J1939_0b1f4bae_CIOM_63cf1333: start-on-event=DemSatellite_OsApplication_Untrusted_Core0InternalBehavior/GetEventStatus, operation=EvtInfo_AutoCreatedDemEvent_CC_J1939RmStateSwitch_CN_Backbone1J1939_0b1f4bae_CIOM_4d5cd289_J1939RM_STATE_OFFLINE_BswMRe_5a5b15b8.GetEventStatus
        OpEventGetEventStatus_GetEventStatus_EvtInfo_AutoCreatedDemEvent_CC_J1939RmStateSwitch_CN_Backbone1J1939_0b1f4bae_CIOM_1e9023a0: start-on-event=DemSatellite_OsApplication_Untrusted_Core0InternalBehavior/GetEventStatus, operation=EvtInfo_AutoCreatedDemEvent_CC_J1939RmStateSwitch_CN_Backbone1J1939_0b1f4bae_CIOM_4d5cd289_J1939RM_STATE_ONLINE_BswMRep_ec959aed.GetEventStatus
        OpEventGetEventStatus_GetEventStatus_EvtInfo_AutoCreatedDemEvent_CC_DisablePDUGroup_CIOM_oLIN04_Tx_04202f7b_BswMReportF_6cd4c0be: start-on-event=DemSatellite_OsApplication_Untrusted_Core0InternalBehavior/GetEventStatus, operation=EvtInfo_AutoCreatedDemEvent_CC_DisablePDUGroup_CIOM_oLIN04_Tx_04202f7b_BswMReportFailToDemRef.GetEventStatus
        OpEventGetEventStatus_GetEventStatus_EvtInfo_AutoCreatedDemEvent_CC_DisablePDUGroup_CIOM_oLIN04_Rx_527a88fd_BswMReportF_a576a540: start-on-event=DemSatellite_OsApplication_Untrusted_Core0InternalBehavior/GetEventStatus, operation=EvtInfo_AutoCreatedDemEvent_CC_DisablePDUGroup_CIOM_oLIN04_Rx_527a88fd_BswMReportFailToDemRef.GetEventStatus
        OpEventGetEventStatus_GetEventStatus_EvtInfo_AutoCreatedDemEvent_CC_DisablePDUGroup_CIOM_oLIN01_Tx_33fedf49_BswMReportF_176c69c7: start-on-event=DemSatellite_OsApplication_Untrusted_Core0InternalBehavior/GetEventStatus, operation=EvtInfo_AutoCreatedDemEvent_CC_DisablePDUGroup_CIOM_oLIN01_Tx_33fedf49_BswMReportFailToDemRef.GetEventStatus
        OpEventGetEventStatus_GetEventStatus_EvtInfo_AutoCreatedDemEvent_CC_DisablePDUGroup_CIOM_oLIN01_Rx_65a478cf_BswMReportF_295cc34d: start-on-event=DemSatellite_OsApplication_Untrusted_Core0InternalBehavior/GetEventStatus, operation=EvtInfo_AutoCreatedDemEvent_CC_DisablePDUGroup_CIOM_oLIN01_Rx_65a478cf_BswMReportFailToDemRef.GetEventStatus
        OpEventGetEventStatus_GetEventStatus_EvtInfo_AutoCreatedDemEvent_CC_EnablePDUGroup_CIOM_oLIN04_Tx_04202f7b_BswMReportFa_673b8640: start-on-event=DemSatellite_OsApplication_Untrusted_Core0InternalBehavior/GetEventStatus, operation=EvtInfo_AutoCreatedDemEvent_CC_EnablePDUGroup_CIOM_oLIN04_Tx_04202f7b_BswMReportFailToDemRef.GetEventStatus
        OpEventGetEventStatus_GetEventStatus_EvtInfo_AutoCreatedDemEvent_CC_EnablePDUGroup_CIOM_oLIN04_Rx_527a88fd_BswMReportFa_ae99e3be: start-on-event=DemSatellite_OsApplication_Untrusted_Core0InternalBehavior/GetEventStatus, operation=EvtInfo_AutoCreatedDemEvent_CC_EnablePDUGroup_CIOM_oLIN04_Rx_527a88fd_BswMReportFailToDemRef.GetEventStatus
        OpEventGetEventStatus_GetEventStatus_EvtInfo_AutoCreatedDemEvent_CC_DisableDM_CIOM_oBackbone2_Rx_4e624434_BswMReportFailToDemRef: start-on-event=DemSatellite_OsApplication_Untrusted_Core0InternalBehavior/GetEventStatus, operation=EvtInfo_AutoCreatedDemEvent_CC_DisableDM_CIOM_oBackbone2_Rx_4e624434_BswMReportFailToDemRef.GetEventStatus
        OpEventGetEventStatus_GetEventStatus_EvtInfo_AutoCreatedDemEvent_CC_EnableDM_CIOM_oBackbone2_Rx_4e624434_BswMReportFailToDemRef: start-on-event=DemSatellite_OsApplication_Untrusted_Core0InternalBehavior/GetEventStatus, operation=EvtInfo_AutoCreatedDemEvent_CC_EnableDM_CIOM_oBackbone2_Rx_4e624434_BswMReportFailToDemRef.GetEventStatus
        OpEventGetEventStatus_GetEventStatus_EvtInfo_AutoCreatedDemEvent_CC_DisableDM_CIOM_oSecuritySubnet_Rx_3a3c1dbc_BswMRepo_eba21d43: start-on-event=DemSatellite_OsApplication_Untrusted_Core0InternalBehavior/GetEventStatus, operation=EvtInfo_AutoCreatedDemEvent_CC_DisableDM_CIOM_oSecuritySubnet_Rx_3a3c1dbc_BswMReportFailToDemRef.GetEventStatus
        OpEventGetEventStatus_GetEventStatus_EvtInfo_AutoCreatedDemEvent_CC_EnableDM_CIOM_oSecuritySubnet_Rx_3a3c1dbc_BswMRepor_c26e54f8: start-on-event=DemSatellite_OsApplication_Untrusted_Core0InternalBehavior/GetEventStatus, operation=EvtInfo_AutoCreatedDemEvent_CC_EnableDM_CIOM_oSecuritySubnet_Rx_3a3c1dbc_BswMReportFailToDemRef.GetEventStatus
        OpEventGetEventStatus_GetEventStatus_EvtInfo_AutoCreatedDemEvent_CC_DisablePDUGroup_CIOM_oCabSubnet_Tx_5060f83a_BswMRep_ca8f85aa: start-on-event=DemSatellite_OsApplication_Untrusted_Core0InternalBehavior/GetEventStatus, operation=EvtInfo_AutoCreatedDemEvent_CC_DisablePDUGroup_CIOM_oCabSubnet_Tx_5060f83a_BswMReportFailToDemRef.GetEventStatus
        OpEventGetEventStatus_GetEventStatus_EvtInfo_AutoCreatedDemEvent_CC_EnablePDUGroup_CIOM_oCabSubnet_Tx_5060f83a_BswMRepo_961523e7: start-on-event=DemSatellite_OsApplication_Untrusted_Core0InternalBehavior/GetEventStatus, operation=EvtInfo_AutoCreatedDemEvent_CC_EnablePDUGroup_CIOM_oCabSubnet_Tx_5060f83a_BswMReportFailToDemRef.GetEventStatus
        OpEventGetEventStatus_GetEventStatus_EvtInfo_AutoCreatedDemEvent_CC_EnableDM_CIOM_oCabSubnet_Rx_063a5fbc_BswMReportFailToDemRef: start-on-event=DemSatellite_OsApplication_Untrusted_Core0InternalBehavior/GetEventStatus, operation=EvtInfo_AutoCreatedDemEvent_CC_EnableDM_CIOM_oCabSubnet_Rx_063a5fbc_BswMReportFailToDemRef.GetEventStatus
        OpEventGetEventStatus_GetEventStatus_EvtInfo_AutoCreatedDemEvent_CC_DisablePDUGroup_CIOM_oBackbone2_Tx_1838e3b2_BswMRep_a8d21884: start-on-event=DemSatellite_OsApplication_Untrusted_Core0InternalBehavior/GetEventStatus, operation=EvtInfo_AutoCreatedDemEvent_CC_DisablePDUGroup_CIOM_oBackbone2_Tx_1838e3b2_BswMReportFailToDemRef.GetEventStatus
        OpEventGetEventStatus_GetEventStatus_EvtInfo_AutoCreatedDemEvent_CC_EnablePDUGroup_CIOM_oBackbone2_Tx_1838e3b2_BswMRepo_f448bec9: start-on-event=DemSatellite_OsApplication_Untrusted_Core0InternalBehavior/GetEventStatus, operation=EvtInfo_AutoCreatedDemEvent_CC_EnablePDUGroup_CIOM_oBackbone2_Tx_1838e3b2_BswMReportFailToDemRef.GetEventStatus
        OpEventGetEventStatus_GetEventStatus_EvtInfo_AutoCreatedDemEvent_CC_DisablePDUGroup_CIOM_oBackbone2_Rx_4e624434_BswMRep_5da6b90e: start-on-event=DemSatellite_OsApplication_Untrusted_Core0InternalBehavior/GetEventStatus, operation=EvtInfo_AutoCreatedDemEvent_CC_DisablePDUGroup_CIOM_oBackbone2_Rx_4e624434_BswMReportFailToDemRef.GetEventStatus
        OpEventGetEventStatus_GetEventStatus_EvtInfo_AutoCreatedDemEvent_CC_EnablePDUGroup_CIOM_oBackbone2_Rx_4e624434_BswMRepo_013c1f43: start-on-event=DemSatellite_OsApplication_Untrusted_Core0InternalBehavior/GetEventStatus, operation=EvtInfo_AutoCreatedDemEvent_CC_EnablePDUGroup_CIOM_oBackbone2_Rx_4e624434_BswMReportFailToDemRef.GetEventStatus
        OpEventGetEventStatus_GetEventStatus_EvtInfo_AutoCreatedDemEvent_CC_DisablePDUGroup_CIOM_oBackbone1J1939_Rx_BC_405bc776_1d0c0d41: start-on-event=DemSatellite_OsApplication_Untrusted_Core0InternalBehavior/GetEventStatus, operation=EvtInfo_AutoCreatedDemEvent_CC_DisablePDUGroup_CIOM_oBackbone1J1939_Rx_BC_405bc776_BswMReportFailToDemRef.GetEventStatus
        OpEventGetEventStatus_GetEventStatus_EvtInfo_AutoCreatedDemEvent_CC_EnablePDUGroup_CIOM_oBackbone1J1939_Rx_BC_405bc776_caf12bc6: start-on-event=DemSatellite_OsApplication_Untrusted_Core0InternalBehavior/GetEventStatus, operation=EvtInfo_AutoCreatedDemEvent_CC_EnablePDUGroup_CIOM_oBackbone1J1939_Rx_BC_405bc776_BswMReportFailToDemRef.GetEventStatus
        OpEventGetEventStatus_GetEventStatus_EvtInfo_AutoCreatedDemEvent_CC_EnablePDUGroup_CIOM_oLIN02_Tx_214b70a7_BswMReportFa_fd134c2a: start-on-event=DemSatellite_OsApplication_Untrusted_Core0InternalBehavior/GetEventStatus, operation=EvtInfo_AutoCreatedDemEvent_CC_EnablePDUGroup_CIOM_oLIN02_Tx_214b70a7_BswMReportFailToDemRef.GetEventStatus
        OpEventGetEventStatus_GetEventStatus_EvtInfo_AutoCreatedDemEvent_CC_EnablePDUGroup_CIOM_oLIN02_Rx_7711d721_BswMReportFa_2bd98f48: start-on-event=DemSatellite_OsApplication_Untrusted_Core0InternalBehavior/GetEventStatus, operation=EvtInfo_AutoCreatedDemEvent_CC_EnablePDUGroup_CIOM_oLIN02_Rx_7711d721_BswMReportFailToDemRef.GetEventStatus
        OpEventGetEventStatus_GetEventStatus_EvtInfo_AutoCreatedDemEvent_CC_EnablePDUGroup_CIOM_oLIN01_Tx_33fedf49_BswMReportFa_1c832f39: start-on-event=DemSatellite_OsApplication_Untrusted_Core0InternalBehavior/GetEventStatus, operation=EvtInfo_AutoCreatedDemEvent_CC_EnablePDUGroup_CIOM_oLIN01_Tx_33fedf49_BswMReportFailToDemRef.GetEventStatus
        OpEventGetEventStatus_GetEventStatus_EvtInfo_AutoCreatedDemEvent_CC_EnablePDUGroup_CIOM_oLIN01_Rx_65a478cf_BswMReportFa_22b385b3: start-on-event=DemSatellite_OsApplication_Untrusted_Core0InternalBehavior/GetEventStatus, operation=EvtInfo_AutoCreatedDemEvent_CC_EnablePDUGroup_CIOM_oLIN01_Rx_65a478cf_BswMReportFailToDemRef.GetEventStatus
        OpEventGetEventStatus_GetEventStatus_EvtInfo_AutoCreatedDemEvent_CC_DisablePDUGroup_CIOM_oLIN03_Tx_99f717c2_BswMReportF_6406da1c: start-on-event=DemSatellite_OsApplication_Untrusted_Core0InternalBehavior/GetEventStatus, operation=EvtInfo_AutoCreatedDemEvent_CC_DisablePDUGroup_CIOM_oLIN03_Tx_99f717c2_BswMReportFailToDemRef.GetEventStatus
        OpEventGetEventStatus_GetEventStatus_EvtInfo_AutoCreatedDemEvent_CC_DisablePDUGroup_CIOM_oLIN03_Rx_cfadb044_BswMReportF_5dabbfe2: start-on-event=DemSatellite_OsApplication_Untrusted_Core0InternalBehavior/GetEventStatus, operation=EvtInfo_AutoCreatedDemEvent_CC_DisablePDUGroup_CIOM_oLIN03_Rx_cfadb044_BswMReportFailToDemRef.GetEventStatus
        OpEventGetEventStatus_GetEventStatus_EvtInfo_AutoCreatedDemEvent_CC_DisableDM_CIOM_oFMSNet_Rx_BC_dd2c1510_BswMReportFailToDemRef: start-on-event=DemSatellite_OsApplication_Untrusted_Core0InternalBehavior/GetEventStatus, operation=EvtInfo_AutoCreatedDemEvent_CC_DisableDM_CIOM_oFMSNet_Rx_BC_dd2c1510_BswMReportFailToDemRef.GetEventStatus
        OpEventGetEventStatus_GetEventStatus_EvtInfo_AutoCreatedDemEvent_CC_EnableDM_CIOM_oFMSNet_Rx_BC_dd2c1510_BswMReportFailToDemRef: start-on-event=DemSatellite_OsApplication_Untrusted_Core0InternalBehavior/GetEventStatus, operation=EvtInfo_AutoCreatedDemEvent_CC_EnableDM_CIOM_oFMSNet_Rx_BC_dd2c1510_BswMReportFailToDemRef.GetEventStatus
        OpEventGetEventStatus_GetEventStatus_EvtInfo_AutoCreatedDemEvent_CC_EnablePDUGroup_CIOM_oLIN03_Tx_99f717c2_BswMReportFa_6fe99ce2: start-on-event=DemSatellite_OsApplication_Untrusted_Core0InternalBehavior/GetEventStatus, operation=EvtInfo_AutoCreatedDemEvent_CC_EnablePDUGroup_CIOM_oLIN03_Tx_99f717c2_BswMReportFailToDemRef.GetEventStatus
        OpEventGetEventStatus_GetEventStatus_EvtInfo_AutoCreatedDemEvent_CC_EnablePDUGroup_CIOM_oLIN03_Rx_cfadb044_BswMReportFa_5644f91c: start-on-event=DemSatellite_OsApplication_Untrusted_Core0InternalBehavior/GetEventStatus, operation=EvtInfo_AutoCreatedDemEvent_CC_EnablePDUGroup_CIOM_oLIN03_Rx_cfadb044_BswMReportFailToDemRef.GetEventStatus
        OpEventGetEventStatus_GetEventStatus_EvtInfo_AutoCreatedDemEvent_CC_DisablePDUGroup_CIOM_oLIN02_Tx_214b70a7_BswMReportF_f6fc0ad4: start-on-event=DemSatellite_OsApplication_Untrusted_Core0InternalBehavior/GetEventStatus, operation=EvtInfo_AutoCreatedDemEvent_CC_DisablePDUGroup_CIOM_oLIN02_Tx_214b70a7_BswMReportFailToDemRef.GetEventStatus
        OpEventGetEventStatus_GetEventStatus_EvtInfo_AutoCreatedDemEvent_CC_DisablePDUGroup_CIOM_oLIN02_Rx_7711d721_BswMReportF_2036c9b6: start-on-event=DemSatellite_OsApplication_Untrusted_Core0InternalBehavior/GetEventStatus, operation=EvtInfo_AutoCreatedDemEvent_CC_DisablePDUGroup_CIOM_oLIN02_Rx_7711d721_BswMReportFailToDemRef.GetEventStatus
        OpEventGetEventStatus_GetEventStatus_EvtInfo_AutoCreatedDemEvent_CC_DisablePDUGroup_CIOM_oCabSubnet_Rx_063a5fbc_BswMRep_3af2b380: start-on-event=DemSatellite_OsApplication_Untrusted_Core0InternalBehavior/GetEventStatus, operation=EvtInfo_AutoCreatedDemEvent_CC_DisablePDUGroup_CIOM_oCabSubnet_Rx_063a5fbc_BswMReportFailToDemRef.GetEventStatus
        OpEventGetEventStatus_GetEventStatus_EvtInfo_AutoCreatedDemEvent_CC_EnablePDUGroup_CIOM_oCabSubnet_Rx_063a5fbc_BswMRepo_666815cd: start-on-event=DemSatellite_OsApplication_Untrusted_Core0InternalBehavior/GetEventStatus, operation=EvtInfo_AutoCreatedDemEvent_CC_EnablePDUGroup_CIOM_oCabSubnet_Rx_063a5fbc_BswMReportFailToDemRef.GetEventStatus
        OpEventGetEventStatus_GetEventStatus_EvtInfo_AutoCreatedDemEvent_CC_DisablePDUGroup_CIOM_oFMSNet_Rx_BC_dd2c1510_BswMRep_72052b5d: start-on-event=DemSatellite_OsApplication_Untrusted_Core0InternalBehavior/GetEventStatus, operation=EvtInfo_AutoCreatedDemEvent_CC_DisablePDUGroup_CIOM_oFMSNet_Rx_BC_dd2c1510_BswMReportFailToDemRef.GetEventStatus
        OpEventGetEventStatus_GetEventStatus_EvtInfo_AutoCreatedDemEvent_CC_EnablePDUGroup_CIOM_oFMSNet_Rx_BC_dd2c1510_BswMRepo_2e9f8d10: start-on-event=DemSatellite_OsApplication_Untrusted_Core0InternalBehavior/GetEventStatus, operation=EvtInfo_AutoCreatedDemEvent_CC_EnablePDUGroup_CIOM_oFMSNet_Rx_BC_dd2c1510_BswMReportFailToDemRef.GetEventStatus
        OpEventGetEventStatus_GetEventStatus_EvtInfo_AutoCreatedDemEvent_CC_DisablePDUGroup_CIOM_oSecuritySubnet_Rx_3a3c1dbc_Bs_b51956ff: start-on-event=DemSatellite_OsApplication_Untrusted_Core0InternalBehavior/GetEventStatus, operation=EvtInfo_AutoCreatedDemEvent_CC_DisablePDUGroup_CIOM_oSecuritySubnet_Rx_3a3c1dbc_BswMReportFailToDemRef.GetEventStatus
        OpEventGetEventStatus_GetEventStatus_EvtInfo_AutoCreatedDemEvent_CC_EnablePDUGroup_CIOM_oSecuritySubnet_Rx_3a3c1dbc_Bsw_9bf0a3a0: start-on-event=DemSatellite_OsApplication_Untrusted_Core0InternalBehavior/GetEventStatus, operation=EvtInfo_AutoCreatedDemEvent_CC_EnablePDUGroup_CIOM_oSecuritySubnet_Rx_3a3c1dbc_BswMReportFailToDemRef.GetEventStatus
        OpEventGetEventStatus_GetEventStatus_EvtInfo_AutoCreatedDemEvent_CC_DisablePDUGroup_CIOM_oFMSNet_Tx_0x31_BC_38fc8c7d_Bs_9a7bfbf2: start-on-event=DemSatellite_OsApplication_Untrusted_Core0InternalBehavior/GetEventStatus, operation=EvtInfo_AutoCreatedDemEvent_CC_DisablePDUGroup_CIOM_oFMSNet_Tx_0x31_BC_38fc8c7d_BswMReportFailToDemRef.GetEventStatus
        OpEventGetEventStatus_GetEventStatus_EvtInfo_AutoCreatedDemEvent_CC_EnablePDUGroup_CIOM_oFMSNet_Tx_0x31_BC_38fc8c7d_Bsw_b4920ead: start-on-event=DemSatellite_OsApplication_Untrusted_Core0InternalBehavior/GetEventStatus, operation=EvtInfo_AutoCreatedDemEvent_CC_EnablePDUGroup_CIOM_oFMSNet_Tx_0x31_BC_38fc8c7d_BswMReportFailToDemRef.GetEventStatus
        OpEventGetEventStatus_GetEventStatus_EvtInfo_AutoCreatedDemEvent_CC_DisablePDUGroup_CIOM_oSecuritySubnet_Tx_6c66ba3a_Bs_7bc6e49e: start-on-event=DemSatellite_OsApplication_Untrusted_Core0InternalBehavior/GetEventStatus, operation=EvtInfo_AutoCreatedDemEvent_CC_DisablePDUGroup_CIOM_oSecuritySubnet_Tx_6c66ba3a_BswMReportFailToDemRef.GetEventStatus
        OpEventGetEventStatus_GetEventStatus_EvtInfo_AutoCreatedDemEvent_CC_EnablePDUGroup_CIOM_oSecuritySubnet_Tx_6c66ba3a_Bsw_552f11c1: start-on-event=DemSatellite_OsApplication_Untrusted_Core0InternalBehavior/GetEventStatus, operation=EvtInfo_AutoCreatedDemEvent_CC_EnablePDUGroup_CIOM_oSecuritySubnet_Tx_6c66ba3a_BswMReportFailToDemRef.GetEventStatus
        OpEventGetEventStatus_GetEventStatus_EvtInfo_AutoCreatedDemEvent_CC_DisablePDUGroup_CIOM_oLIN00_Tx_8b42b82c_BswMReportF_776507bd: start-on-event=DemSatellite_OsApplication_Untrusted_Core0InternalBehavior/GetEventStatus, operation=EvtInfo_AutoCreatedDemEvent_CC_DisablePDUGroup_CIOM_oLIN00_Tx_8b42b82c_BswMReportFailToDemRef.GetEventStatus
        OpEventGetEventStatus_GetEventStatus_EvtInfo_AutoCreatedDemEvent_CC_EnablePDUGroup_CIOM_oLIN00_Rx_dd181faa_BswMReportFa_fd7e33e0: start-on-event=DemSatellite_OsApplication_Untrusted_Core0InternalBehavior/GetEventStatus, operation=EvtInfo_AutoCreatedDemEvent_CC_EnablePDUGroup_CIOM_oLIN00_Rx_dd181faa_BswMReportFailToDemRef.GetEventStatus
        OpEventGetEventStatus_GetEventStatus_EvtInfo_AutoCreatedDemEvent_ESH_Action_ComMCheckPendingRequests_BswMReportFailToDemRef: start-on-event=DemSatellite_OsApplication_Untrusted_Core0InternalBehavior/GetEventStatus, operation=EvtInfo_AutoCreatedDemEvent_ESH_Action_ComMCheckPendingRequests_BswMReportFailToDemRef.GetEventStatus
        OpEventGetEventStatus_GetEventStatus_EvtInfo_AutoCreatedDemEvent_CC_DisableDM_CIOM_oBackbone1J1939_Rx_BC_405bc776_BswMR_9e76f6a1: start-on-event=DemSatellite_OsApplication_Untrusted_Core0InternalBehavior/GetEventStatus, operation=EvtInfo_AutoCreatedDemEvent_CC_DisableDM_CIOM_oBackbone1J1939_Rx_BC_405bc776_BswMReportFailToDemRef.GetEventStatus
        OpEventGetEventStatus_GetEventStatus_EvtInfo_AutoCreatedDemEvent_CC_DisablePDUGroup_CIOM_oLIN00_Rx_dd181faa_BswMReportF_f691751e: start-on-event=DemSatellite_OsApplication_Untrusted_Core0InternalBehavior/GetEventStatus, operation=EvtInfo_AutoCreatedDemEvent_CC_DisablePDUGroup_CIOM_oLIN00_Rx_dd181faa_BswMReportFailToDemRef.GetEventStatus
        OpEventGetEventStatus_GetEventStatus_EvtInfo_AutoCreatedDemEvent_CC_EnablePDUGroup_CIOM_oLIN00_Tx_8b42b82c_BswMReportFa_7c8a4143: start-on-event=DemSatellite_OsApplication_Untrusted_Core0InternalBehavior/GetEventStatus, operation=EvtInfo_AutoCreatedDemEvent_CC_EnablePDUGroup_CIOM_oLIN00_Tx_8b42b82c_BswMReportFailToDemRef.GetEventStatus
        OpEventGetEventStatus_GetEventStatus_EvtInfo_AutoCreatedDemEvent_ESH_Action_EnterExclusiveArea_BswMReportFailToDemRef: start-on-event=DemSatellite_OsApplication_Untrusted_Core0InternalBehavior/GetEventStatus, operation=EvtInfo_AutoCreatedDemEvent_ESH_Action_EnterExclusiveArea_BswMReportFailToDemRef.GetEventStatus
        OpEventGetEventStatus_GetEventStatus_EvtInfo_AutoCreatedDemEvent_ESH_RunToPostRunNested_BswMReportFailToDemRef: start-on-event=DemSatellite_OsApplication_Untrusted_Core0InternalBehavior/GetEventStatus, operation=EvtInfo_AutoCreatedDemEvent_ESH_RunToPostRunNested_BswMReportFailToDemRef.GetEventStatus
        OpEventGetEventStatus_GetEventStatus_EvtInfo_AutoCreatedDemEvent_CC_EnableDM_CIOM_oBackbone1J1939_Rx_BC_405bc776_BswMRe_e4149dae: start-on-event=DemSatellite_OsApplication_Untrusted_Core0InternalBehavior/GetEventStatus, operation=EvtInfo_AutoCreatedDemEvent_CC_EnableDM_CIOM_oBackbone1J1939_Rx_BC_405bc776_BswMReportFailToDemRef.GetEventStatus
        OpEventGetEventStatus_GetEventStatus_EvtInfo_AutoCreatedDemEvent_CC_DisablePDUGroup_CIOM_oBackbone1J1939_Tx_0x31_BC_378_220e99b9: start-on-event=DemSatellite_OsApplication_Untrusted_Core0InternalBehavior/GetEventStatus, operation=EvtInfo_AutoCreatedDemEvent_CC_DisablePDUGroup_CIOM_oBackbone1J1939_Tx_0x31_BC_3782f500_BswMReportFailToDemRef.GetEventStatus
        OpEventGetEventStatus_GetEventStatus_EvtInfo_AutoCreatedDemEvent_CC_J1939RmStateSwitch_CN_FMSNet_fce1aae5_CIOM_3a3d59b1_6dc77de5: start-on-event=DemSatellite_OsApplication_Untrusted_Core0InternalBehavior/GetEventStatus, operation=EvtInfo_AutoCreatedDemEvent_CC_J1939RmStateSwitch_CN_FMSNet_fce1aae5_CIOM_3a3d59b1_J1939RM_STATE_OFFLINE_BswMReportFailToDemRef.GetEventStatus
        OpEventGetEventStatus_GetEventStatus_EvtInfo_AutoCreatedDemEvent_CC_EnablePDUGroup_CIOM_oBackbone1J1939_Tx_0x31_BC_3782_d7f4b682: start-on-event=DemSatellite_OsApplication_Untrusted_Core0InternalBehavior/GetEventStatus, operation=EvtInfo_AutoCreatedDemEvent_CC_EnablePDUGroup_CIOM_oBackbone1J1939_Tx_0x31_BC_3782f500_BswMReportFailToDemRef.GetEventStatus
        OpEventGetEventStatus_GetEventStatus_EvtInfo_AutoCreatedDemEvent_CC_J1939RmStateSwitch_CN_FMSNet_fce1aae5_CIOM_3a3d59b1_c0dfaecc: start-on-event=DemSatellite_OsApplication_Untrusted_Core0InternalBehavior/GetEventStatus, operation=EvtInfo_AutoCreatedDemEvent_CC_J1939RmStateSwitch_CN_FMSNet_fce1aae5_CIOM_3a3d59b1_J1939RM_STATE_ONLINE_BswMReportFailToDemRef.GetEventStatus
        OpEventGetEventStatus_GetEventStatus_EvtInfo_AutoCreatedDemEvent_ESH_Action_CancelNvMWriteAll_BswMReportFailToDemRef: start-on-event=DemSatellite_OsApplication_Untrusted_Core0InternalBehavior/GetEventStatus, operation=EvtInfo_AutoCreatedDemEvent_ESH_Action_CancelNvMWriteAll_BswMReportFailToDemRef.GetEventStatus
        OpEventGetEventStatus_GetEventStatus_EvtInfo_AutoCreatedDemEvent_ESH_Action_CancelWriteAllTimer_Start_BswMReportFailToDemRef: start-on-event=DemSatellite_OsApplication_Untrusted_Core0InternalBehavior/GetEventStatus, operation=EvtInfo_AutoCreatedDemEvent_ESH_Action_CancelWriteAllTimer_Start_BswMReportFailToDemRef.GetEventStatus
        OpEventGetEventStatus_GetEventStatus_EvtInfo_AutoCreatedDemEvent_ESH_Action_CancelWriteAllTimer_Stop_BswMReportFailToDemRef: start-on-event=DemSatellite_OsApplication_Untrusted_Core0InternalBehavior/GetEventStatus, operation=EvtInfo_AutoCreatedDemEvent_ESH_Action_CancelWriteAllTimer_Stop_BswMReportFailToDemRef.GetEventStatus
        OpEventGetEventStatus_GetEventStatus_EvtInfo_AutoCreatedDemEvent_ESH_Action_ComMAllow_CN_Backbone1J1939_0b1f4bae_BswMRe_7a36a6b9: start-on-event=DemSatellite_OsApplication_Untrusted_Core0InternalBehavior/GetEventStatus, operation=EvtInfo_AutoCreatedDemEvent_ESH_Action_ComMAllow_CN_Backbone1J1939_0b1f4bae_BswMReportFailToDemRef.GetEventStatus
        OpEventGetEventStatus_GetEventStatus_EvtInfo_AutoCreatedDemEvent_ESH_Action_ComMAllow_CN_Backbone1J1939_0b1f4bae_BswMRe_27963a44: start-on-event=DemSatellite_OsApplication_Untrusted_Core0InternalBehavior/GetEventStatus, operation=EvtInfo_AutoCreatedDemEvent_ESH_Action_ComMAllow_CN_Backbone1J1939_0b1f4bae_BswMReportFailToDemRef_1.GetEventStatus
        OpEventGetEventStatus_GetEventStatus_EvtInfo_AutoCreatedDemEvent_ESH_Action_ComMAllow_CN_Backbone2_78967e2c_BswMReportF_bc5d0a2a: start-on-event=DemSatellite_OsApplication_Untrusted_Core0InternalBehavior/GetEventStatus, operation=EvtInfo_AutoCreatedDemEvent_ESH_Action_ComMAllow_CN_Backbone2_78967e2c_BswMReportFailToDemRef.GetEventStatus
        OpEventGetEventStatus_GetEventStatus_EvtInfo_AutoCreatedDemEvent_ESH_Action_ComMAllow_CN_Backbone2_78967e2c_BswMReportF_a29aca35: start-on-event=DemSatellite_OsApplication_Untrusted_Core0InternalBehavior/GetEventStatus, operation=EvtInfo_AutoCreatedDemEvent_ESH_Action_ComMAllow_CN_Backbone2_78967e2c_BswMReportFailToDemRef_1.GetEventStatus
        OpEventGetEventStatus_GetEventStatus_EvtInfo_AutoCreatedDemEvent_ESH_Action_ComMAllow_CN_CabSubnet_9ea693f1_BswMReportF_619f3c5c: start-on-event=DemSatellite_OsApplication_Untrusted_Core0InternalBehavior/GetEventStatus, operation=EvtInfo_AutoCreatedDemEvent_ESH_Action_ComMAllow_CN_CabSubnet_9ea693f1_BswMReportFailToDemRef.GetEventStatus
        OpEventGetEventStatus_GetEventStatus_EvtInfo_AutoCreatedDemEvent_ESH_Action_ComMAllow_CN_CabSubnet_9ea693f1_BswMReportF_14455c1e: start-on-event=DemSatellite_OsApplication_Untrusted_Core0InternalBehavior/GetEventStatus, operation=EvtInfo_AutoCreatedDemEvent_ESH_Action_ComMAllow_CN_CabSubnet_9ea693f1_BswMReportFailToDemRef_1.GetEventStatus
        OpEventGetEventStatus_GetEventStatus_EvtInfo_AutoCreatedDemEvent_ESH_Action_ComMAllow_CN_FMSNet_fce1aae5_BswMReportFailToDemRef: start-on-event=DemSatellite_OsApplication_Untrusted_Core0InternalBehavior/GetEventStatus, operation=EvtInfo_AutoCreatedDemEvent_ESH_Action_ComMAllow_CN_FMSNet_fce1aae5_BswMReportFailToDemRef.GetEventStatus
        OpEventGetEventStatus_GetEventStatus_EvtInfo_AutoCreatedDemEvent_ESH_Action_ComMAllow_CN_FMSNet_fce1aae5_BswMReportFail_07074ac1: start-on-event=DemSatellite_OsApplication_Untrusted_Core0InternalBehavior/GetEventStatus, operation=EvtInfo_AutoCreatedDemEvent_ESH_Action_ComMAllow_CN_FMSNet_fce1aae5_BswMReportFailToDemRef_1.GetEventStatus
        OpEventGetEventStatus_GetEventStatus_EvtInfo_AutoCreatedDemEvent_ESH_Action_ComMAllow_CN_LIN00_2cd9a7df_BswMReportFailToDemRef: start-on-event=DemSatellite_OsApplication_Untrusted_Core0InternalBehavior/GetEventStatus, operation=EvtInfo_AutoCreatedDemEvent_ESH_Action_ComMAllow_CN_LIN00_2cd9a7df_BswMReportFailToDemRef.GetEventStatus
        OpEventGetEventStatus_GetEventStatus_EvtInfo_AutoCreatedDemEvent_ESH_Action_ComMAllow_CN_LIN00_2cd9a7df_BswMReportFailToDemRef_1: start-on-event=DemSatellite_OsApplication_Untrusted_Core0InternalBehavior/GetEventStatus, operation=EvtInfo_AutoCreatedDemEvent_ESH_Action_ComMAllow_CN_LIN00_2cd9a7df_BswMReportFailToDemRef_1.GetEventStatus
        OpEventGetEventStatus_GetEventStatus_EvtInfo_AutoCreatedDemEvent_ESH_Action_ComMAllow_CN_LIN01_5bde9749_BswMReportFailToDemRef: start-on-event=DemSatellite_OsApplication_Untrusted_Core0InternalBehavior/GetEventStatus, operation=EvtInfo_AutoCreatedDemEvent_ESH_Action_ComMAllow_CN_LIN01_5bde9749_BswMReportFailToDemRef.GetEventStatus
        OpEventGetEventStatus_GetEventStatus_EvtInfo_AutoCreatedDemEvent_ESH_Action_ComMAllow_CN_LIN01_5bde9749_BswMReportFailToDemRef_1: start-on-event=DemSatellite_OsApplication_Untrusted_Core0InternalBehavior/GetEventStatus, operation=EvtInfo_AutoCreatedDemEvent_ESH_Action_ComMAllow_CN_LIN01_5bde9749_BswMReportFailToDemRef_1.GetEventStatus
        OpEventGetEventStatus_GetEventStatus_EvtInfo_AutoCreatedDemEvent_ESH_Action_ComMAllow_CN_LIN02_c2d7c6f3_BswMReportFailToDemRef: start-on-event=DemSatellite_OsApplication_Untrusted_Core0InternalBehavior/GetEventStatus, operation=EvtInfo_AutoCreatedDemEvent_ESH_Action_ComMAllow_CN_LIN02_c2d7c6f3_BswMReportFailToDemRef.GetEventStatus
        OpEventGetEventStatus_GetEventStatus_EvtInfo_AutoCreatedDemEvent_ESH_Action_ComMAllow_CN_LIN02_c2d7c6f3_BswMReportFailToDemRef_1: start-on-event=DemSatellite_OsApplication_Untrusted_Core0InternalBehavior/GetEventStatus, operation=EvtInfo_AutoCreatedDemEvent_ESH_Action_ComMAllow_CN_LIN02_c2d7c6f3_BswMReportFailToDemRef_1.GetEventStatus
        OpEventGetEventStatus_GetEventStatus_EvtInfo_AutoCreatedDemEvent_ESH_Action_ComMAllow_CN_LIN03_b5d0f665_BswMReportFailToDemRef: start-on-event=DemSatellite_OsApplication_Untrusted_Core0InternalBehavior/GetEventStatus, operation=EvtInfo_AutoCreatedDemEvent_ESH_Action_ComMAllow_CN_LIN03_b5d0f665_BswMReportFailToDemRef.GetEventStatus
        OpEventGetEventStatus_GetEventStatus_EvtInfo_AutoCreatedDemEvent_ESH_Action_ComMAllow_CN_LIN03_b5d0f665_BswMReportFailToDemRef_1: start-on-event=DemSatellite_OsApplication_Untrusted_Core0InternalBehavior/GetEventStatus, operation=EvtInfo_AutoCreatedDemEvent_ESH_Action_ComMAllow_CN_LIN03_b5d0f665_BswMReportFailToDemRef_1.GetEventStatus
        OpEventGetEventStatus_GetEventStatus_EvtInfo_AutoCreatedDemEvent_ESH_Action_ComMAllow_CN_LIN04_2bb463c6_BswMReportFailToDemRef: start-on-event=DemSatellite_OsApplication_Untrusted_Core0InternalBehavior/GetEventStatus, operation=EvtInfo_AutoCreatedDemEvent_ESH_Action_ComMAllow_CN_LIN04_2bb463c6_BswMReportFailToDemRef.GetEventStatus
        OpEventGetEventStatus_GetEventStatus_EvtInfo_AutoCreatedDemEvent_ESH_Action_ComMAllow_CN_LIN04_2bb463c6_BswMReportFailToDemRef_1: start-on-event=DemSatellite_OsApplication_Untrusted_Core0InternalBehavior/GetEventStatus, operation=EvtInfo_AutoCreatedDemEvent_ESH_Action_ComMAllow_CN_LIN04_2bb463c6_BswMReportFailToDemRef_1.GetEventStatus
        OpEventGetEventStatus_GetEventStatus_EvtInfo_AutoCreatedDemEvent_ESH_Action_ComMAllow_CN_SecuritySubnet_e7a0ee54_BswMRe_d4bc277f: start-on-event=DemSatellite_OsApplication_Untrusted_Core0InternalBehavior/GetEventStatus, operation=EvtInfo_AutoCreatedDemEvent_ESH_Action_ComMAllow_CN_SecuritySubnet_e7a0ee54_BswMReportFailToDemRef.GetEventStatus
        OpEventGetEventStatus_GetEventStatus_EvtInfo_AutoCreatedDemEvent_ESH_Action_ComMAllow_CN_SecuritySubnet_e7a0ee54_BswMRe_208957b0: start-on-event=DemSatellite_OsApplication_Untrusted_Core0InternalBehavior/GetEventStatus, operation=EvtInfo_AutoCreatedDemEvent_ESH_Action_ComMAllow_CN_SecuritySubnet_e7a0ee54_BswMReportFailToDemRef_1.GetEventStatus
        OpEventGetEventStatus_GetEventStatus_EvtInfo_AutoCreatedDemEvent_ESH_Action_ComMCheckPendingRequests_BswMReportFailToDemRef_1: start-on-event=DemSatellite_OsApplication_Untrusted_Core0InternalBehavior/GetEventStatus, operation=EvtInfo_AutoCreatedDemEvent_ESH_Action_ComMCheckPendingRequests_BswMReportFailToDemRef_1.GetEventStatus
        OpEventGetEventStatus_GetEventStatus_EvtInfo_AutoCreatedDemEvent_ESH_Action_ComMCheckPendingRequests_BswMReportFailToDemRef_2: start-on-event=DemSatellite_OsApplication_Untrusted_Core0InternalBehavior/GetEventStatus, operation=EvtInfo_AutoCreatedDemEvent_ESH_Action_ComMCheckPendingRequests_BswMReportFailToDemRef_2.GetEventStatus
        OpEventGetEventStatus_GetEventStatus_EvtInfo_AutoCreatedDemEvent_ESH_Action_ComMDisallow_CN_Backbone1J1939_0b1f4bae_Bsw_87577ca7: start-on-event=DemSatellite_OsApplication_Untrusted_Core0InternalBehavior/GetEventStatus, operation=EvtInfo_AutoCreatedDemEvent_ESH_Action_ComMDisallow_CN_Backbone1J1939_0b1f4bae_BswMReportFailToDemRef.GetEventStatus
        OpEventGetEventStatus_GetEventStatus_EvtInfo_AutoCreatedDemEvent_ESH_Action_ComMDisallow_CN_Backbone2_78967e2c_BswMRepo_0adfe113: start-on-event=DemSatellite_OsApplication_Untrusted_Core0InternalBehavior/GetEventStatus, operation=EvtInfo_AutoCreatedDemEvent_ESH_Action_ComMDisallow_CN_Backbone2_78967e2c_BswMReportFailToDemRef.GetEventStatus
        OpEventGetEventStatus_GetEventStatus_EvtInfo_AutoCreatedDemEvent_ESH_Action_ComMDisallow_CN_CabSubnet_9ea693f1_BswMRepo_d71dd765: start-on-event=DemSatellite_OsApplication_Untrusted_Core0InternalBehavior/GetEventStatus, operation=EvtInfo_AutoCreatedDemEvent_ESH_Action_ComMDisallow_CN_CabSubnet_9ea693f1_BswMReportFailToDemRef.GetEventStatus
        OpEventGetEventStatus_GetEventStatus_EvtInfo_AutoCreatedDemEvent_ESH_Action_ComMDisallow_CN_FMSNet_fce1aae5_BswMReportF_477ea913: start-on-event=DemSatellite_OsApplication_Untrusted_Core0InternalBehavior/GetEventStatus, operation=EvtInfo_AutoCreatedDemEvent_ESH_Action_ComMDisallow_CN_FMSNet_fce1aae5_BswMReportFailToDemRef.GetEventStatus
        OpEventGetEventStatus_GetEventStatus_EvtInfo_AutoCreatedDemEvent_ESH_Action_ComMDisallow_CN_LIN00_2cd9a7df_BswMReportFa_fd113374: start-on-event=DemSatellite_OsApplication_Untrusted_Core0InternalBehavior/GetEventStatus, operation=EvtInfo_AutoCreatedDemEvent_ESH_Action_ComMDisallow_CN_LIN00_2cd9a7df_BswMReportFailToDemRef.GetEventStatus
        OpEventGetEventStatus_GetEventStatus_EvtInfo_AutoCreatedDemEvent_ESH_Action_ComMDisallow_CN_LIN01_5bde9749_BswMReportFa_c5a1b4a8: start-on-event=DemSatellite_OsApplication_Untrusted_Core0InternalBehavior/GetEventStatus, operation=EvtInfo_AutoCreatedDemEvent_ESH_Action_ComMDisallow_CN_LIN01_5bde9749_BswMReportFailToDemRef.GetEventStatus
        OpEventGetEventStatus_GetEventStatus_EvtInfo_AutoCreatedDemEvent_ESH_Action_ComMDisallow_CN_LIN02_c2d7c6f3_BswMReportFa_38dc48cc: start-on-event=DemSatellite_OsApplication_Untrusted_Core0InternalBehavior/GetEventStatus, operation=EvtInfo_AutoCreatedDemEvent_ESH_Action_ComMDisallow_CN_LIN02_c2d7c6f3_BswMReportFailToDemRef.GetEventStatus
        OpEventGetEventStatus_GetEventStatus_EvtInfo_AutoCreatedDemEvent_ESH_Action_ComMDisallow_CN_LIN03_b5d0f665_BswMReportFa_ed28f446: start-on-event=DemSatellite_OsApplication_Untrusted_Core0InternalBehavior/GetEventStatus, operation=EvtInfo_AutoCreatedDemEvent_ESH_Action_ComMDisallow_CN_LIN03_b5d0f665_BswMReportFailToDemRef.GetEventStatus
        OpEventGetEventStatus_GetEventStatus_EvtInfo_AutoCreatedDemEvent_ESH_Action_ComMDisallow_CN_LIN04_2bb463c6_BswMReportFa_12660b90: start-on-event=DemSatellite_OsApplication_Untrusted_Core0InternalBehavior/GetEventStatus, operation=EvtInfo_AutoCreatedDemEvent_ESH_Action_ComMDisallow_CN_LIN04_2bb463c6_BswMReportFailToDemRef.GetEventStatus
        OpEventGetEventStatus_GetEventStatus_EvtInfo_AutoCreatedDemEvent_ESH_Action_ComMDisallow_CN_SecuritySubnet_e7a0ee54_Bsw_29ddfd61: start-on-event=DemSatellite_OsApplication_Untrusted_Core0InternalBehavior/GetEventStatus, operation=EvtInfo_AutoCreatedDemEvent_ESH_Action_ComMDisallow_CN_SecuritySubnet_e7a0ee54_BswMReportFailToDemRef.GetEventStatus
        OpEventGetEventStatus_GetEventStatus_EvtInfo_AutoCreatedDemEvent_ESH_Action_DemInit_BswMReportFailToDemRef: start-on-event=DemSatellite_OsApplication_Untrusted_Core0InternalBehavior/GetEventStatus, operation=EvtInfo_AutoCreatedDemEvent_ESH_Action_DemInit_BswMReportFailToDemRef.GetEventStatus
        OpEventGetEventStatus_GetEventStatus_EvtInfo_AutoCreatedDemEvent_ESH_Action_DemInitialized_BswMReportFailToDemRef: start-on-event=DemSatellite_OsApplication_Untrusted_Core0InternalBehavior/GetEventStatus, operation=EvtInfo_AutoCreatedDemEvent_ESH_Action_DemInitialized_BswMReportFailToDemRef.GetEventStatus
        OpEventGetEventStatus_GetEventStatus_EvtInfo_AutoCreatedDemEvent_ESH_Action_DemNotInitialized_BswMReportFailToDemRef: start-on-event=DemSatellite_OsApplication_Untrusted_Core0InternalBehavior/GetEventStatus, operation=EvtInfo_AutoCreatedDemEvent_ESH_Action_DemNotInitialized_BswMReportFailToDemRef.GetEventStatus
        OpEventGetEventStatus_GetEventStatus_EvtInfo_AutoCreatedDemEvent_ESH_Action_DemShutdown_BswMReportFailToDemRef: start-on-event=DemSatellite_OsApplication_Untrusted_Core0InternalBehavior/GetEventStatus, operation=EvtInfo_AutoCreatedDemEvent_ESH_Action_DemShutdown_BswMReportFailToDemRef.GetEventStatus
        OpEventGetEventStatus_GetEventStatus_EvtInfo_AutoCreatedDemEvent_ESH_Action_ESH_PostRun_BswMReportFailToDemRef: start-on-event=DemSatellite_OsApplication_Untrusted_Core0InternalBehavior/GetEventStatus, operation=EvtInfo_AutoCreatedDemEvent_ESH_Action_ESH_PostRun_BswMReportFailToDemRef.GetEventStatus
        OpEventGetEventStatus_GetEventStatus_EvtInfo_AutoCreatedDemEvent_ESH_Action_ESH_PrepShutdown_BswMReportFailToDemRef: start-on-event=DemSatellite_OsApplication_Untrusted_Core0InternalBehavior/GetEventStatus, operation=EvtInfo_AutoCreatedDemEvent_ESH_Action_ESH_PrepShutdown_BswMReportFailToDemRef.GetEventStatus
        OpEventGetEventStatus_GetEventStatus_EvtInfo_AutoCreatedDemEvent_ESH_Action_ESH_PrepShutdown_BswMReportFailToDemRef_1: start-on-event=DemSatellite_OsApplication_Untrusted_Core0InternalBehavior/GetEventStatus, operation=EvtInfo_AutoCreatedDemEvent_ESH_Action_ESH_PrepShutdown_BswMReportFailToDemRef_1.GetEventStatus
        OpEventGetEventStatus_GetEventStatus_EvtInfo_AutoCreatedDemEvent_ESH_Action_ESH_Run_BswMReportFailToDemRef: start-on-event=DemSatellite_OsApplication_Untrusted_Core0InternalBehavior/GetEventStatus, operation=EvtInfo_AutoCreatedDemEvent_ESH_Action_ESH_Run_BswMReportFailToDemRef.GetEventStatus
        OpEventGetEventStatus_GetEventStatus_EvtInfo_AutoCreatedDemEvent_ESH_Action_ESH_Run_BswMReportFailToDemRef_1: start-on-event=DemSatellite_OsApplication_Untrusted_Core0InternalBehavior/GetEventStatus, operation=EvtInfo_AutoCreatedDemEvent_ESH_Action_ESH_Run_BswMReportFailToDemRef_1.GetEventStatus
        OpEventGetEventStatus_GetEventStatus_EvtInfo_AutoCreatedDemEvent_ESH_Action_ESH_WaitForNvm_BswMReportFailToDemRef: start-on-event=DemSatellite_OsApplication_Untrusted_Core0InternalBehavior/GetEventStatus, operation=EvtInfo_AutoCreatedDemEvent_ESH_Action_ESH_WaitForNvm_BswMReportFailToDemRef.GetEventStatus
        OpEventGetEventStatus_GetEventStatus_EvtInfo_AutoCreatedDemEvent_ESH_Action_ESH_Wakeup_BswMReportFailToDemRef: start-on-event=DemSatellite_OsApplication_Untrusted_Core0InternalBehavior/GetEventStatus, operation=EvtInfo_AutoCreatedDemEvent_ESH_Action_ESH_Wakeup_BswMReportFailToDemRef.GetEventStatus
        OpEventGetEventStatus_GetEventStatus_EvtInfo_AutoCreatedDemEvent_ESH_Action_ESH_Wakeup_BswMReportFailToDemRef_1: start-on-event=DemSatellite_OsApplication_Untrusted_Core0InternalBehavior/GetEventStatus, operation=EvtInfo_AutoCreatedDemEvent_ESH_Action_ESH_Wakeup_BswMReportFailToDemRef_1.GetEventStatus
        OpEventGetEventStatus_GetEventStatus_EvtInfo_AutoCreatedDemEvent_ESH_Action_EcuMClearValidatedWakeupEvents_BswMReportFa_f43646e1: start-on-event=DemSatellite_OsApplication_Untrusted_Core0InternalBehavior/GetEventStatus, operation=EvtInfo_AutoCreatedDemEvent_ESH_Action_EcuMClearValidatedWakeupEvents_BswMReportFailToDemRef.GetEventStatus
        OpEventGetEventStatus_GetEventStatus_EvtInfo_AutoCreatedDemEvent_ESH_Action_EcuMGoToSelectedShutdownTarget_BswMReportFa_557cf637: start-on-event=DemSatellite_OsApplication_Untrusted_Core0InternalBehavior/GetEventStatus, operation=EvtInfo_AutoCreatedDemEvent_ESH_Action_EcuMGoToSelectedShutdownTarget_BswMReportFailToDemRef.GetEventStatus
        OpEventGetEventStatus_GetEventStatus_EvtInfo_AutoCreatedDemEvent_ESH_Action_EnterExclusiveArea_BswMReportFailToDemRef_1: start-on-event=DemSatellite_OsApplication_Untrusted_Core0InternalBehavior/GetEventStatus, operation=EvtInfo_AutoCreatedDemEvent_ESH_Action_EnterExclusiveArea_BswMReportFailToDemRef_1.GetEventStatus
        OpEventGetEventStatus_GetEventStatus_EvtInfo_AutoCreatedDemEvent_ESH_Action_ExitExclusiveArea_BswMReportFailToDemRef: start-on-event=DemSatellite_OsApplication_Untrusted_Core0InternalBehavior/GetEventStatus, operation=EvtInfo_AutoCreatedDemEvent_ESH_Action_ExitExclusiveArea_BswMReportFailToDemRef.GetEventStatus
        OpEventGetEventStatus_GetEventStatus_EvtInfo_AutoCreatedDemEvent_ESH_Action_NvMWriteAll_BswMReportFailToDemRef: start-on-event=DemSatellite_OsApplication_Untrusted_Core0InternalBehavior/GetEventStatus, operation=EvtInfo_AutoCreatedDemEvent_ESH_Action_NvMWriteAll_BswMReportFailToDemRef.GetEventStatus
        OpEventGetEventStatus_GetEventStatus_EvtInfo_AutoCreatedDemEvent_ESH_Action_OnEnterPostRun_BswMReportFailToDemRef: start-on-event=DemSatellite_OsApplication_Untrusted_Core0InternalBehavior/GetEventStatus, operation=EvtInfo_AutoCreatedDemEvent_ESH_Action_OnEnterPostRun_BswMReportFailToDemRef.GetEventStatus
        OpEventGetEventStatus_GetEventStatus_EvtInfo_AutoCreatedDemEvent_ESH_Action_OnEnterPrepShutdown_BswMReportFailToDemRef: start-on-event=DemSatellite_OsApplication_Untrusted_Core0InternalBehavior/GetEventStatus, operation=EvtInfo_AutoCreatedDemEvent_ESH_Action_OnEnterPrepShutdown_BswMReportFailToDemRef.GetEventStatus
        OpEventGetEventStatus_GetEventStatus_EvtInfo_AutoCreatedDemEvent_ESH_Action_OnEnterPrepShutdown_BswMReportFailToDemRef_1: start-on-event=DemSatellite_OsApplication_Untrusted_Core0InternalBehavior/GetEventStatus, operation=EvtInfo_AutoCreatedDemEvent_ESH_Action_OnEnterPrepShutdown_BswMReportFailToDemRef_1.GetEventStatus
        OpEventGetEventStatus_GetEventStatus_EvtInfo_AutoCreatedDemEvent_ESH_Action_OnEnterRun_BswMReportFailToDemRef: start-on-event=DemSatellite_OsApplication_Untrusted_Core0InternalBehavior/GetEventStatus, operation=EvtInfo_AutoCreatedDemEvent_ESH_Action_OnEnterRun_BswMReportFailToDemRef.GetEventStatus
        OpEventGetEventStatus_GetEventStatus_EvtInfo_AutoCreatedDemEvent_ESH_Action_OnEnterRun_BswMReportFailToDemRef_1: start-on-event=DemSatellite_OsApplication_Untrusted_Core0InternalBehavior/GetEventStatus, operation=EvtInfo_AutoCreatedDemEvent_ESH_Action_OnEnterRun_BswMReportFailToDemRef_1.GetEventStatus
        OpEventGetEventStatus_GetEventStatus_EvtInfo_AutoCreatedDemEvent_ESH_Action_OnEnterShutdown_BswMReportFailToDemRef: start-on-event=DemSatellite_OsApplication_Untrusted_Core0InternalBehavior/GetEventStatus, operation=EvtInfo_AutoCreatedDemEvent_ESH_Action_OnEnterShutdown_BswMReportFailToDemRef.GetEventStatus
        OpEventGetEventStatus_GetEventStatus_EvtInfo_AutoCreatedDemEvent_ESH_Action_OnEnterWaitForNvm_BswMReportFailToDemRef: start-on-event=DemSatellite_OsApplication_Untrusted_Core0InternalBehavior/GetEventStatus, operation=EvtInfo_AutoCreatedDemEvent_ESH_Action_OnEnterWaitForNvm_BswMReportFailToDemRef.GetEventStatus
        OpEventGetEventStatus_GetEventStatus_EvtInfo_AutoCreatedDemEvent_ESH_Action_OnEnterWakeup_BswMReportFailToDemRef: start-on-event=DemSatellite_OsApplication_Untrusted_Core0InternalBehavior/GetEventStatus, operation=EvtInfo_AutoCreatedDemEvent_ESH_Action_OnEnterWakeup_BswMReportFailToDemRef.GetEventStatus
        OpEventGetEventStatus_GetEventStatus_EvtInfo_AutoCreatedDemEvent_ESH_Action_OnEnterWakeup_BswMReportFailToDemRef_1: start-on-event=DemSatellite_OsApplication_Untrusted_Core0InternalBehavior/GetEventStatus, operation=EvtInfo_AutoCreatedDemEvent_ESH_Action_OnEnterWakeup_BswMReportFailToDemRef_1.GetEventStatus
        OpEventGetEventStatus_GetEventStatus_EvtInfo_AutoCreatedDemEvent_ESH_Action_SelfRunRequestTimer_Start_BswMReportFailToDemRef: start-on-event=DemSatellite_OsApplication_Untrusted_Core0InternalBehavior/GetEventStatus, operation=EvtInfo_AutoCreatedDemEvent_ESH_Action_SelfRunRequestTimer_Start_BswMReportFailToDemRef.GetEventStatus
        OpEventGetEventStatus_GetEventStatus_EvtInfo_AutoCreatedDemEvent_ESH_Action_SelfRunRequestTimer_Start_BswMReportFailToDemRef_1: start-on-event=DemSatellite_OsApplication_Untrusted_Core0InternalBehavior/GetEventStatus, operation=EvtInfo_AutoCreatedDemEvent_ESH_Action_SelfRunRequestTimer_Start_BswMReportFailToDemRef_1.GetEventStatus
        OpEventGetEventStatus_GetEventStatus_EvtInfo_AutoCreatedDemEvent_ESH_Action_SwitchPostRun_BswMReportFailToDemRef: start-on-event=DemSatellite_OsApplication_Untrusted_Core0InternalBehavior/GetEventStatus, operation=EvtInfo_AutoCreatedDemEvent_ESH_Action_SwitchPostRun_BswMReportFailToDemRef.GetEventStatus
        OpEventGetEventStatus_GetEventStatus_EvtInfo_AutoCreatedDemEvent_ESH_Action_SwitchRun_BswMReportFailToDemRef: start-on-event=DemSatellite_OsApplication_Untrusted_Core0InternalBehavior/GetEventStatus, operation=EvtInfo_AutoCreatedDemEvent_ESH_Action_SwitchRun_BswMReportFailToDemRef.GetEventStatus
        OpEventGetEventStatus_GetEventStatus_EvtInfo_AutoCreatedDemEvent_ESH_Action_SwitchRun_BswMReportFailToDemRef_1: start-on-event=DemSatellite_OsApplication_Untrusted_Core0InternalBehavior/GetEventStatus, operation=EvtInfo_AutoCreatedDemEvent_ESH_Action_SwitchRun_BswMReportFailToDemRef_1.GetEventStatus
        OpEventGetEventStatus_GetEventStatus_EvtInfo_AutoCreatedDemEvent_ESH_Action_SwitchShutdown_BswMReportFailToDemRef: start-on-event=DemSatellite_OsApplication_Untrusted_Core0InternalBehavior/GetEventStatus, operation=EvtInfo_AutoCreatedDemEvent_ESH_Action_SwitchShutdown_BswMReportFailToDemRef.GetEventStatus
        OpEventGetEventStatus_GetEventStatus_EvtInfo_AutoCreatedDemEvent_ESH_Action_SwitchShutdown_BswMReportFailToDemRef_1: start-on-event=DemSatellite_OsApplication_Untrusted_Core0InternalBehavior/GetEventStatus, operation=EvtInfo_AutoCreatedDemEvent_ESH_Action_SwitchShutdown_BswMReportFailToDemRef_1.GetEventStatus
        OpEventGetEventStatus_GetEventStatus_EvtInfo_AutoCreatedDemEvent_ESH_Action_SwitchWakeup_BswMReportFailToDemRef: start-on-event=DemSatellite_OsApplication_Untrusted_Core0InternalBehavior/GetEventStatus, operation=EvtInfo_AutoCreatedDemEvent_ESH_Action_SwitchWakeup_BswMReportFailToDemRef.GetEventStatus
        OpEventGetEventStatus_GetEventStatus_EvtInfo_AutoCreatedDemEvent_ESH_Action_SwitchWakeup_BswMReportFailToDemRef_1: start-on-event=DemSatellite_OsApplication_Untrusted_Core0InternalBehavior/GetEventStatus, operation=EvtInfo_AutoCreatedDemEvent_ESH_Action_SwitchWakeup_BswMReportFailToDemRef_1.GetEventStatus
        OpEventGetEventStatus_GetEventStatus_EvtInfo_AutoCreatedDemEvent_ESH_Action_WriteAllTimer_Start_BswMReportFailToDemRef: start-on-event=DemSatellite_OsApplication_Untrusted_Core0InternalBehavior/GetEventStatus, operation=EvtInfo_AutoCreatedDemEvent_ESH_Action_WriteAllTimer_Start_BswMReportFailToDemRef.GetEventStatus
        OpEventGetEventStatus_GetEventStatus_EvtInfo_AutoCreatedDemEvent_ESH_Action_WriteAllTimer_Stop_BswMReportFailToDemRef: start-on-event=DemSatellite_OsApplication_Untrusted_Core0InternalBehavior/GetEventStatus, operation=EvtInfo_AutoCreatedDemEvent_ESH_Action_WriteAllTimer_Stop_BswMReportFailToDemRef.GetEventStatus
        OpEventGetEventStatus_GetEventStatus_EvtInfo_AutoCreatedDemEvent_ESH_Action_WriteAllTimer_Stop_BswMReportFailToDemRef_1: start-on-event=DemSatellite_OsApplication_Untrusted_Core0InternalBehavior/GetEventStatus, operation=EvtInfo_AutoCreatedDemEvent_ESH_Action_WriteAllTimer_Stop_BswMReportFailToDemRef_1.GetEventStatus
        OpEventGetEventStatus_GetEventStatus_EvtInfo_AutoCreatedDemEvent_ESH_DemInit_BswMReportFailToDemRef: start-on-event=DemSatellite_OsApplication_Untrusted_Core0InternalBehavior/GetEventStatus, operation=EvtInfo_AutoCreatedDemEvent_ESH_DemInit_BswMReportFailToDemRef.GetEventStatus
        OpEventGetEventStatus_GetEventStatus_EvtInfo_AutoCreatedDemEvent_ESH_PostRunNested_BswMReportFailToDemRef: start-on-event=DemSatellite_OsApplication_Untrusted_Core0InternalBehavior/GetEventStatus, operation=EvtInfo_AutoCreatedDemEvent_ESH_PostRunNested_BswMReportFailToDemRef.GetEventStatus
        OpEventGetEventStatus_GetEventStatus_EvtInfo_AutoCreatedDemEvent_ESH_PostRunToPrepNested_BswMReportFailToDemRef: start-on-event=DemSatellite_OsApplication_Untrusted_Core0InternalBehavior/GetEventStatus, operation=EvtInfo_AutoCreatedDemEvent_ESH_PostRunToPrepNested_BswMReportFailToDemRef.GetEventStatus
        OpEventGetEventStatus_GetEventStatus_EvtInfo_AutoCreatedDemEvent_ESH_Action_ExitExclusiveArea_BswMReportFailToDemRef_1: start-on-event=DemSatellite_OsApplication_Untrusted_Core0InternalBehavior/GetEventStatus, operation=EvtInfo_AutoCreatedDemEvent_ESH_Action_ExitExclusiveArea_BswMReportFailToDemRef_1.GetEventStatus
        OpEventGetEventStatus_GetEventStatus_EvtInfo_AutoCreatedDemEvent_INIT_Action_BrsHw_EnableHwAccess_BswMReportFailToDemRef: start-on-event=DemSatellite_OsApplication_Untrusted_Core0InternalBehavior/GetEventStatus, operation=EvtInfo_AutoCreatedDemEvent_INIT_Action_BrsHw_EnableHwAccess_BswMReportFailToDemRef.GetEventStatus
        OpEventGetEventStatus_GetEventStatus_EvtInfo_AutoCreatedDemEvent_INIT_Action_CanIf_Init_BswMReportFailToDemRef: start-on-event=DemSatellite_OsApplication_Untrusted_Core0InternalBehavior/GetEventStatus, operation=EvtInfo_AutoCreatedDemEvent_INIT_Action_CanIf_Init_BswMReportFailToDemRef.GetEventStatus
        OpEventGetEventStatus_GetEventStatus_EvtInfo_AutoCreatedDemEvent_INIT_Action_CanNm_Init_BswMReportFailToDemRef: start-on-event=DemSatellite_OsApplication_Untrusted_Core0InternalBehavior/GetEventStatus, operation=EvtInfo_AutoCreatedDemEvent_INIT_Action_CanNm_Init_BswMReportFailToDemRef.GetEventStatus
        OpEventGetEventStatus_GetEventStatus_EvtInfo_AutoCreatedDemEvent_INIT_Action_CanSM_Init_BswMReportFailToDemRef: start-on-event=DemSatellite_OsApplication_Untrusted_Core0InternalBehavior/GetEventStatus, operation=EvtInfo_AutoCreatedDemEvent_INIT_Action_CanSM_Init_BswMReportFailToDemRef.GetEventStatus
        OpEventGetEventStatus_GetEventStatus_EvtInfo_AutoCreatedDemEvent_INIT_Action_CanTp_Init_BswMReportFailToDemRef: start-on-event=DemSatellite_OsApplication_Untrusted_Core0InternalBehavior/GetEventStatus, operation=EvtInfo_AutoCreatedDemEvent_INIT_Action_CanTp_Init_BswMReportFailToDemRef.GetEventStatus
        OpEventGetEventStatus_GetEventStatus_EvtInfo_AutoCreatedDemEvent_INIT_Action_Can_Init_BswMReportFailToDemRef: start-on-event=DemSatellite_OsApplication_Untrusted_Core0InternalBehavior/GetEventStatus, operation=EvtInfo_AutoCreatedDemEvent_INIT_Action_Can_Init_BswMReportFailToDemRef.GetEventStatus
        OpEventGetEventStatus_GetEventStatus_EvtInfo_AutoCreatedDemEvent_INIT_Action_ComM_Init_BswMReportFailToDemRef: start-on-event=DemSatellite_OsApplication_Untrusted_Core0InternalBehavior/GetEventStatus, operation=EvtInfo_AutoCreatedDemEvent_INIT_Action_ComM_Init_BswMReportFailToDemRef.GetEventStatus
        OpEventGetEventStatus_GetEventStatus_EvtInfo_AutoCreatedDemEvent_INIT_Action_Com_Init_BswMReportFailToDemRef: start-on-event=DemSatellite_OsApplication_Untrusted_Core0InternalBehavior/GetEventStatus, operation=EvtInfo_AutoCreatedDemEvent_INIT_Action_Com_Init_BswMReportFailToDemRef.GetEventStatus
        OpEventGetEventStatus_GetEventStatus_EvtInfo_AutoCreatedDemEvent_INIT_Action_Dcm_Init_BswMReportFailToDemRef: start-on-event=DemSatellite_OsApplication_Untrusted_Core0InternalBehavior/GetEventStatus, operation=EvtInfo_AutoCreatedDemEvent_INIT_Action_Dcm_Init_BswMReportFailToDemRef.GetEventStatus
        OpEventGetEventStatus_GetEventStatus_EvtInfo_AutoCreatedDemEvent_INIT_Action_Dem_Init_BswMReportFailToDemRef: start-on-event=DemSatellite_OsApplication_Untrusted_Core0InternalBehavior/GetEventStatus, operation=EvtInfo_AutoCreatedDemEvent_INIT_Action_Dem_Init_BswMReportFailToDemRef.GetEventStatus
        OpEventGetEventStatus_GetEventStatus_EvtInfo_AutoCreatedDemEvent_INIT_Action_EnableInterrupts_BswMReportFailToDemRef: start-on-event=DemSatellite_OsApplication_Untrusted_Core0InternalBehavior/GetEventStatus, operation=EvtInfo_AutoCreatedDemEvent_INIT_Action_EnableInterrupts_BswMReportFailToDemRef.GetEventStatus
        OpEventGetEventStatus_GetEventStatus_EvtInfo_AutoCreatedDemEvent_INIT_Action_Fee_Init_BswMReportFailToDemRef: start-on-event=DemSatellite_OsApplication_Untrusted_Core0InternalBehavior/GetEventStatus, operation=EvtInfo_AutoCreatedDemEvent_INIT_Action_Fee_Init_BswMReportFailToDemRef.GetEventStatus
        OpEventGetEventStatus_GetEventStatus_EvtInfo_AutoCreatedDemEvent_INIT_Action_Issm_Init_BswMReportFailToDemRef: start-on-event=DemSatellite_OsApplication_Untrusted_Core0InternalBehavior/GetEventStatus, operation=EvtInfo_AutoCreatedDemEvent_INIT_Action_Issm_Init_BswMReportFailToDemRef.GetEventStatus
        OpEventGetEventStatus_GetEventStatus_EvtInfo_AutoCreatedDemEvent_INIT_Action_J1939Nm_Init_BswMReportFailToDemRef: start-on-event=DemSatellite_OsApplication_Untrusted_Core0InternalBehavior/GetEventStatus, operation=EvtInfo_AutoCreatedDemEvent_INIT_Action_J1939Nm_Init_BswMReportFailToDemRef.GetEventStatus
        OpEventGetEventStatus_GetEventStatus_EvtInfo_AutoCreatedDemEvent_INIT_Action_J1939Rm_Init_BswMReportFailToDemRef: start-on-event=DemSatellite_OsApplication_Untrusted_Core0InternalBehavior/GetEventStatus, operation=EvtInfo_AutoCreatedDemEvent_INIT_Action_J1939Rm_Init_BswMReportFailToDemRef.GetEventStatus
        OpEventGetEventStatus_GetEventStatus_EvtInfo_AutoCreatedDemEvent_INIT_Action_J1939Tp_Init_BswMReportFailToDemRef: start-on-event=DemSatellite_OsApplication_Untrusted_Core0InternalBehavior/GetEventStatus, operation=EvtInfo_AutoCreatedDemEvent_INIT_Action_J1939Tp_Init_BswMReportFailToDemRef.GetEventStatus
        OpEventGetEventStatus_GetEventStatus_EvtInfo_AutoCreatedDemEvent_INIT_Action_LinIf_Init_BswMReportFailToDemRef: start-on-event=DemSatellite_OsApplication_Untrusted_Core0InternalBehavior/GetEventStatus, operation=EvtInfo_AutoCreatedDemEvent_INIT_Action_LinIf_Init_BswMReportFailToDemRef.GetEventStatus
        OpEventGetEventStatus_GetEventStatus_EvtInfo_AutoCreatedDemEvent_INIT_Action_LinSM_Init_BswMReportFailToDemRef: start-on-event=DemSatellite_OsApplication_Untrusted_Core0InternalBehavior/GetEventStatus, operation=EvtInfo_AutoCreatedDemEvent_INIT_Action_LinSM_Init_BswMReportFailToDemRef.GetEventStatus
        OpEventGetEventStatus_GetEventStatus_EvtInfo_AutoCreatedDemEvent_INIT_Action_LinTp_Init_BswMReportFailToDemRef: start-on-event=DemSatellite_OsApplication_Untrusted_Core0InternalBehavior/GetEventStatus, operation=EvtInfo_AutoCreatedDemEvent_INIT_Action_LinTp_Init_BswMReportFailToDemRef.GetEventStatus
        OpEventGetEventStatus_GetEventStatus_EvtInfo_AutoCreatedDemEvent_INIT_Action_Lin_Init_BswMReportFailToDemRef: start-on-event=DemSatellite_OsApplication_Untrusted_Core0InternalBehavior/GetEventStatus, operation=EvtInfo_AutoCreatedDemEvent_INIT_Action_Lin_Init_BswMReportFailToDemRef.GetEventStatus
